VERSION "created by canmatrix"

NS_ :

BS_:

BU_: TCM iBooster HCU CIM SCM Right_Hand_Control Left_Hand_Control GPS VCM IC_2 XM GMRS Radio_CANtool Diagnostic_Tool_Digital_Wrench Information_System_Controller_1 STEERING_CONTROLLER VEHICLE_SECURITY RADIO_Hub ABS Battery_Management_Cntrl_2 Battery_Management_Cntrl_1 Auxiliary_Power_Unit_2 Auxiliary_Power_Unit_1 Electric_Propulsion_Cntrl_Unit_4 Electric_Propulsion_Cntrl_Unit_3 Electric_Propulsion_Cntrl_Unit_2 Electric_Propulsion_Cntrl_Unit_1 ECM IC

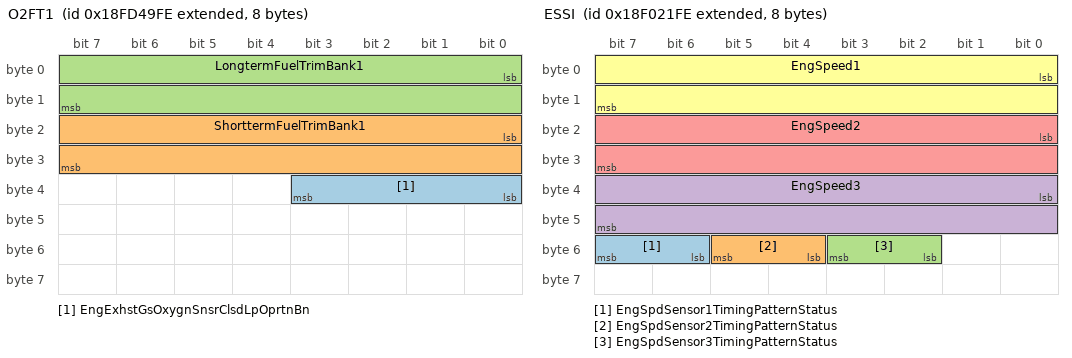
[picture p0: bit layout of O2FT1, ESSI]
BO_ 2566736382 O2FT1: 8 Vector__XXX
 SG_ EngExhstGsOxygnSnsrClsdLpOprtnBn : 32|4@1+ (1,0) [0.0|15.0] "" Vector__XXX
 SG_ ShorttermFuelTrimBank1 : 16|16@1+ (0.1,-100) [-100.0|100.0] "%" Vector__XXX
 SG_ LongtermFuelTrimBank1 : 0|16@1+ (0.1,-100) [-100.0|100.0] "%" Vector__XXX

BO_ 2565874174 ESSI: 8 Vector__XXX
 SG_ EngSpdSensor1TimingPatternStatus : 54|2@1+ (1,0) [0.0|3.0] "" Vector__XXX
 SG_ EngSpdSensor2TimingPatternStatus : 52|2@1+ (1,0) [0.0|3.0] "" Vector__XXX
 SG_ EngSpdSensor3TimingPatternStatus : 50|2@1+ (1,0) [0.0|3.0] "" Vector__XXX
 SG_ EngSpeed3 : 32|16@1+ (0.5,0) [0.0|32127.5] "rpm" Vector__XXX
 SG_ EngSpeed2 : 16|16@1+ (0.5,0) [0.0|32127.5] "rpm" Vector__XXX
 SG_ EngSpeed1 : 0|16@1+ (0.5,0) [0.0|32127.5] "rpm" Vector__XXX

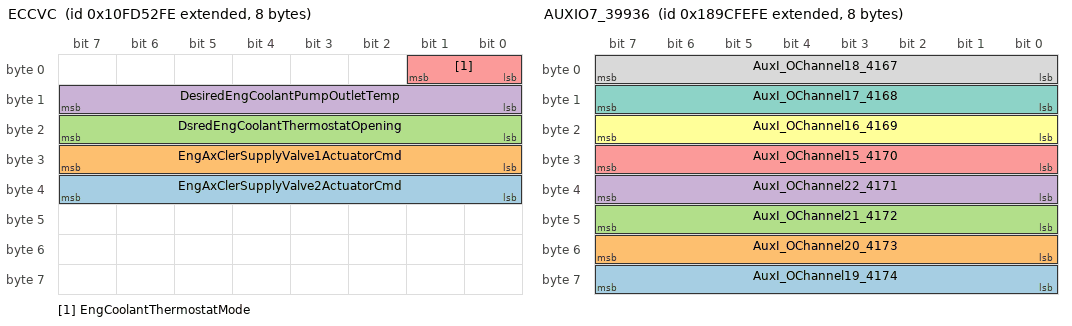
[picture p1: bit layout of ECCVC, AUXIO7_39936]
BO_ 2432520958 ECCVC: 8 Vector__XXX
 SG_ EngAxClerSupplyValve2ActuatorCmd : 32|8@1+ (0.4,0) [0.0|100.0] "%" Vector__XXX
 SG_ EngAxClerSupplyValve1ActuatorCmd : 24|8@1+ (0.4,0) [0.0|100.0] "%" Vector__XXX
 SG_ DsredEngCoolantThermostatOpening : 16|8@1+ (0.4,0) [0.0|100.0] "%" Vector__XXX
 SG_ DesiredEngCoolantPumpOutletTemp : 8|8@1+ (1,-40) [-40.0|210.0] "°C" Vector__XXX
 SG_ EngCoolantThermostatMode : 0|2@1+ (1,0) [0.0|3.0] "" Vector__XXX

BO_ 2560425726 AUXIO7_39936: 8 Vector__XXX
 SG_ AuxI_OChannel19_4174 : 56|8@1+ (1,0) [0.0|250.0] "" Vector__XXX
 SG_ AuxI_OChannel20_4173 : 48|8@1+ (1,0) [0.0|250.0] "" Vector__XXX
 SG_ AuxI_OChannel21_4172 : 40|8@1+ (1,0) [0.0|250.0] "" Vector__XXX
 SG_ AuxI_OChannel22_4171 : 32|8@1+ (1,0) [0.0|250.0] "" Vector__XXX
 SG_ AuxI_OChannel15_4170 : 24|8@1+ (1,0) [0.0|250.0] "" Vector__XXX
 SG_ AuxI_OChannel16_4169 : 16|8@1+ (1,0) [0.0|250.0] "" Vector__XXX
 SG_ AuxI_OChannel17_4168 : 8|8@1+ (1,0) [0.0|250.0] "" Vector__XXX
 SG_ AuxI_OChannel18_4167 : 0|8@1+ (1,0) [0.0|250.0] "" Vector__XXX

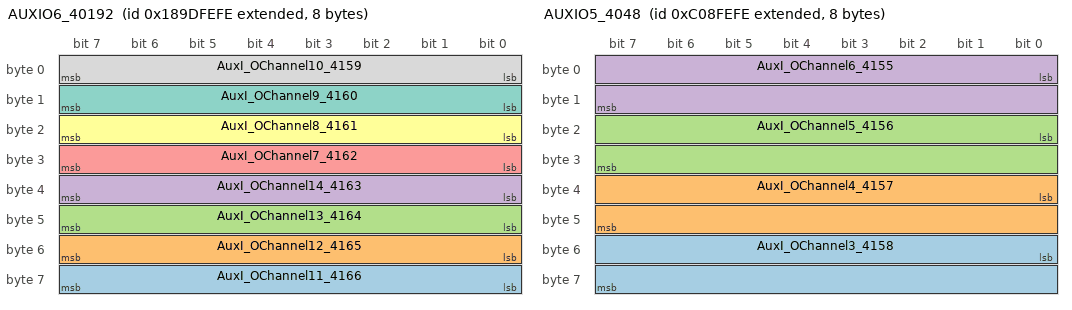
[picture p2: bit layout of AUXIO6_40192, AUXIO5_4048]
BO_ 2560491262 AUXIO6_40192: 8 Vector__XXX
 SG_ AuxI_OChannel11_4166 : 56|8@1+ (1,0) [0.0|250.0] "" Vector__XXX
 SG_ AuxI_OChannel12_4165 : 48|8@1+ (1,0) [0.0|250.0] "" Vector__XXX
 SG_ AuxI_OChannel13_4164 : 40|8@1+ (1,0) [0.0|250.0] "" Vector__XXX
 SG_ AuxI_OChannel14_4163 : 32|8@1+ (1,0) [0.0|250.0] "" Vector__XXX
 SG_ AuxI_OChannel7_4162 : 24|8@1+ (1,0) [0.0|250.0] "" Vector__XXX
 SG_ AuxI_OChannel8_4161 : 16|8@1+ (1,0) [0.0|250.0] "" Vector__XXX
 SG_ AuxI_OChannel9_4160 : 8|8@1+ (1,0) [0.0|250.0] "" Vector__XXX
 SG_ AuxI_OChannel10_4159 : 0|8@1+ (1,0) [0.0|250.0] "" Vector__XXX

BO_ 2349399806 AUXIO5_4048: 8 Vector__XXX
 SG_ AuxI_OChannel3_4158 : 48|16@1+ (1,0) [0.0|64255.0] "" Vector__XXX
 SG_ AuxI_OChannel4_4157 : 32|16@1+ (1,0) [0.0|64255.0] "" Vector__XXX
 SG_ AuxI_OChannel5_4156 : 16|16@1+ (1,0) [0.0|64255.0] "" Vector__XXX
 SG_ AuxI_OChannel6_4155 : 0|16@1+ (1,0) [0.0|64255.0] "" Vector__XXX

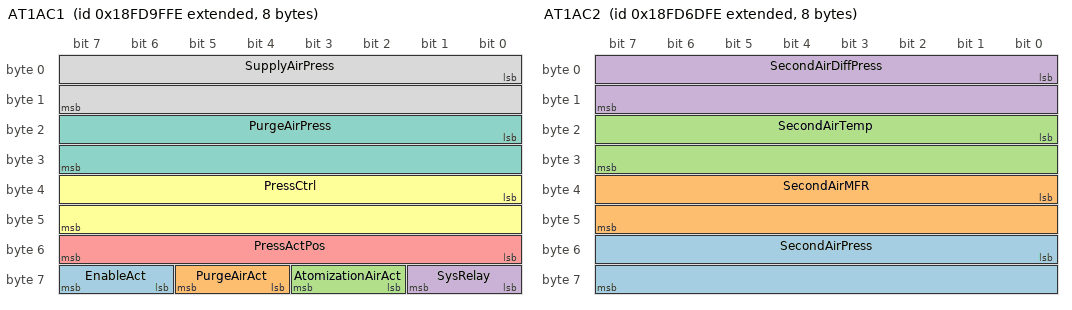
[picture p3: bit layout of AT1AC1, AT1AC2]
BO_ 2566758398 AT1AC1: 8 Vector__XXX
 SG_ EnableAct : 62|2@1+ (1,0) [0.0|3.0] "" Vector__XXX
 SG_ PurgeAirAct : 60|2@1+ (1,0) [0.0|3.0] "" Vector__XXX
 SG_ AtomizationAirAct : 58|2@1+ (1,0) [0.0|3.0] "" Vector__XXX
 SG_ SysRelay : 56|2@1+ (1,0) [0.0|3.0] "" Vector__XXX
 SG_ PressActPos : 48|8@1+ (0.4,0) [0.0|100.0] "%" Vector__XXX
 SG_ PressCtrl : 32|16@1+ (0.0025,0) [0.0|160.6375] "%" Vector__XXX
 SG_ PurgeAirPress : 16|16@1+ (0.1,0) [0.0|6425.5] "kPa" Vector__XXX
 SG_ SupplyAirPress : 0|16@1+ (0.1,0) [0.0|6425.5] "kPa" Vector__XXX

BO_ 2566745598 AT1AC2: 8 Vector__XXX
 SG_ SecondAirPress : 48|16@1+ (0.1,0) [0.0|6425.5] "kPa" Vector__XXX
 SG_ SecondAirMFR : 32|16@1+ (0.2,0) [0.0|12851.0] "kg/h" Vector__XXX
 SG_ SecondAirTemp : 16|16@1+ (0.03125,-273) [-273.0|1734.96875] "°C" Vector__XXX
 SG_ SecondAirDiffPress : 0|16@1+ (0.0078125,-250) [-250.0|251.99] "kPa" Vector__XXX

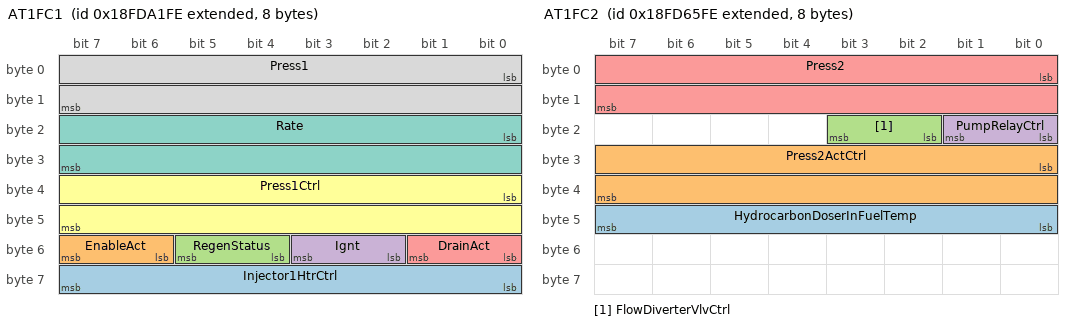
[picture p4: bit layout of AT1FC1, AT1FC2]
BO_ 2566758910 AT1FC1: 8 Vector__XXX
 SG_ Injector1HtrCtrl : 56|8@1+ (0.4,0) [0.0|100.0] "%" Vector__XXX
 SG_ EnableAct : 54|2@1+ (1,0) [0.0|3.0] "" Vector__XXX
 SG_ RegenStatus : 52|2@1+ (1,0) [0.0|3.0] "" Vector__XXX
 SG_ Ignt : 50|2@1+ (1,0) [0.0|3.0] "" Vector__XXX
 SG_ DrainAct : 48|2@1+ (1,0) [0.0|3.0] "" Vector__XXX
 SG_ Press1Ctrl : 32|16@1+ (0.0025,0) [0.0|160.6375] "%" Vector__XXX
 SG_ Rate : 16|16@1+ (0.05,0) [0.0|3212.75] "L/h" Vector__XXX
 SG_ Press1 : 0|16@1+ (0.1,0) [0.0|6425.5] "kPa" Vector__XXX

BO_ 2566743550 AT1FC2: 8 Vector__XXX
 SG_ HydrocarbonDoserInFuelTemp : 40|8@1+ (1,-40) [-40.0|210.0] "°C" Vector__XXX
 SG_ Press2ActCtrl : 24|16@1+ (0.0025,0) [0.0|160.6375] "%" Vector__XXX
 SG_ FlowDiverterVlvCtrl : 18|2@1+ (1,0) [0.0|3.0] "" Vector__XXX
 SG_ PumpRelayCtrl : 16|2@1+ (1,0) [0.0|3.0] "" Vector__XXX
 SG_ Press2 : 0|16@1+ (0.1,0) [0.0|6425.5] "kPa" Vector__XXX

BO_ 2566753534 AT1GP: 8 Vector__XXX
 SG_ DPFOutPress : 16|16@1+ (0.1,0) [0.0|6425.5] "kPa" Vector__XXX
 SG_ DPFInPress : 0|16@1+ (0.1,0) [0.0|6425.5] "kPa" Vector__XXX

BO_ 2566756606 AT1HI1: 8 Vector__XXX
 SG_ DPFAvgDistBetweenActiveRegens : 288|32@1+ (0.125,0) [0.0|526385151.875] "km" Vector__XXX
 SG_ DPFAvgTimeBetweenActiveRegens : 256|32@1+ (1,0) [0.0|4211081215.0] "s" Vector__XXX
 SG_ DPFTotalNumOfActiveRegenManReq : 224|32@1+ (1,0) [0.0|4211081215.0] "" Vector__XXX
 SG_ DPFTotalNumOfActiveRegenInhReq : 192|32@1+ (1,0) [0.0|4211081215.0] "" Vector__XXX
 SG_ DPFTotalNumOfPassiveRegens : 160|32@1+ (1,0) [0.0|4211081215.0] "" Vector__XXX
 SG_ DPFTotalPassiveRegenTime : 128|32@1+ (1,0) [0.0|4211081215.0] "s" Vector__XXX
 SG_ TotalNumOfActiveRegens : 96|32@1+ (1,0) [0.0|4211081215.0] "" Vector__XXX
 SG_ TotalDisdTime : 64|32@1+ (1,0) [0.0|4211081215.0] "s" Vector__XXX
 SG_ TotalRegenTime : 32|32@1+ (1,0) [0.0|4211081215.0] "s" Vector__XXX
 SG_ TotalFuelUsed : 0|32@1+ (0.5,0) [0.0|2105540607.5] "L" Vector__XXX

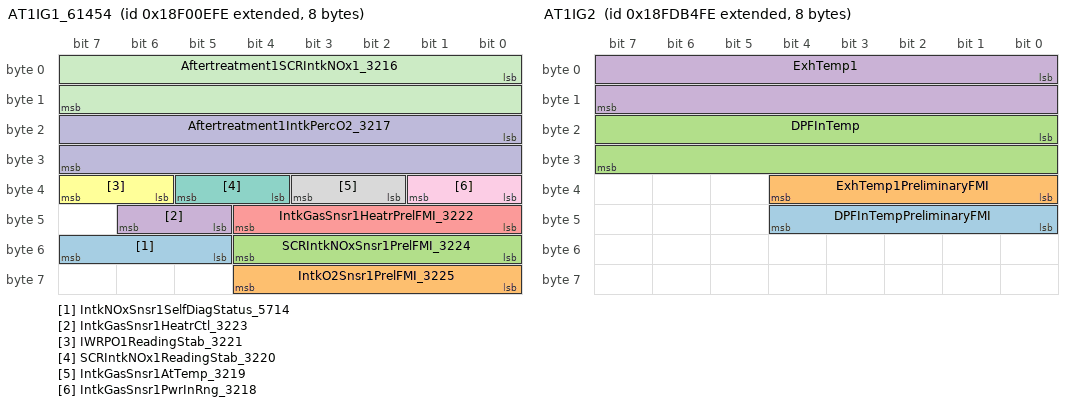
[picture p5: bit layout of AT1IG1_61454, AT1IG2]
BO_ 2565869310 AT1IG1_61454: 8 Vector__XXX
 SG_ IntkNOxSnsr1SelfDiagStatus_5714 : 53|3@1+ (1,0) [0.0|7.0] "" Vector__XXX
 SG_ IntkO2Snsr1PrelFMI_3225 : 56|5@1+ (1,0) [0.0|31.0] "" Vector__XXX
 SG_ SCRIntkNOxSnsr1PrelFMI_3224 : 48|5@1+ (1,0) [0.0|31.0] "" Vector__XXX
 SG_ IntkGasSnsr1HeatrCtl_3223 : 45|2@1+ (1,0) [0.0|3.0] "" Vector__XXX
 SG_ IntkGasSnsr1HeatrPrelFMI_3222 : 40|5@1+ (1,0) [0.0|31.0] "" Vector__XXX
 SG_ IWRPO1ReadingStab_3221 : 38|2@1+ (1,0) [0.0|3.0] "" Vector__XXX
 SG_ SCRIntkNOx1ReadingStab_3220 : 36|2@1+ (1,0) [0.0|3.0] "" Vector__XXX
 SG_ IntkGasSnsr1AtTemp_3219 : 34|2@1+ (1,0) [0.0|3.0] "" Vector__XXX
 SG_ IntkGasSnsr1PwrInRng_3218 : 32|2@1+ (1,0) [0.0|3.0] "" Vector__XXX
 SG_ Aftertreatment1IntkPercO2_3217 : 16|16@1+ (0.000514,-12) [-12.0|21.02707] "%" Vector__XXX
 SG_ Aftertreatment1SCRIntkNOx1_3216 : 0|16@1+ (0.05,-200) [-200.0|3012.75] "ppm" Vector__XXX

BO_ 2566763774 AT1IG2: 8 Vector__XXX
 SG_ DPFInTempPreliminaryFMI : 40|5@1+ (1,0) [0.0|31.0] "" Vector__XXX
 SG_ ExhTemp1PreliminaryFMI : 32|5@1+ (1,0) [0.0|31.0] "" Vector__XXX
 SG_ DPFInTemp : 16|16@1+ (0.03125,-273) [-273.0|1734.96875] "°C" Vector__XXX
 SG_ ExhTemp1 : 0|16@1+ (0.03125,-273) [-273.0|1734.96875] "°C" Vector__XXX

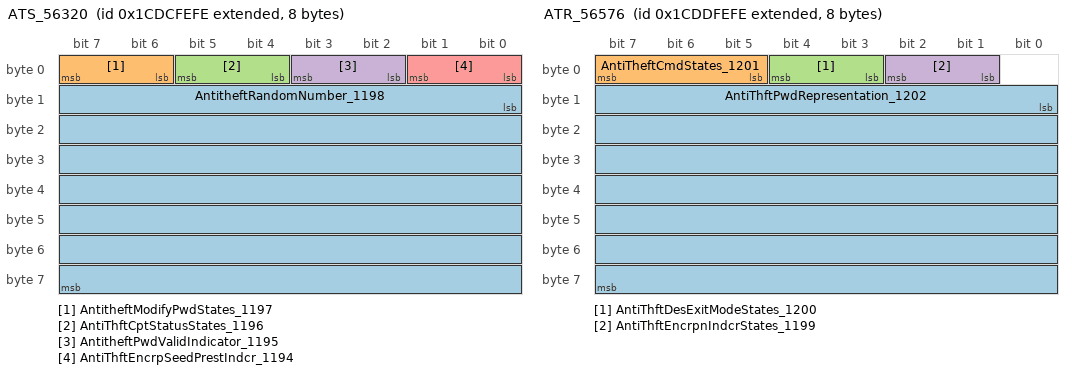
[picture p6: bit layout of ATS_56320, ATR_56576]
BO_ 2631728894 ATS_56320: 8 Vector__XXX
 SG_ AntitheftRandomNumber_1198 : 8|56@1+ (1,0) [0.0|255.0] "" Vector__XXX
 SG_ AntitheftModifyPwdStates_1197 : 6|2@1+ (1,0) [0.0|3.0] "" Vector__XXX
 SG_ AntiThftCptStatusStates_1196 : 4|2@1+ (1,0) [0.0|3.0] "" Vector__XXX
 SG_ AntitheftPwdValidIndicator_1195 : 2|2@1+ (1,0) [0.0|3.0] "" Vector__XXX
 SG_ AntiThftEncrpSeedPrestIndcr_1194 : 0|2@1+ (1,0) [0.0|3.0] "" Vector__XXX

BO_ 2631794430 ATR_56576: 8 Vector__XXX
 SG_ AntiThftPwdRepresentation_1202 : 8|56@1+ (1,0) [0.0|255.0] "" Vector__XXX
 SG_ AntiTheftCmdStates_1201 : 5|3@1+ (1,0) [0.0|7.0] "" Vector__XXX
 SG_ AntiThftDesExitModeStates_1200 : 3|2@1+ (1,0) [0.0|3.0] "" Vector__XXX
 SG_ AntiThftEncrpnIndcrStates_1199 : 1|2@1+ (1,0) [0.0|3.0] "" Vector__XXX

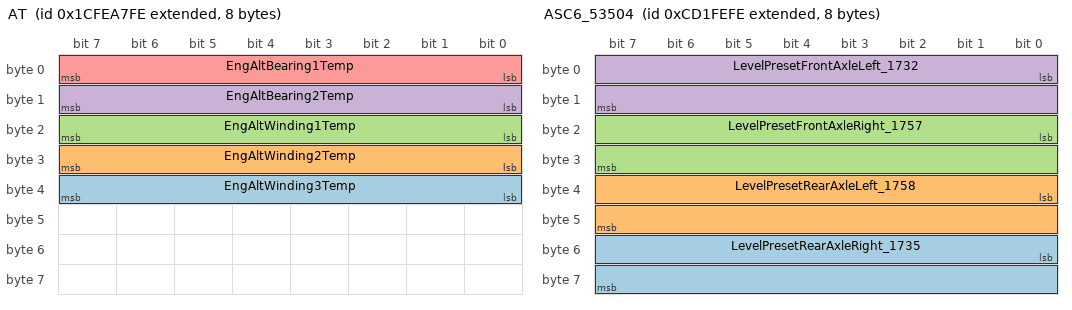
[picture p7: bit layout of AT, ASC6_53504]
BO_ 2633934846 AT: 8 Vector__XXX
 SG_ EngAltWinding3Temp : 32|8@1+ (1,-40) [-40.0|210.0] "°C" Vector__XXX
 SG_ EngAltWinding2Temp : 24|8@1+ (1,-40) [-40.0|210.0] "°C" Vector__XXX
 SG_ EngAltWinding1Temp : 16|8@1+ (1,-40) [-40.0|210.0] "°C" Vector__XXX
 SG_ EngAltBearing2Temp : 8|8@1+ (1,-40) [-40.0|210.0] "°C" Vector__XXX
 SG_ EngAltBearing1Temp : 0|8@1+ (1,-40) [-40.0|210.0] "°C" Vector__XXX

BO_ 2362572542 ASC6_53504: 8 Vector__XXX
 SG_ LevelPresetRearAxleRight_1735 : 48|16@1+ (0.1,-3200) [-3200.0|3225.5] "mm" Vector__XXX
 SG_ LevelPresetRearAxleLeft_1758 : 32|16@1+ (0.1,-3200) [-3200.0|3225.5] "mm" Vector__XXX
 SG_ LevelPresetFrontAxleRight_1757 : 16|16@1+ (0.1,-3200) [-3200.0|3225.5] "mm" Vector__XXX
 SG_ LevelPresetFrontAxleLeft_1732 : 0|16@1+ (0.1,-3200) [-3200.0|3225.5] "mm" Vector__XXX

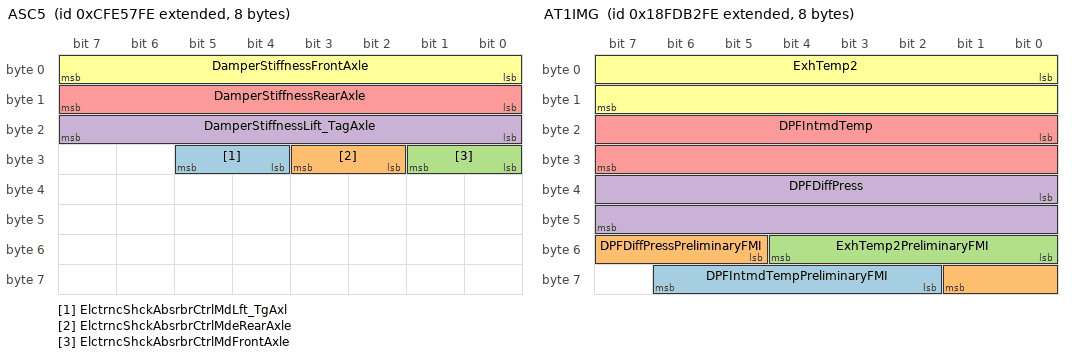
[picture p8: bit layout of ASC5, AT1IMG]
BO_ 2365478910 ASC5: 8 Vector__XXX
 SG_ ElctrncShckAbsrbrCtrlMdLft_TgAxl : 28|2@1+ (1,0) [0.0|3.0] "" Vector__XXX
 SG_ ElctrncShckAbsrbrCtrlMdeRearAxle : 26|2@1+ (1,0) [0.0|3.0] "" Vector__XXX
 SG_ ElctrncShckAbsrbrCtrlMdFrontAxle : 24|2@1+ (1,0) [0.0|3.0] "" Vector__XXX
 SG_ DamperStiffnessLift_TagAxle : 16|8@1+ (0.4,0) [0.0|100.0] "%" Vector__XXX
 SG_ DamperStiffnessRearAxle : 8|8@1+ (0.4,0) [0.0|100.0] "%" Vector__XXX
 SG_ DamperStiffnessFrontAxle : 0|8@1+ (0.4,0) [0.0|100.0] "%" Vector__XXX

BO_ 2560950014 DM30_41984: 12 Vector__XXX
 SG_ SPN1_1214 : 8|16@1+ (1,0) [0.0|65536.0] "" Vector__XXX
 SG_ TestLimitMinimum_4112 : 80|16@1+ (1,0) [0.0|64255.0] "" Vector__XXX
 SG_ FailureModeIdentifier1_1215 : 24|5@1+ (1,0) [0.0|0.0] "" Vector__XXX
 SG_ TestLimitMaximum_4111 : 64|16@1+ (1,0) [0.0|64255.0] "" Vector__XXX
 SG_ TestValue_4110 : 48|16@1+ (1,0) [0.0|64255.0] "" Vector__XXX
 SG_ SlotId_4109 : 32|16@1+ (1,0) [0.0|64255.0] "" Vector__XXX
 SG_ TestIdentifier : 0|8@1+ (1,0) [0.0|255.0] "" Vector__XXX
 SG_ SPN1High : 29|3@1+ (1,0) [0.0|7.0] "" Vector__XXX

BO_ 2566763262 AT1IMG: 8 Vector__XXX
 SG_ DPFIntmdTempPreliminaryFMI : 58|5@1+ (1,0) [0.0|31.0] "" Vector__XXX
 SG_ DPFDiffPressPreliminaryFMI : 53|5@1+ (1,0) [0.0|31.0] "" Vector__XXX
 SG_ ExhTemp2PreliminaryFMI : 48|5@1+ (1,0) [0.0|31.0] "" Vector__XXX
 SG_ DPFDiffPress : 32|16@1+ (0.1,0) [0.0|6425.5] "kPa" Vector__XXX
 SG_ DPFIntmdTemp : 16|16@1+ (0.03125,-273) [-273.0|1734.96875] "°C" Vector__XXX
 SG_ ExhTemp2 : 0|16@1+ (0.03125,-273) [-273.0|1734.96875] "°C" Vector__XXX

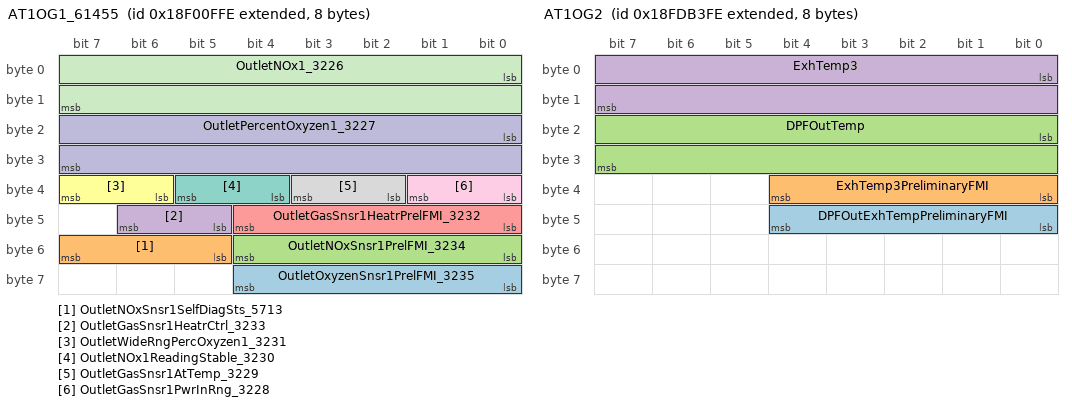
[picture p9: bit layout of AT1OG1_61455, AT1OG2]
BO_ 2565869566 AT1OG1_61455: 8 Vector__XXX
 SG_ OutletOxyzenSnsr1PrelFMI_3235 : 56|5@1+ (1,0) [0.0|31.0] "" Vector__XXX
 SG_ OutletNOxSnsr1SelfDiagSts_5713 : 53|3@1+ (1,0) [0.0|7.0] "" Vector__XXX
 SG_ OutletNOxSnsr1PrelFMI_3234 : 48|5@1+ (1,0) [0.0|31.0] "" Vector__XXX
 SG_ OutletGasSnsr1HeatrCtrl_3233 : 45|2@1+ (1,0) [0.0|3.0] "" Vector__XXX
 SG_ OutletGasSnsr1HeatrPrelFMI_3232 : 40|5@1+ (1,0) [0.0|31.0] "" Vector__XXX
 SG_ OutletWideRngPercOxyzen1_3231 : 38|2@1+ (1,0) [0.0|3.0] "" Vector__XXX
 SG_ OutletNOx1ReadingStable_3230 : 36|2@1+ (1,0) [0.0|3.0] "" Vector__XXX
 SG_ OutletGasSnsr1AtTemp_3229 : 34|2@1+ (1,0) [0.0|3.0] "" Vector__XXX
 SG_ OutletGasSnsr1PwrInRng_3228 : 32|2@1+ (1,0) [0.0|3.0] "" Vector__XXX
 SG_ OutletPercentOxyzen1_3227 : 16|16@1+ (0.000514,-12) [-12.0|21.02707] "%" Vector__XXX
 SG_ OutletNOx1_3226 : 0|16@1+ (0.05,-200) [-200.0|3012.75] "ppm" Vector__XXX

BO_ 2566763518 AT1OG2: 8 Vector__XXX
 SG_ DPFOutExhTempPreliminaryFMI : 40|5@1+ (1,0) [0.0|31.0] "" Vector__XXX
 SG_ ExhTemp3PreliminaryFMI : 32|5@1+ (1,0) [0.0|31.0] "" Vector__XXX
 SG_ DPFOutTemp : 16|16@1+ (0.03125,-273) [-273.0|1734.96875] "°C" Vector__XXX
 SG_ ExhTemp3 : 0|16@1+ (0.03125,-273) [-273.0|1734.96875] "°C" Vector__XXX

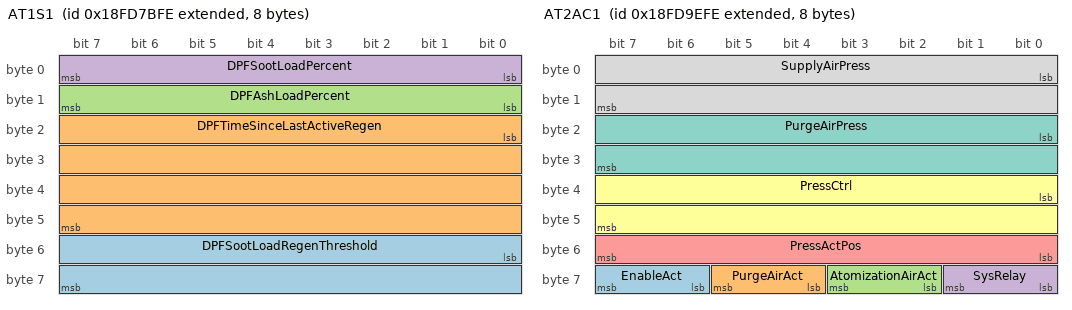
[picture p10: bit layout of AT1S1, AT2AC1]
BO_ 2566749182 AT1S1: 8 Vector__XXX
 SG_ DPFSootLoadRegenThreshold : 48|16@1+ (0.0025,0) [0.0|160.6375] "%" Vector__XXX
 SG_ DPFTimeSinceLastActiveRegen : 16|32@1+ (1,0) [0.0|4211081215.0] "s" Vector__XXX
 SG_ DPFAshLoadPercent : 8|8@1+ (1,0) [0.0|250.0] "%" Vector__XXX
 SG_ DPFSootLoadPercent : 0|8@1+ (1,0) [0.0|250.0] "%" Vector__XXX

BO_ 2566748670 AT1TI: 32 Vector__XXX
 SG_ DPFTripNumOfActiveRegenManReq : 224|32@1+ (1,0) [0.0|4211081215.0] "" Vector__XXX
 SG_ DPFTripNumOfActiveRegenInhReq : 192|32@1+ (1,0) [0.0|4211081215.0] "" Vector__XXX
 SG_ DPFTripNumOfPassiveRegens : 160|32@1+ (1,0) [0.0|4211081215.0] "" Vector__XXX
 SG_ DPFTripPassiveRegenTime : 128|32@1+ (1,0) [0.0|4211081215.0] "s" Vector__XXX
 SG_ DPFTripNumOfActiveRegens : 96|32@1+ (1,0) [0.0|4211081215.0] "" Vector__XXX
 SG_ DPFTripDisdTime : 64|32@1+ (1,0) [0.0|4211081215.0] "s" Vector__XXX
 SG_ DPFTripActiveRegenTime : 32|32@1+ (1,0) [0.0|4211081215.0] "s" Vector__XXX
 SG_ DPFTripFuelUsed : 0|32@1+ (0.5,0) [0.0|2105540607.5] "L" Vector__XXX

BO_ 2566758142 AT2AC1: 8 Vector__XXX
 SG_ EnableAct : 62|2@1+ (1,0) [0.0|3.0] "" Vector__XXX
 SG_ PurgeAirAct : 60|2@1+ (1,0) [0.0|3.0] "" Vector__XXX
 SG_ AtomizationAirAct : 58|2@1+ (1,0) [0.0|3.0] "" Vector__XXX
 SG_ SysRelay : 56|2@1+ (1,0) [0.0|3.0] "" Vector__XXX
 SG_ PressActPos : 48|8@1+ (0.4,0) [0.0|100.0] "%" Vector__XXX
 SG_ PressCtrl : 32|16@1+ (0.0025,0) [0.0|160.6375] "%" Vector__XXX
 SG_ PurgeAirPress : 16|16@1+ (0.1,0) [0.0|6425.5] "kPa" Vector__XXX
 SG_ SupplyAirPress : 0|16@1+ (0.1,0) [0.0|6425.5] "kPa" Vector__XXX

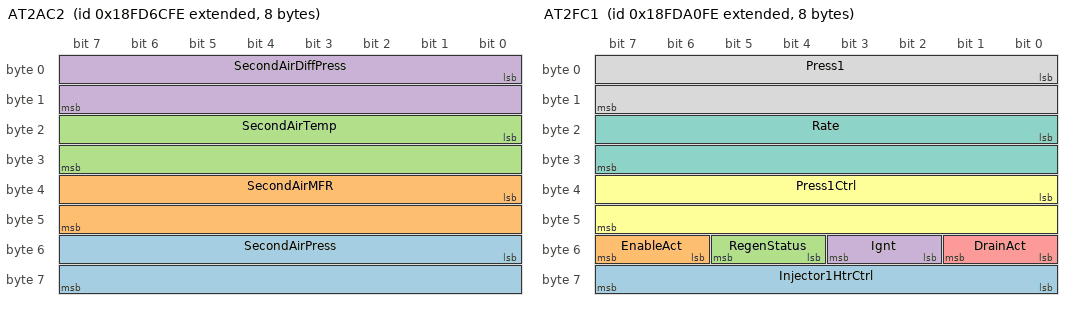
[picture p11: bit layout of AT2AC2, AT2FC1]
BO_ 2566745342 AT2AC2: 8 Vector__XXX
 SG_ SecondAirPress : 48|16@1+ (0.1,0) [0.0|6425.5] "kPa" Vector__XXX
 SG_ SecondAirMFR : 32|16@1+ (0.2,0) [0.0|12851.0] "kg/h" Vector__XXX
 SG_ SecondAirTemp : 16|16@1+ (0.03125,-273) [-273.0|1734.96875] "°C" Vector__XXX
 SG_ SecondAirDiffPress : 0|16@1+ (0.0078125,-250) [-250.0|251.99] "kPa" Vector__XXX

BO_ 2566758654 AT2FC1: 8 Vector__XXX
 SG_ Injector1HtrCtrl : 56|8@1+ (0.4,0) [0.0|100.0] "%" Vector__XXX
 SG_ EnableAct : 54|2@1+ (1,0) [0.0|3.0] "" Vector__XXX
 SG_ RegenStatus : 52|2@1+ (1,0) [0.0|3.0] "" Vector__XXX
 SG_ Ignt : 50|2@1+ (1,0) [0.0|3.0] "" Vector__XXX
 SG_ DrainAct : 48|2@1+ (1,0) [0.0|3.0] "" Vector__XXX
 SG_ Press1Ctrl : 32|16@1+ (0.0025,0) [0.0|160.6375] "%" Vector__XXX
 SG_ Rate : 16|16@1+ (0.05,0) [0.0|3212.75] "L/h" Vector__XXX
 SG_ Press1 : 0|16@1+ (0.1,0) [0.0|6425.5] "kPa" Vector__XXX

BO_ 2566753278 AT2GP: 8 Vector__XXX
 SG_ DPFOutPress : 16|16@1+ (0.1,0) [0.0|6425.5] "kPa" Vector__XXX
 SG_ DPFInPress : 0|16@1+ (0.1,0) [0.0|6425.5] "kPa" Vector__XXX

BO_ 2566756862 AT2HI1: 8 Vector__XXX
 SG_ DPFAvgDistBetweenActiveRegens : 288|32@1+ (0.125,0) [0.0|526385151.875] "km" Vector__XXX
 SG_ DPFAvgTimeBetweenActiveRegens : 256|32@1+ (1,0) [0.0|4211081215.0] "s" Vector__XXX
 SG_ DPFTotalNumOfActiveRegenManReq : 224|32@1+ (1,0) [0.0|4211081215.0] "" Vector__XXX
 SG_ DPFTotalNumOfActiveRegenInhReq : 192|32@1+ (1,0) [0.0|4211081215.0] "" Vector__XXX
 SG_ DPFTotalNumOfPassiveRegens : 160|32@1+ (1,0) [0.0|4211081215.0] "" Vector__XXX
 SG_ DPFTotalPassiveRegenTime : 128|32@1+ (1,0) [0.0|4211081215.0] "s" Vector__XXX
 SG_ TotalNumOfActiveRegens : 96|32@1+ (1,0) [0.0|4211081215.0] "" Vector__XXX
 SG_ TotalDisdTime : 64|32@1+ (1,0) [0.0|4211081215.0] "s" Vector__XXX
 SG_ TotalRegenTime : 32|32@1+ (1,0) [0.0|4211081215.0] "s" Vector__XXX
 SG_ TotalFuelUsed : 0|32@1+ (0.5,0) [0.0|2105540607.5] "L" Vector__XXX

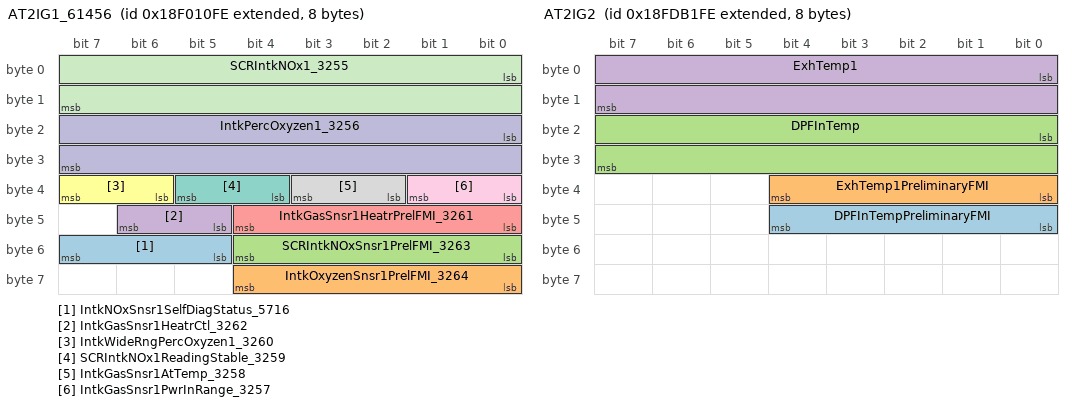
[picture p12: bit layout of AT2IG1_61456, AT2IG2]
BO_ 2565869822 AT2IG1_61456: 8 Vector__XXX
 SG_ IntkNOxSnsr1SelfDiagStatus_5716 : 53|3@1+ (1,0) [0.0|7.0] "" Vector__XXX
 SG_ IntkOxyzenSnsr1PrelFMI_3264 : 56|5@1+ (1,0) [0.0|31.0] "" Vector__XXX
 SG_ SCRIntkNOxSnsr1PrelFMI_3263 : 48|5@1+ (1,0) [0.0|31.0] "" Vector__XXX
 SG_ IntkGasSnsr1HeatrCtl_3262 : 45|2@1+ (1,0) [0.0|3.0] "" Vector__XXX
 SG_ IntkGasSnsr1HeatrPrelFMI_3261 : 40|5@1+ (1,0) [0.0|31.0] "" Vector__XXX
 SG_ IntkWideRngPercOxyzen1_3260 : 38|2@1+ (1,0) [0.0|3.0] "" Vector__XXX
 SG_ SCRIntkNOx1ReadingStable_3259 : 36|2@1+ (1,0) [0.0|3.0] "" Vector__XXX
 SG_ IntkGasSnsr1AtTemp_3258 : 34|2@1+ (1,0) [0.0|3.0] "" Vector__XXX
 SG_ IntkGasSnsr1PwrInRange_3257 : 32|2@1+ (1,0) [0.0|3.0] "" Vector__XXX
 SG_ IntkPercOxyzen1_3256 : 16|16@1+ (0.000514,-12) [-12.0|21.02707] "%" Vector__XXX
 SG_ SCRIntkNOx1_3255 : 0|16@1+ (0.05,-200) [-200.0|3012.75] "ppm" Vector__XXX

BO_ 2566763006 AT2IG2: 8 Vector__XXX
 SG_ DPFInTempPreliminaryFMI : 40|5@1+ (1,0) [0.0|31.0] "" Vector__XXX
 SG_ ExhTemp1PreliminaryFMI : 32|5@1+ (1,0) [0.0|31.0] "" Vector__XXX
 SG_ DPFInTemp : 16|16@1+ (0.03125,-273) [-273.0|1734.96875] "°C" Vector__XXX
 SG_ ExhTemp1 : 0|16@1+ (0.03125,-273) [-273.0|1734.96875] "°C" Vector__XXX

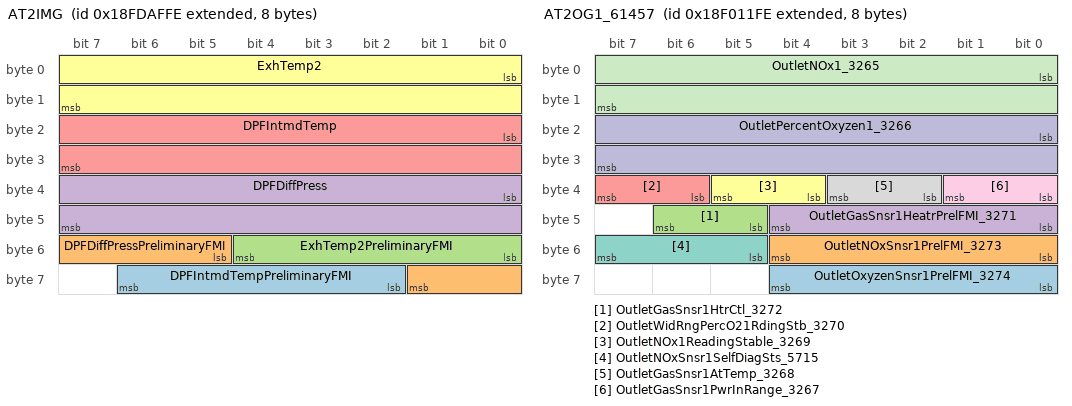
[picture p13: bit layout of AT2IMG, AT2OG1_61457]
BO_ 2566762494 AT2IMG: 8 Vector__XXX
 SG_ DPFIntmdTempPreliminaryFMI : 58|5@1+ (1,0) [0.0|31.0] "" Vector__XXX
 SG_ DPFDiffPressPreliminaryFMI : 53|5@1+ (1,0) [0.0|31.0] "" Vector__XXX
 SG_ ExhTemp2PreliminaryFMI : 48|5@1+ (1,0) [0.0|31.0] "" Vector__XXX
 SG_ DPFDiffPress : 32|16@1+ (0.1,0) [0.0|6425.5] "kPa" Vector__XXX
 SG_ DPFIntmdTemp : 16|16@1+ (0.03125,-273) [-273.0|1734.96875] "°C" Vector__XXX
 SG_ ExhTemp2 : 0|16@1+ (0.03125,-273) [-273.0|1734.96875] "°C" Vector__XXX

BO_ 2565870078 AT2OG1_61457: 8 Vector__XXX
 SG_ OutletOxyzenSnsr1PrelFMI_3274 : 56|5@1+ (1,0) [0.0|31.0] "" Vector__XXX
 SG_ OutletNOxSnsr1PrelFMI_3273 : 48|5@1+ (1,0) [0.0|31.0] "" Vector__XXX
 SG_ OutletGasSnsr1HtrCtl_3272 : 45|2@1+ (1,0) [0.0|3.0] "" Vector__XXX
 SG_ OutletGasSnsr1HeatrPrelFMI_3271 : 40|5@1+ (1,0) [0.0|31.0] "" Vector__XXX
 SG_ OutletWidRngPercO21RdingStb_3270 : 38|2@1+ (1,0) [0.0|3.0] "" Vector__XXX
 SG_ OutletNOx1ReadingStable_3269 : 36|2@1+ (1,0) [0.0|3.0] "" Vector__XXX
 SG_ OutletNOxSnsr1SelfDiagSts_5715 : 53|3@1+ (1,0) [0.0|7.0] "" Vector__XXX
 SG_ OutletGasSnsr1AtTemp_3268 : 34|2@1+ (1,0) [0.0|3.0] "" Vector__XXX
 SG_ OutletGasSnsr1PwrInRange_3267 : 32|2@1+ (1,0) [0.0|3.0] "" Vector__XXX
 SG_ OutletPercentOxyzen1_3266 : 16|16@1+ (0.000514,-12) [-12.0|21.02707] "%" Vector__XXX
 SG_ OutletNOx1_3265 : 0|16@1+ (0.05,-200) [-200.0|3012.75] "ppm" Vector__XXX

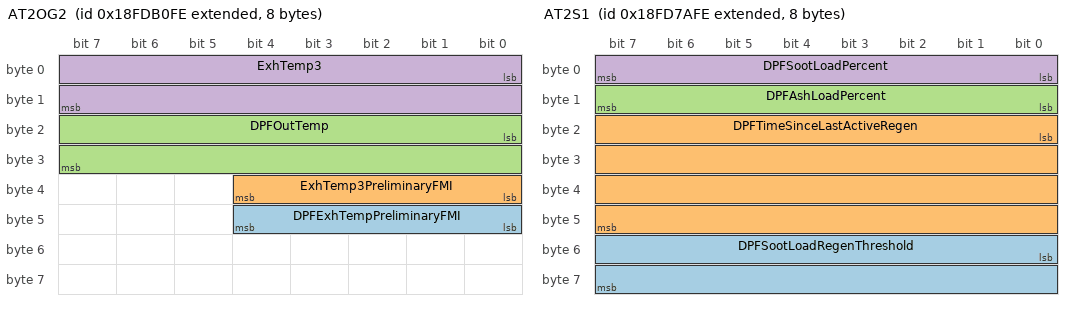
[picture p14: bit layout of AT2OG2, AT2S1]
BO_ 2566762750 AT2OG2: 8 Vector__XXX
 SG_ DPFExhTempPreliminaryFMI : 40|5@1+ (1,0) [0.0|31.0] "" Vector__XXX
 SG_ ExhTemp3PreliminaryFMI : 32|5@1+ (1,0) [0.0|31.0] "" Vector__XXX
 SG_ DPFOutTemp : 16|16@1+ (0.03125,-273) [-273.0|1734.96875] "°C" Vector__XXX
 SG_ ExhTemp3 : 0|16@1+ (0.03125,-273) [-273.0|1734.96875] "°C" Vector__XXX

BO_ 2566748926 AT2S1: 8 Vector__XXX
 SG_ DPFSootLoadRegenThreshold : 48|16@1+ (0.0025,0) [0.0|160.6375] "%" Vector__XXX
 SG_ DPFTimeSinceLastActiveRegen : 16|32@1+ (1,0) [0.0|4211081215.0] "s" Vector__XXX
 SG_ DPFAshLoadPercent : 8|8@1+ (1,0) [0.0|250.0] "%" Vector__XXX
 SG_ DPFSootLoadPercent : 0|8@1+ (1,0) [0.0|250.0] "%" Vector__XXX

BO_ 2566748414 AT2TI: 32 Vector__XXX
 SG_ DPFTripNumOfActiveRegenManReq : 224|32@1+ (1,0) [0.0|4211081215.0] "" Vector__XXX
 SG_ DPFTripNumOfActiveRegenInhReq : 192|32@1+ (1,0) [0.0|4211081215.0] "" Vector__XXX
 SG_ DPFTripNumOfPassiveRegens : 160|32@1+ (1,0) [0.0|4211081215.0] "" Vector__XXX
 SG_ DPFTripPassiveRegenTime : 128|32@1+ (1,0) [0.0|4211081215.0] "s" Vector__XXX
 SG_ DPFTripNumOfActiveRegens : 96|32@1+ (1,0) [0.0|4211081215.0] "" Vector__XXX
 SG_ DPFTripDisdTime : 64|32@1+ (1,0) [0.0|4211081215.0] "s" Vector__XXX
 SG_ DPFTripActiveRegenTime : 32|32@1+ (1,0) [0.0|4211081215.0] "s" Vector__XXX
 SG_ DPFTripFuelUsed : 0|32@1+ (0.5,0) [0.0|2105540607.5] "L" Vector__XXX

BO_ 2365428478 EOI: 8 Vector__XXX
 SG_ EngDesiredTorqueRq : 48|8@1+ (1,-125) [0.0|125.0] "%" Vector__XXX
 SG_ EngColdAmbientElevatedIdleStatus : 46|2@1+ (1,0) [0.0|3.0] "" Vector__XXX
 SG_ EngStarterMotorRelayCtrl : 6|2@1+ (1,0) [0.0|3.0] "" Vector__XXX
 SG_ EngDerateRq : 56|8@1+ (0.4,0) [0.0|100.0] "%" Vector__XXX
 SG_ EngEmergencyShutdownIndication : 44|2@1+ (1,0) [0.0|3.0] "" Vector__XXX
 SG_ EngControlledShutdownRq : 42|2@1+ (1,0) [0.0|3.0] "" Vector__XXX
 SG_ EngCoolantCirculatingPumpCtrl : 40|2@1+ (1,0) [0.0|3.0] "" Vector__XXX
 SG_ EngBlock_CoolantPreheaterCtrl : 38|2@1+ (1,0) [0.0|3.0] "" Vector__XXX
 SG_ EngElctrclSystmPwrCnsrvationCtrl : 36|2@1+ (1,0) [0.0|3.0] "" Vector__XXX
 SG_ EngOilPreheaterCtrl : 34|2@1+ (1,0) [0.0|3.0] "" Vector__XXX
 SG_ EngOilPrimingPumpCtrl : 32|2@1+ (1,0) [0.0|3.0] "" Vector__XXX
 SG_ EngFuelShutoffValveLeakTestCtrl : 30|2@1+ (1,0) [0.0|3.0] "" Vector__XXX
 SG_ EngFuelShutoff2Ctrl : 28|2@1+ (1,0) [0.0|3.0] "" Vector__XXX
 SG_ EngFuelShutoff1Ctrl : 26|2@1+ (1,0) [0.0|3.0] "" Vector__XXX
 SG_ EngFuelShutoffVentCtrl : 24|2@1+ (1,0) [0.0|3.0] "" Vector__XXX
 SG_ TimeRemainingInEngOperatingState : 8|16@1+ (1,0) [0.0|64255.0] "s" Vector__XXX
 SG_ FuelPumpPrimerCtrl : 4|2@1+ (1,0) [0.0|3.0] "" Vector__XXX
 SG_ EngOperatingState : 0|4@1+ (1,0) [0.0|15.0] "" Vector__XXX

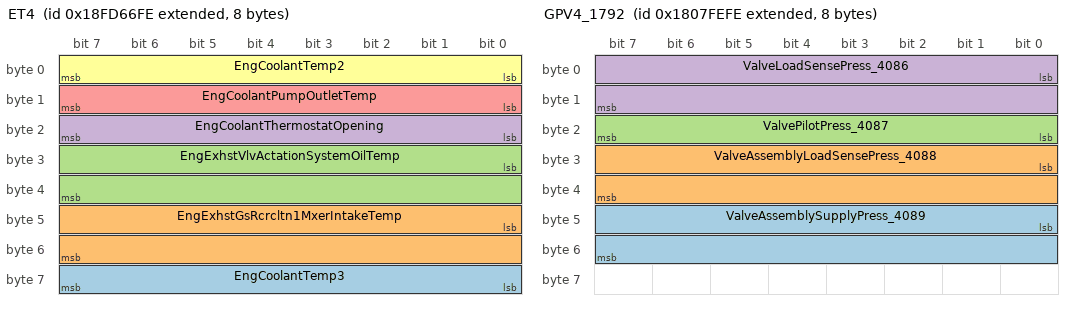
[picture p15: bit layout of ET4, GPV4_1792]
BO_ 2566743806 ET4: 8 Vector__XXX
 SG_ EngCoolantTemp3 : 56|8@1+ (1,-40) [-40.0|210.0] "°C" Vector__XXX
 SG_ EngExhstGsRcrcltn1MxerIntakeTemp : 40|16@1+ (0.03125,-273) [-273.0|1734.96875] "°C" Vector__XXX
 SG_ EngExhstVlvActationSystemOilTemp : 24|16@1+ (0.03125,-273) [-273.0|1734.96875] "°C" Vector__XXX
 SG_ EngCoolantThermostatOpening : 16|8@1+ (0.4,0) [0.0|100.0] "%" Vector__XXX
 SG_ EngCoolantPumpOutletTemp : 8|8@1+ (1,-40) [-40.0|210.0] "°C" Vector__XXX
 SG_ EngCoolantTemp2 : 0|8@1+ (1,-40) [-40.0|210.0] "°C" Vector__XXX

BO_ 2499635454 GCVW: 8 Vector__XXX
 SG_ NetVehicleWeightChange : 24|24@1+ (2,-1.64495e+07) [-16449535.0|16449535.0] "kg" Vector__XXX
 SG_ GrossCombinationWeight : 0|24@1+ (2,0) [0.0|32899070.0] "kg" Vector__XXX

BO_ 2550660862 GPV4_1792: 8 Vector__XXX
 SG_ ValveAssemblySupplyPress_4089 : 40|16@1+ (5,0) [0.0|321275.0] "kPa" Vector__XXX
 SG_ ValveAssemblyLoadSensePress_4088 : 24|16@1+ (5,0) [0.0|321275.0] "kPa" Vector__XXX
 SG_ ValvePilotPress_4087 : 16|8@1+ (16,0) [0.0|4000.0] "kPa" Vector__XXX
 SG_ ValveLoadSensePress_4086 : 0|16@1+ (5,0) [0.0|321275.0] "kPa" Vector__XXX

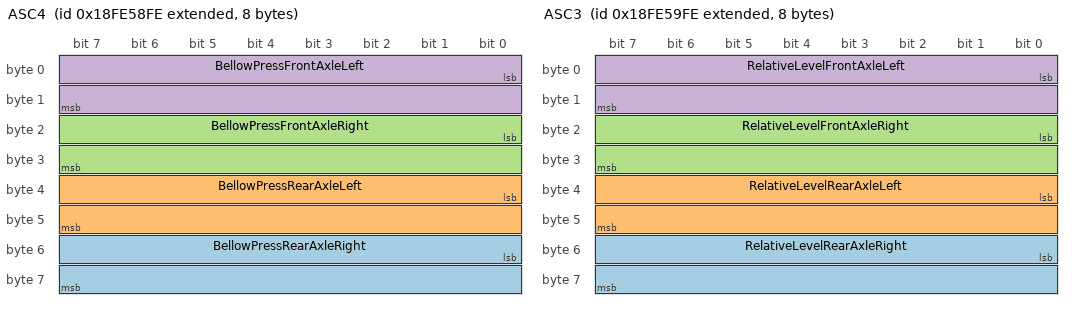
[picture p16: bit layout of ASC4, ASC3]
BO_ 2566805758 ASC4: 8 Vector__XXX
 SG_ BellowPressRearAxleRight : 48|16@1+ (0.1,0) [0.0|6425.5] "kPa" Vector__XXX
 SG_ BellowPressRearAxleLeft : 32|16@1+ (0.1,0) [0.0|6425.5] "kPa" Vector__XXX
 SG_ BellowPressFrontAxleRight : 16|16@1+ (0.1,0) [0.0|6425.5] "kPa" Vector__XXX
 SG_ BellowPressFrontAxleLeft : 0|16@1+ (0.1,0) [0.0|6425.5] "kPa" Vector__XXX

BO_ 2566806014 ASC3: 8 Vector__XXX
 SG_ RelativeLevelRearAxleRight : 48|16@1+ (0.1,-3200) [-3200.0|3225.5] "mm" Vector__XXX
 SG_ RelativeLevelRearAxleLeft : 32|16@1+ (0.1,-3200) [-3200.0|3225.5] "mm" Vector__XXX
 SG_ RelativeLevelFrontAxleRight : 16|16@1+ (0.1,-3200) [-3200.0|3225.5] "mm" Vector__XXX
 SG_ RelativeLevelFrontAxleLeft : 0|16@1+ (0.1,-3200) [-3200.0|3225.5] "mm" Vector__XXX

BO_ 2362638078 ASC2_53760: 8 Vector__XXX
 SG_ MemoryLevelReq_5433 : 60|4@1+ (1,0) [0.0|15.0] "" Vector__XXX
 SG_ ProhibitAASControl_5274 : 58|2@1+ (1,0) [0.0|3.0] "" Vector__XXX
 SG_ SpdDependentLevelCtrlRq_5295 : 56|2@1+ (1,0) [0.0|3.0] "" Vector__XXX
 SG_ AllwLvlCtrlDuringBrakingCmd_5293 : 54|2@1+ (1,0) [0.0|3.0] "" Vector__XXX
 SG_ ProhibitAirSuspensionCtrl_3215 : 52|2@1+ (1,0) [0.0|3.0] "" Vector__XXX
 SG_ KneelingCmdRearAxle_1829 : 50|2@1+ (1,0) [0.0|3.0] "" Vector__XXX
 SG_ KneelingCmdFrontAxle_1830 : 48|2@1+ (1,0) [0.0|3.0] "" Vector__XXX
 SG_ DamprStfnReqLiftOrTagAxle_1720 : 40|8@1+ (0.4,0) [0.0|100.0] "%" Vector__XXX
 SG_ DamperStiffnessRqRearAxle_1719 : 32|8@1+ (0.4,0) [0.0|100.0] "%" Vector__XXX
 SG_ DamperStiffnessRqFrontAxle_1718 : 24|8@1+ (0.4,0) [0.0|100.0] "%" Vector__XXX
 SG_ LiftAxle2PosCmd_1828 : 22|2@1+ (1,0) [0.0|3.0] "" Vector__XXX
 SG_ LiftAxle1PosCmd_1752 : 20|2@1+ (1,0) [0.0|3.0] "" Vector__XXX
 SG_ LevelCtrlModeRq_1753 : 16|4@1+ (1,0) [0.0|15.0] "" Vector__XXX
 SG_ NominalLevelRqRearAxle_1750 : 12|4@1+ (1,0) [0.0|15.0] "" Vector__XXX
 SG_ NominalLevelRqFrontAxle_1751 : 8|4@1+ (1,0) [0.0|15.0] "" Vector__XXX
 SG_ KneelingCtrlModeRq_1747 : 6|2@1+ (1,0) [0.0|3.0] "" Vector__XXX
 SG_ KneelingRqRightSide_1748 : 4|2@1+ (1,0) [0.0|3.0] "" Vector__XXX
 SG_ KneelingRqLeftSide_1749 : 2|2@1+ (1,0) [0.0|3.0] "" Vector__XXX
 SG_ AutomaticTractionHelp_2984 : 0|2@1+ (1,0) [0.0|3.0] "" Vector__XXX

BO_ 2365479678 ASC1: 8 Vector__XXX
 SG_ MemoryLevel : 60|4@1+ (1,0) [0.0|15.0] "" Vector__XXX
 SG_ SuspensionCtrlRefusalInformation : 56|4@1+ (1,0) [0.0|15.0] "" Vector__XXX
 SG_ SpeedDependantLevelCtrlStatus : 54|2@1+ (1,0) [0.0|3.0] "" Vector__XXX
 SG_ AllwLevelCtrlDuringBrakingStatus : 52|2@1+ (1,0) [0.0|3.0] "" Vector__XXX
 SG_ SuspensionRemoteCtrl2 : 50|2@1+ (1,0) [0.0|3.0] "" Vector__XXX
 SG_ SuspensionRemoteCtrl1 : 48|2@1+ (1,0) [0.0|3.0] "" Vector__XXX
 SG_ LiftAxle2Pos : 46|2@1+ (1,0) [0.0|3.0] "" Vector__XXX
 SG_ RearAxleInBumperRange : 42|2@1+ (1,0) [0.0|3.0] "" Vector__XXX
 SG_ FrontAxleInBumperRange : 40|2@1+ (1,0) [0.0|3.0] "" Vector__XXX
 SG_ LiftAxle1Pos : 38|2@1+ (1,0) [0.0|3.0] "" Vector__XXX
 SG_ DoorRelease : 36|2@1+ (1,0) [0.0|3.0] "" Vector__XXX
 SG_ VehicleMotionInhibit : 34|2@1+ (1,0) [0.0|3.0] "" Vector__XXX
 SG_ SecurityDevice : 32|2@1+ (1,0) [0.0|3.0] "" Vector__XXX
 SG_ LevelCtrlMode : 28|4@1+ (1,0) [0.0|15.0] "" Vector__XXX
 SG_ KneelingInformation : 24|4@1+ (1,0) [0.0|15.0] "" Vector__XXX
 SG_ LiftingCtrlModeRearAxle : 22|2@1+ (1,0) [0.0|3.0] "" Vector__XXX
 SG_ LiftingCtrlModeFrontAxle : 20|2@1+ (1,0) [0.0|3.0] "" Vector__XXX
 SG_ LoweringCtrlModeRearAxle : 18|2@1+ (1,0) [0.0|3.0] "" Vector__XXX
 SG_ LoweringCtrlModeFrontAxle : 16|2@1+ (1,0) [0.0|3.0] "" Vector__XXX
 SG_ AboveNominalLevelRearAxle : 14|2@1+ (1,0) [0.0|3.0] "" Vector__XXX
 SG_ AboveNominalLevelFrontAxle : 12|2@1+ (1,0) [0.0|3.0] "" Vector__XXX
 SG_ BelowNominalLevelRearAxle : 10|2@1+ (1,0) [0.0|3.0] "" Vector__XXX
 SG_ BelowNominalLevelFrontAxle : 8|2@1+ (1,0) [0.0|3.0] "" Vector__XXX
 SG_ NominalLevelRearAxle : 4|4@1+ (1,0) [0.0|15.0] "" Vector__XXX
 SG_ NominalLevelFrontAxle : 0|4@1+ (1,0) [0.0|15.0] "" Vector__XXX

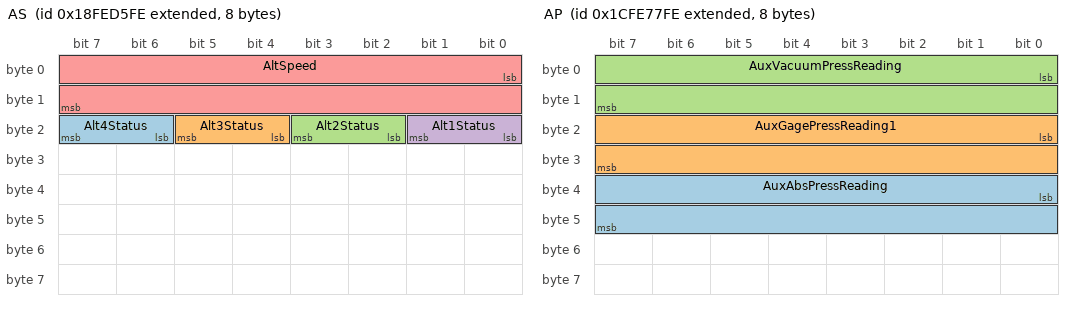
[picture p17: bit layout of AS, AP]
BO_ 2566837758 AS: 8 Vector__XXX
 SG_ Alt4Status : 22|2@1+ (1,0) [0.0|3.0] "" Vector__XXX
 SG_ Alt3Status : 20|2@1+ (1,0) [0.0|3.0] "" Vector__XXX
 SG_ Alt2Status : 18|2@1+ (1,0) [0.0|3.0] "" Vector__XXX
 SG_ Alt1Status : 16|2@1+ (1,0) [0.0|3.0] "" Vector__XXX
 SG_ AltSpeed : 0|16@1+ (0.5,0) [0.0|32127.5] "rpm" Vector__XXX

BO_ 2633922558 AP: 8 Vector__XXX
 SG_ AuxAbsPressReading : 32|16@1+ (0.5,0) [0.0|32127.5] "kPa" Vector__XXX
 SG_ AuxGagePressReading1 : 16|16@1+ (0.5,0) [0.0|32127.5] "kPa" Vector__XXX
 SG_ AuxVacuumPressReading : 0|16@1+ (0.5,0) [0.0|32127.5] "kPa" Vector__XXX

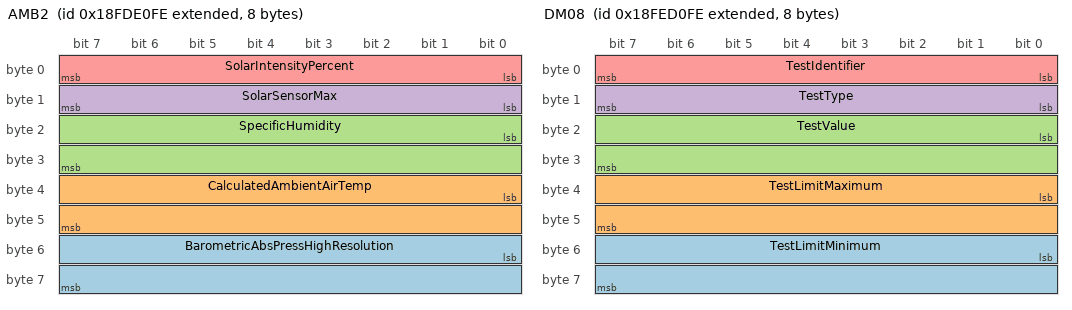
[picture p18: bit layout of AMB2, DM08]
BO_ 2566775038 AMB2: 8 Vector__XXX
 SG_ BarometricAbsPressHighResolution : 48|16@1+ (0.1,0) [0.0|6425.5] "kPa" Vector__XXX
 SG_ CalculatedAmbientAirTemp : 32|16@1+ (0.03125,-273) [-273.0|1734.96875] "°C" Vector__XXX
 SG_ SpecificHumidity : 16|16@1+ (0.01,0) [0.0|642.55] "g/kg" Vector__XXX
 SG_ SolarSensorMax : 8|8@1+ (0.4,0) [0.0|100.0] "mW/cm²" Vector__XXX
 SG_ SolarIntensityPercent : 0|8@1+ (0.4,0) [0.0|100.0] "%" Vector__XXX

BO_ 2566836478 DM08: 8 Vector__XXX
 SG_ TestLimitMinimum : 48|16@1+ (1,0) [0.0|0.0] "" Vector__XXX
 SG_ TestLimitMaximum : 32|16@1+ (1,0) [0.0|0.0] "" Vector__XXX
 SG_ TestValue : 16|16@1+ (1,0) [0.0|0.0] "" Vector__XXX
 SG_ TestType : 8|8@1+ (1,0) [0.0|250.0] "" Vector__XXX
 SG_ TestIdentifier : 0|8@1+ (1,0) [0.0|255.0] "" Vector__XXX

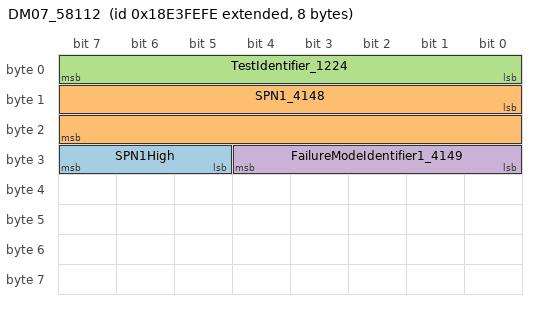
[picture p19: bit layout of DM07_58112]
BO_ 2565078782 DM07_58112: 8 Vector__XXX
 SG_ SPN1High : 29|3@1+ (1,0) [0.0|7.0] "" Vector__XXX
 SG_ SPN1_4148 : 8|16@1+ (1,0) [0.0|524287.0] "" Vector__XXX
 SG_ TestIdentifier_1224 : 0|8@1+ (1,0) [0.0|255.0] "" Vector__XXX
 SG_ FailureModeIdentifier1_4149 : 24|5@1+ (1,0) [0.0|31.0] "" Vector__XXX

BO_ 2566836222 DM06: 22 Vector__XXX
 SG_ FlashRedStopLamp : 12|2@1+ (1,0) [0.0|3.0] "" Vector__XXX
 SG_ FlashProtectLamp : 8|2@1+ (1,0) [0.0|3.0] "" Vector__XXX
 SG_ FlashMalfuncIndicatorLamp : 14|2@1+ (1,0) [0.0|3.0] "" Vector__XXX
 SG_ FlashAmberWarningLamp : 10|2@1+ (1,0) [0.0|3.0] "" Vector__XXX
 SG_ MalfunctionIndicatorLampStatus : 6|2@1+ (1,0) [0.0|3.0] "" Vector__XXX
 SG_ RedStopLampState : 4|2@1+ (1,0) [0.0|3.0] "" Vector__XXX
 SG_ AmberWarningLampStatus : 2|2@1+ (1,0) [0.0|3.0] "" Vector__XXX
 SG_ ProtectLampStatus : 0|2@1+ (1,0) [0.0|3.0] "" Vector__XXX
 SG_ DTC5 : 144|32@1+ (1,0) [0.0|4294967295.0] "" Vector__XXX
 SG_ DTC4 : 112|32@1+ (1,0) [0.0|4294967295.0] "" Vector__XXX
 SG_ DTC3 : 80|32@1+ (1,0) [0.0|4294967295.0] "" Vector__XXX
 SG_ DTC2 : 48|32@1+ (1,0) [0.0|4294967295.0] "" Vector__XXX
 SG_ DTC1 : 16|32@1+ (1,0) [0.0|4294967295.0] "" Vector__XXX

BO_ 2566835966 DM05: 8 Vector__XXX
 SG_ BoostPressureControlSystemStatus : 57|1@1- (1,0) [0.0|0.0] "" Vector__XXX
 SG_ DieselParticulateFilterStatus : 58|1@1- (1,0) [0.0|0.0] "" Vector__XXX
 SG_ NOxConvertingCatalystAdsorberSta : 59|1@1- (1,0) [0.0|0.0] "" Vector__XXX
 SG_ NMHCConvertingCatalystStatus : 60|1@1- (1,0) [0.0|0.0] "" Vector__XXX
 SG_ BoostPressureControlSystemSuppor : 41|1@1- (1,0) [0.0|0.0] "" Vector__XXX
 SG_ DieselParticulateFilterSupport : 42|1@1- (1,0) [0.0|0.0] "" Vector__XXX
 SG_ NOxConvertingCatalystAdsorberSup : 43|1@1- (1,0) [0.0|0.0] "" Vector__XXX
 SG_ NMHCConvertingCatalystSupport : 44|1@1- (1,0) [0.0|0.0] "" Vector__XXX
 SG_ MisfireMonitoringSupport : 24|1@1+ (1,0) [0.0|0.0] "" Vector__XXX
 SG_ OBDCompliance : 16|8@1+ (1,0) [0.0|250.0] "" Vector__XXX
 SG_ PreviouslyActiveTroubleCodes : 8|8@1+ (1,0) [0.0|250.0] "" Vector__XXX
 SG_ ActiveTroubleCodes : 0|8@1+ (1,0) [0.0|250.0] "" Vector__XXX
 SG_ SecondAirSystemMonStatus : 51|1@1+ (1,0) [0.0|1.0] "" Vector__XXX
 SG_ EvaporativeSystemMonStatus : 50|1@1+ (1,0) [0.0|1.0] "" Vector__XXX
 SG_ ACSystemRefrigerantMonStatus : 52|1@1+ (1,0) [0.0|1.0] "" Vector__XXX
 SG_ OxygenSensorHeaterMonStatus : 54|1@1+ (1,0) [0.0|1.0] "" Vector__XXX
 SG_ OxygenSensorMonStatus : 53|1@1+ (1,0) [0.0|1.0] "" Vector__XXX
 SG_ EGRSystemMonitoringStatus : 55|1@1+ (1,0) [0.0|1.0] "" Vector__XXX
 SG_ CatalystMonStatus : 48|1@1+ (1,0) [0.0|1.0] "" Vector__XXX
 SG_ ColdStartAidSystemMonStatus : 56|1@1+ (1,0) [0.0|1.0] "" Vector__XXX
 SG_ HeatedCatalystMonStatus : 49|1@1+ (1,0) [0.0|0.0] "" Vector__XXX
 SG_ CatalystMonSupp : 32|1@1+ (1,0) [0.0|1.0] "" Vector__XXX
 SG_ ColdStartAidSystemMonSupp : 40|1@1+ (1,0) [0.0|1.0] "" Vector__XXX
 SG_ HeatedCatalystMonSupp : 33|1@1+ (1,0) [0.0|0.0] "" Vector__XXX
 SG_ EvaporativeSystemMonSupp : 34|1@1+ (1,0) [0.0|1.0] "" Vector__XXX
 SG_ SecondAirSystemMonSupp : 35|1@1+ (1,0) [0.0|1.0] "" Vector__XXX
 SG_ ACSystemRefrigerantMonSupp : 36|1@1+ (1,0) [0.0|1.0] "" Vector__XXX
 SG_ OxygenSensorMonSupp : 37|1@1+ (1,0) [0.0|1.0] "" Vector__XXX
 SG_ OxygenSensorHeaterMonSupp : 38|1@1+ (1,0) [0.0|1.0] "" Vector__XXX
 SG_ EGRSystemMonitoringSupp : 39|1@1+ (1,0) [0.0|1.0] "" Vector__XXX
 SG_ MisfireMonitoringStatus : 28|1@1+ (1,0) [0.0|0.0] "" Vector__XXX
 SG_ ComprehensiveCompMonStatus : 30|1@1+ (1,0) [0.0|1.0] "" Vector__XXX
 SG_ FuelSystemMonitoringStatus : 29|1@1+ (1,0) [0.0|1.0] "" Vector__XXX
 SG_ ComprehensiveComponentMonSupp : 26|1@1+ (1,0) [0.0|0.0] "" Vector__XXX
 SG_ FuelSystemMonitoringSupport : 25|1@1+ (1,0) [0.0|1.0] "" Vector__XXX

BO_ 2566835710 DM04: 13 Vector__XXX
 SG_ EngIntakeManifold1Press : 48|8@1+ (2,0) [0.0|500.0] "kPa" Vector__XXX
 SG_ FreezeFrameLength : 0|8@1+ (1,0) [0.0|255.0] "" Vector__XXX
 SG_ EngSpeed : 56|16@1+ (0.125,0) [0.0|8031.875] "rpm" Vector__XXX
 SG_ EngTorqueMode : 40|4@1+ (1,0) [0.0|15.0] "" Vector__XXX
 SG_ WheelBasedVehicleSpeed : 88|16@1+ (0.00390625,0) [0.0|250.996] "km/h" Vector__XXX
 SG_ EngPercentLoadAtCurrentSpeed : 72|8@1+ (1,0) [0.0|125.0] "%" Vector__XXX
 SG_ EngCoolantTemp : 80|8@1+ (1,-40) [-40.0|210.0] "°C" Vector__XXX
 SG_ DTC1 : 8|32@1+ (1,0) [0.0|4294967295.0] "" Vector__XXX

BO_ 2566835454 DM03: 0 Vector__XXX

BO_ 2566764542 DM25: 13 Vector__XXX
 SG_ ExpandedFreezeFrameLength : 0|8@1+ (1,0) [0.0|250.0] "bytes" Vector__XXX
 SG_ DTC1 : 8|32@1+ (1,0) [0.0|4294967295.0] "" Vector__XXX

BO_ 2566764286 DM24: 12 Vector__XXX
 SG_ SPNSupported1High : 21|3@1+ (1,0) [0.0|7.0] "" Vector__XXX
 SG_ SPNSupportTypeSTR3 : 82|1@1+ (1,0) [0.0|1.0] "" Vector__XXX
 SG_ SPNSupportTypeSTR2 : 50|1@1+ (1,0) [0.0|1.0] "" Vector__XXX
 SG_ SPNSupportTypeEFF3 : 80|1@1+ (1,0) [0.0|1.0] "" Vector__XXX
 SG_ SPNSupportTypeEFF2 : 48|1@1+ (1,0) [0.0|1.0] "" Vector__XXX
 SG_ SPNSupportTypeDS3 : 81|1@1+ (1,0) [0.0|1.0] "" Vector__XXX
 SG_ SPNSupportTypeDS2 : 49|1@1+ (1,0) [0.0|1.0] "" Vector__XXX
 SG_ SPNSupported3High : 85|3@1+ (1,0) [0.0|7.0] "" Vector__XXX
 SG_ SPNSupported2High : 53|3@1+ (1,0) [0.0|7.0] "" Vector__XXX
 SG_ SPNSupported3 : 64|16@1+ (1,0) [0.0|65535.0] "" Vector__XXX
 SG_ SPNSupported2 : 32|16@1+ (1,0) [0.0|65535.0] "" Vector__XXX
 SG_ SPNDataLength3 : 88|8@1+ (1,0) [0.0|240.0] "" Vector__XXX
 SG_ SPNSupportTypeSTR1 : 18|1@1+ (1,0) [0.0|1.0] "" Vector__XXX
 SG_ SPNSupportTypeDS1 : 17|1@1+ (1,0) [0.0|1.0] "" Vector__XXX
 SG_ SPNSupportTypeEFF1 : 16|1@1+ (1,0) [0.0|1.0] "" Vector__XXX
 SG_ SPNDataLength2 : 56|8@1+ (1,0) [0.0|240.0] "" Vector__XXX
 SG_ SPNDataLength1 : 24|8@1+ (1,0) [0.0|250.0] "" Vector__XXX
 SG_ SPNSupported1 : 0|16@1+ (1,0) [0.0|524287.0] "" Vector__XXX

BO_ 2566764030 DM23: 22 Vector__XXX
 SG_ FlashRedStopLamp : 12|2@1+ (1,0) [0.0|3.0] "" Vector__XXX
 SG_ FlashProtectLamp : 8|2@1+ (1,0) [0.0|3.0] "" Vector__XXX
 SG_ FlashMalfuncIndicatorLamp : 14|2@1+ (1,0) [0.0|3.0] "" Vector__XXX
 SG_ FlashAmberWarningLamp : 10|2@1+ (1,0) [0.0|3.0] "" Vector__XXX
 SG_ MalfunctionIndicatorLampStatus : 6|2@1+ (1,0) [0.0|3.0] "" Vector__XXX
 SG_ RedStopLampState : 4|2@1+ (1,0) [0.0|3.0] "" Vector__XXX
 SG_ AmberWarningLampStatus : 2|2@1+ (1,0) [0.0|3.0] "" Vector__XXX
 SG_ ProtectLampStatus : 0|2@1+ (1,0) [0.0|3.0] "" Vector__XXX
 SG_ DTC5 : 144|32@1+ (1,0) [0.0|4294967295.0] "" Vector__XXX
 SG_ DTC4 : 112|32@1+ (1,0) [0.0|4294967295.0] "" Vector__XXX
 SG_ DTC3 : 80|32@1+ (1,0) [0.0|4294967295.0] "" Vector__XXX
 SG_ DTC2 : 48|32@1+ (1,0) [0.0|4294967295.0] "" Vector__XXX
 SG_ DTC1 : 16|32@1+ (1,0) [0.0|4294967295.0] "" Vector__XXX

CM_ BO_ 2566736382  "Engine Exhaust Bank 1 O2 Fuel Trim
Provides bank 1 short-term and long-term fuel trim values";
CM_ BO_ 2565874174  "Engine Speed Sensor Information
This PGN contains the speed information and status signal of each engine speed sensor. This message is used for service to troubleshoot no-start or hard start problems.  This message is not needed except for ...";
CM_ BO_ 2432520958  "Engine Coolant Control Valve Command
Transmit status information from the Master ECU to an electronic thermostat";
CM_ BO_ 2560425726  "Auxiliary Input/Output Status 7 - Notes:
Implementers are encouraged to use specific functional SPNs whenever possible.
AUXIO PGNs are intended for two categories of use in which fixed mapping to functions is not possible:
1)  Generic I/O devices
...";
CM_ BO_ 2560491262  "Auxiliary Input/Output Status 6 - Notes:
Implementers are encouraged to use specific functional SPNs whenever possible.
AUXIO PGNs are intended for two categories of use in which fixed mapping to functions is not possible:
1)  Generic I/O devices
...";
CM_ BO_ 2349399806  "Auxiliary Input/Output Status 5 - Notes:
Implementers are encouraged to use specific functional SPNs whenever possible.
AUXIO PGNs are intended for two categories of use in which fixed mapping to functions is not possible:
1)  Generic I/O devices
...";
CM_ BO_ 2566758398  "Aftertreatment 1 Air Control 1
Contains information about the aftertreatment 1 air system";
CM_ BO_ 2566745598  "Aftertreatment 1 Air Control 2
This PGN contains information about the Aftertreatment 1 Air Control.
NOTE: This message will be transmitted by the engine or aftertreatment controller.  Other aftertreatment air control information could be added in ...";
CM_ BO_ 2566758910  "Aftertreatment 1 Fuel Control 1
Contains information about the aftertreatment 1 fuel system";
CM_ BO_ 2566743550  "Aftertreatment 1 Fuel Control 2
Contains information about the aftertreatment 1 fuel system.  See also PGN 64929.";
CM_ BO_ 2566753534  "Aftertreatment 1 Gas Parameters
Diesel particulate filter gas parameters for system or bank 1";
CM_ BO_ 2566756606  "Aftertreatment 1 Historical Information 1
Contains information about the history of the aftertreatment 1 system";
CM_ BO_ 2565869310  "Aftertreatment 1 Intake Gas 1 - The purpose of this PGN is to group the aftertreatment intake sensor data for bank 1.  These values include the NOx, %O2 , Status's of the sensors with respect to the power being supplied and the heating element, ...";
CM_ BO_ 2566763774  "Aftertreatment 1 Intake Gas 2
The purpose of this PGN is to group the aftertreatment intake gas temperature messages for bank 1.";
CM_ BO_ 2631728894  "Anti-theft Status
NOTE–See Figures PGN56320_A to PGN56320_F for examples of Anti-theft message transfers.  Bit 1 is the right most bit in each byte.";
CM_ BO_ 2631794430  "Anti-theft Request
NOTE–See Figures PGN56320_A thru PGN56320_F for examples of Anti-theft message transfers.  Bit 1 is the right most bit in each byte.";
CM_ BO_ 2633934846  "Alternator Temperature";
CM_ BO_ 2362572542  "Air Suspension Control 6 - Used for suspension control";
CM_ BO_ 2365478910  "Air Suspension Control 5
Used for damper stiffness information";
CM_ BO_ 2560950014  "Scaled Test Results
This message conveys the scaled test results for the applicable test requested in DM7. The SPN and FMI convey the specific DTC for which the results are being reported.";
CM_ BO_ 2566763262  "Aftertreatment 1 Intermediate Gas
The purpose of this PGN is to group the aftertreatment intermediate gas temperature and pressure messages.
Note: The 5 bits of SPN 3253 are positioned into the data field in the following manner.  The 2 most ...";
CM_ BO_ 2565869566  "Aftertreatment 1 Outlet Gas 1 - The purpose of this PGN is to group the aftertreatment outlet sensor data for bank 1.  These values include the NOx, %O2 , Status's of the sensors with respect to the power being supplied and the heating element, ...";
CM_ BO_ 2566763518  "Aftertreatment 1 Outlet Gas 2
The purpose of this PGN is to group the aftertreatment outlet gas temperature messages.";
CM_ BO_ 2566749182  "Aftertreatment 1 Service 1
This PGN contains information about the aftertreatment 1 (diesel particulate filter 1 soot and ash load).";
CM_ BO_ 2566748670  "Aftertreatment 1 Trip Information
This PGN contains trip total information about the aftertreatment 1.
NOTE: The SPNs in this PGN need to be reset by the reset PGN 56832.";
CM_ BO_ 2566758142  "Aftertreatment 2 Air Control 1
Contains information about the aftertreatment 2 air system";
CM_ BO_ 2566745342  "Aftertreatment 2 Air Control 2
This PGN contains information about the Aftertreatment 2 Air Control.
NOTE: This message will be transmitted by the engine or aftertreatment controller.  Other aftertreatment air control information could be added in ...";
CM_ BO_ 2566758654  "Aftertreatment 2 Fuel Control 1
Contains information about the aftertreatment 2 fuel system";
CM_ BO_ 2566753278  "Aftertreatment 2 Gas Parameters
Diesel particulate filter gas parameters for system or bank 2";
CM_ BO_ 2566756862  "Aftertreatment 2 Historical information 1
Contains information about the history of the aftertreatment 2 system";
CM_ BO_ 2565869822  "Aftertreatment 2 Intake Gas 1 - The purpose of this PGN is to group the aftertreatment intake sensor data for bank 2.  These values include the NOx, %O2, status of the sensors with respect to the power being supplied and the heating element, errors ...";
CM_ BO_ 2566763006  "Aftertreatment 2 Intake Gas 2
The purpose of this PGN is to group the aftertreatment intake gas temperature messages for bank 2.";
CM_ BO_ 2566762494  "Aftertreatment 2 Intermediate Gas
The purpose of this PGN is to group the aftertreatment intermediate gas temperature and pressure messages for bank 2.";
CM_ BO_ 2565870078  "Aftertreatment 2 Outlet Gas 1 - The purpose of this PGN is to group the aftertreatment outlet sensor data for bank 2.  These values include the NOx, %O2, status of the sensors with respect to the power being supplied and the heating element, errors ...";
CM_ BO_ 2566762750  "Aftertreatment 2 Outlet Gas 2
The purpose of this PGN is to group the aftertreatment outlet gas temperature messages for bank 2.";
CM_ BO_ 2566748926  "Aftertreatment 2 Service 1
This PGN contains information about the aftertreatment 2 (diesel particulate filter 2 soot and ash load).";
CM_ BO_ 2566748414  "Aftertreatment 2 Trip Information
This PGN contains trip total information about the aftertreatment 2.
NOTE: The SPNs in this PGN need to be reset by the reset PGN 56832.";
CM_ BO_ 2365428478  "Engine Operating Information
Contains engine parameters related to operation.";
CM_ BO_ 2566743806  "Engine Temperature 4
Engine temperatures";
CM_ BO_ 2499635454  "Gross Combination Vehicle Weight
Gross Combination Vehicle Weight";
CM_ BO_ 2550660862  "General Purpose Valve Pressure - The measured load sense pressure and pilot pressure of a valve.  May also include the load sense and supply pressure for a valve assembly, when available.";
CM_ BO_ 2566805758  "Air Suspension Control 4
Used for bellow pressure information";
CM_ BO_ 2566806014  "Air Suspension Control 3
Used for height information";
CM_ BO_ 2362638078  "Air Suspension Control 2 - Used for suspension control";
CM_ BO_ 2365479678  "Air Suspension Control 1
Used for suspension control  information";
CM_ BO_ 2566837758  "Alternator Information";
CM_ BO_ 2633922558  "Auxiliary Pressures";
CM_ BO_ 2566775038  "Ambient Conditions 2
This message contains measurement and configuration information about the vehicle ambient conditions.";
CM_ BO_ 2566836478  "Test Results for Non-continuously Monitored Systems
The purpose of this response PG is to report the test results for one of the non-continuously monitored tests invoked using DM7";
CM_ BO_ 2565078782  "Command Non-continuously Monitored Test - The purpose of this command in the diagnostic process is to provide the ability to command On-Board Diagnostic monitoring tests of specific components/ systems that are not continuously monitored";
CM_ BO_ 2566836222  "Pending DTCs
The purpose of this DM is to enable the external test equipment to obtain “pending” diagnostic trouble codes detected during current or last completed driving cycle for emission-related components/systems.";
CM_ BO_ 2566835966  "Diagnostic Readiness 1
Reports the diagnostics information that relates to diagnostic readiness.";
CM_ BO_ 2566835710  "Freeze Frame Parameters
A freeze frame is defined as the list of recorded parameters at the time a diagnostic trouble code was captured";
CM_ BO_ 2566835454  "Diagnostics Data Clear/Reset for Previously Active DTCs";
CM_ BO_ 2566764542  "Expanded Freeze Frame
This message defines the expanded freeze frame length";
CM_ BO_ 2566764286  "SPN Support
This message is used to identify those SPNs supported by the product for freeze frames and data stream messages.";
CM_ BO_ 2566764030  "Previously Active Emission Related Faults
This message contains DTCs that are confirmed but for which the MIL is off.";
CM_ SG_ 2566736382 EngExhstGsOxygnSnsrClsdLpOprtnBn "This parameter indicates the status of the bank 1 O2 sensor feedback closed loop operation
0000 = Open loop - has not yet satisfied conditions to go closed loop
0001 = Closed loop - using oxygen sensor(s) as feedback for fuel control
0010 = Open ...";
CM_ SG_ 2566736382 ShorttermFuelTrimBank1 "This parameter is the short-term percent change in fueling based on the O2 sensor feedback for cylinder bank 1, based on the operating point in the nominal fuel map.
Note:  This is similar to SPN 1695, but with higher resolution.";
CM_ SG_ 2566736382 LongtermFuelTrimBank1 "This parameter is the long-term percent change in fueling based on the O2 sensor feedback for cylinder bank 1, based on the operating point in the nominal fuel map.";
CM_ SG_ 2565874174 EngSpdSensor1TimingPatternStatus "This is the timing pattern status of the engine speed sensor signal for sensor 1.   The sensor may be sending a speed signal but the pattern may not be valid.  Since the speed is considered valid, the error indicator will not be used in the engine ...";
CM_ SG_ 2565874174 EngSpdSensor2TimingPatternStatus "This is the timing pattern status of the engine speed sensor signal for sensor 2.  The sensor may be sending a speed signal but the pattern may not be valid.  Since the speed is considered valid, the error indicator will not be used in the engine ...";
CM_ SG_ 2565874174 EngSpdSensor3TimingPatternStatus "This is the timing pattern status of the engine speed sensor signal for sensor 3.  The sensor may be sending a speed signal but the pattern may not be valid.  Since the speed is considered valid, the error indicator will not be used in the engine ...";
CM_ SG_ 2565874174 EngSpeed3 "The engine speed as measured by speed sensor 3.
Note:  This is for the engine speed from the 3rd engine speed sensor.  This may be different than SPN 190 when used in multiple engine speed sensor configurations.   In an application with multiple ...";
CM_ SG_ 2565874174 EngSpeed2 "The engine speed as measured by speed sensor 2
Note:  This is for the engine speed from the 2nd engine speed sensor.  This may be different than SPN 190 when used in multiple engine speed sensor configurations.   In an application with multiple ...";
CM_ SG_ 2565874174 EngSpeed1 "The engine speed as measured by speed sensor 1.
Note:  This is for the engine speed from the 1st engine speed sensor.  This may be different than SPN 190 when used in multiple engine speed sensor configurations.   In an application with only one ...";
CM_ SG_ 2432520958 EngAxClerSupplyValve2ActuatorCmd "The control command applied to the engine auxiliary cooler supply valve 2 actuator, where 0% represents closed and 100% represents open.";
CM_ SG_ 2432520958 EngAxClerSupplyValve1ActuatorCmd "The control command applied to the engine auxiliary cooler supply valve 1 actuator, where 0% represents closed and 100% represents open.
See SPN 4197 for primary engine thermostat valve.";
CM_ SG_ 2432520958 DsredEngCoolantThermostatOpening "Indicates the desired position of the engine coolant control valve.   0% represents the thermostat allows flow to completely bypass the radiator and 100% represents the flow is fully through the radiator.  If the electronic thermostat is operating ...";
CM_ SG_ 2432520958 DesiredEngCoolantPumpOutletTemp "Desired engine coolant temperature of the engine to an electronic thermostat.  If the electronic thermostat valve is operating in position control mode (see SPN 4195)  then transmit 0xFF.";
CM_ SG_ 2432520958 EngCoolantThermostatMode "Specifies if the engine coolant thermostat valve will operate in temperature control mode or position control mode.
00 = temperature control mode
01 = position control mode (used for service only)
10 = reserved
11 = don't care/reserved";
CM_ SG_ 2560425726 AuxI_OChannel19_4174 "Identifies the current value of auxiliary input/output channels that are configured uniquely per application.";
CM_ SG_ 2560425726 AuxI_OChannel20_4173 "Identifies the current value of auxiliary input/output channels that are configured uniquely per application.";
CM_ SG_ 2560425726 AuxI_OChannel21_4172 "Identifies the current value of auxiliary input/output channels that are configured uniquely per application.";
CM_ SG_ 2560425726 AuxI_OChannel22_4171 "Identifies the current value of auxiliary input/output channels that are configured uniquely per application.";
CM_ SG_ 2560425726 AuxI_OChannel15_4170 "Identifies the current value of auxiliary input/output channels that are configured uniquely per application.";
CM_ SG_ 2560425726 AuxI_OChannel16_4169 "Identifies the current value of auxiliary input/output channels that are configured uniquely per application.";
CM_ SG_ 2560425726 AuxI_OChannel17_4168 "Identifies the current value of auxiliary input/output channels that are configured uniquely per application.";
CM_ SG_ 2560425726 AuxI_OChannel18_4167 "Identifies the current value of auxiliary input/output channels that are configured uniquely per application.";
CM_ SG_ 2560491262 AuxI_OChannel11_4166 "Identifies the current value of auxiliary input/output channels that are configured uniquely per application.";
CM_ SG_ 2560491262 AuxI_OChannel12_4165 "Identifies the current value of auxiliary input/output channels that are configured uniquely per application.";
CM_ SG_ 2560491262 AuxI_OChannel13_4164 "Identifies the current value of auxiliary input/output channels that are configured uniquely per application.";
CM_ SG_ 2560491262 AuxI_OChannel14_4163 "Identifies the current value of auxiliary input/output channels that are configured uniquely per application.";
CM_ SG_ 2560491262 AuxI_OChannel7_4162 "Identifies the current value of auxiliary input/output channels that are configured uniquely per application.";
CM_ SG_ 2560491262 AuxI_OChannel8_4161 "Identifies the current value of auxiliary input/output channels that are configured uniquely per application.";
CM_ SG_ 2560491262 AuxI_OChannel9_4160 "Identifies the current value of auxiliary input/output channels that are configured uniquely per application.";
CM_ SG_ 2560491262 AuxI_OChannel10_4159 "Identifies the current value of auxiliary input/output channels that are configured uniquely per application.";
CM_ SG_ 2349399806 AuxI_OChannel3_4158 "Identifies the current value of auxiliary input/output channels that are configured uniquely per application.";
CM_ SG_ 2349399806 AuxI_OChannel4_4157 "Identifies the current value of auxiliary input/output channels that are configured uniquely per application.";
CM_ SG_ 2349399806 AuxI_OChannel5_4156 "Identifies the current value of auxiliary input/output channels that are configured uniquely per application.";
CM_ SG_ 2349399806 AuxI_OChannel6_4155 "Identifies the current value of auxiliary input/output channels that are configured uniquely per application.";
CM_ SG_ 2566758398 EnableAct "Indicates whether aftertreatment 1 air enable actuator is on or off
00   not active
01   active
10   reserved for SAE assignment
11   not available";
CM_ SG_ 2566758398 PurgeAirAct "Indicates whether aftertreatment 1 purge air actuator is on or off
00   not active
01   active
10   reserved for SAE assignment
11   not available";
CM_ SG_ 2566758398 AtomizationAirAct "Indicates whether aftertreatment 1 atomization air actuator is on or off
00   not active
01   active
10   reserved for SAE assignment
11   not available";
CM_ SG_ 2566758398 SysRelay "Indicates whether aftertreatment 1 air system relay is on or off
00   not active
01   active
10   reserved for SAE assignment
11   not available";
CM_ SG_ 2566758398 PressActPos "Position of the aftertreatment 1 air pressure actuator as measured by a position feedback sensor.";
CM_ SG_ 2566758398 PressCtrl "Position that the controller is commanding the aftertreatment 1 air pressure control to maintain.  0% = fully closed, 100% = fully open";
CM_ SG_ 2566758398 PurgeAirPress "Pressure of the purge air supply for aftertreatment 1";
CM_ SG_ 2566758398 SupplyAirPress "Pressure of the supply air for aftertreatment 1.  Supply air is the air supplied from a pneumatic line for an air-assisted or pneumatic actuator.  One example is an air assisted fuel injector (the supply air assists in the atomization of fuel).";
CM_ SG_ 2566745598 SecondAirPress "Pressure of the secondary air for aftertreatment 1.  Secondary air is air provided to the exhaust system (per SAE J2403).
For absolute pressure, see SPN 5589.";
CM_ SG_ 2566745598 SecondAirMFR "Indicates the secondary air mass flow for aftertreatment 1.  Secondary air is the air provided to the exhaust system (per SAE J2403).";
CM_ SG_ 2566745598 SecondAirTemp "Indicates the secondary air temperature for aftertreatment 1.  Secondary air is air provided to the exhaust system (per SAE J2403).";
CM_ SG_ 2566745598 SecondAirDiffPress "Indicates the secondary air differential pressure for aftertreatment 1.  Secondary air is air provided to the exhaust system (per SAE J2403).";
CM_ SG_ 2566758910 Injector1HtrCtrl "Heating level that the controller is commanding the aftertreatment 1 fuel injector 1 heater control to maintain. 0% = off, 100% = maximum.";
CM_ SG_ 2566758910 EnableAct "Indicates whether aftertreatment 1 fuel enable actuator is on or off
00   not active
01   active
10   reserved for SAE assignment
11   not available";
CM_ SG_ 2566758910 RegenStatus "Indicates whether regeneration is active or inactive in aftertreatment 1.
00   not active
01   active
10   reserved for SAE assignment
11   not available";
CM_ SG_ 2566758910 Ignt "Indicates whether aftertreatment 1 ignition circuit is energized by the ECU.
00   not active
01   active
10   reserved for SAE assignment
11   not available";
CM_ SG_ 2566758910 DrainAct "Indicates whether aftertreatment 1 fuel drain actuator is on or off
00   not active
01   active
10   reserved for SAE assignment
11   not available";
CM_ SG_ 2566758910 Press1Ctrl "Position that the controller is commanding the aftertreatment 1 fuel pressure control to maintain.  0% = fully closed, 100% = fully open.";
CM_ SG_ 2566758910 Rate "Rate of fuel being delivered to aftertreatment 1 for regeneration";
CM_ SG_ 2566758910 Press1 "First fuel pressure measurement for the aftertreatment 1 system";
CM_ SG_ 2566743550 HydrocarbonDoserInFuelTemp "Measured temperature of the intake fuel to the hydrocarbon dosing device.";
CM_ SG_ 2566743550 Press2ActCtrl "Indicates how the device is controlling the aftertreatment 1 fuel pressure 2 regulating control valve.   0% = fully closed, 100%=fully open.";
CM_ SG_ 2566743550 FlowDiverterVlvCtrl "Indicates how the device is controlling the aftertreatment 1 fuel flow diverter valve. When this valve is on it diverts fuel flow from the Aftertreatment 1 Regeneration Device.
00 off
01 on
10 reserved for SAE assignment
11 not available";
CM_ SG_ 2566743550 PumpRelayCtrl "Indicates how the device is controlling the aftertreatment 1 fuel pump relay.
00 off
01 on
10 reserved for SAE assignment
11 not available";
CM_ SG_ 2566743550 Press2 "Second fuel pressure measurement for the aftertreatment 1 system";
CM_ SG_ 2566753534 DPFOutPress "This parameter indicates the diesel particulate filter outlet gage pressure 1 (bank 1).";
CM_ SG_ 2566753534 DPFInPress "This parameter indicates the diesel particulate filter intake gage pressure 1 (bank 1).";
CM_ SG_ 2566756606 DPFAvgDistBetweenActiveRegens "Indicates the average distance since last reset between active regenerations, that have not been forced to occur by manual request, for aftertreatment device 1.
If the manufacturer allows this parameter to be reset, this distance is the average ...";
CM_ SG_ 2566756606 DPFAvgTimeBetweenActiveRegens "Indicates the average time since last reset between active regenerations, that have not been forced to occur by manual request, for Aftertreatment device 1.
If the manufacturer allows this parameter to be reset, this time is the average since last ...";
CM_ SG_ 2566756606 DPFTotalNumOfActiveRegenManReq "Total number of aftertreatment device 1 active regeneration manual requests by the operator over the lifetime of the device.";
CM_ SG_ 2566756606 DPFTotalNumOfActiveRegenInhReq "Total number of aftertreatment device 1 active regeneration inhibit requests by the operator over the lifetime of the device.";
CM_ SG_ 2566756606 DPFTotalNumOfPassiveRegens "Total number of passive regenerations by aftertreatment device 1 over the lifetime of the device.";
CM_ SG_ 2566756606 DPFTotalPassiveRegenTime "Total amount of time that aftertreatment 1 diesel particulate filter has been in passive regeneration over the lifetime of the device.";
CM_ SG_ 2566756606 TotalNumOfActiveRegens "Total number of active regenerations by aftertreatment device 1 over the lifetime of the device.";
CM_ SG_ 2566756606 TotalDisdTime "Total amount of time that aftertreatment 1 regeneration has been manually disabled.";
CM_ SG_ 2566756606 TotalRegenTime "Total amount of time that aftertreatment device 1 has been regenerating over the lifetime of the device.";
CM_ SG_ 2566756606 TotalFuelUsed "Total amount of fuel used by aftertreatment device 1 over the lifetime of the device.";
CM_ SG_ 2565869310 IntkNOxSnsr1SelfDiagStatus_5714 "Self-diagnosis result status for the NOx sensor ATI1 (Aftertreatment Intake Bank 1)
000 Diagnosis not active
001 NOx Sensor ATI1 Self Diagnosis active flag
010 NOx Sensor ATI1 Self Diagnosis Result Complete
011 NOx Sensor ATI1 Self Diagnosis ...";
CM_ SG_ 2565869310 IntkO2Snsr1PrelFMI_3225 "Used to identify the applicable J1939-73 FMI detected in the aftertreatment intake oxygen sensor by the manufacturer’s sensor control software in exhaust bank 1.  When there is no failure FMI 31 is sent.  In the case of multiple failures the most ...";
CM_ SG_ 2565869310 SCRIntkNOxSnsr1PrelFMI_3224 "Used to identify the applicable J1939-73 FMI detected in the aftertreatment intake NOx sensor by the manufacturer’s sensor control software in exhaust bank 1.  When there is no failure FMI 31 is sent.  In the case of multiple failures the most ...";
CM_ SG_ 2565869310 IntkGasSnsr1HeatrCtl_3223 "Indicates the heater status in the warm-up process.  Upon receiving a power-up command, the gas sensor ramps up according to a manufacturer defined profile.  The Preheat 1, Preheat 2, and Automatic messages are regions within this profile in exhaust ...";
CM_ SG_ 2565869310 IntkGasSnsr1HeatrPrelFMI_3222 "Used to identify the applicable J1939-73 FMI detected in the heater of the intake exhaust gas sensor, either NOx or O2, by the manufacturer’s sensor control software in exhaust bank 1.  When there is no failure FMI 31 is sent.  In the case of ...";
CM_ SG_ 2565869310 IWRPO1ReadingStab_3221 "Indicates that the percent oxygen reading of the aftertreatment intake gas sensor, either NOx or O2, is stable as determined by the manufacturer's control software in exhaust bank 1.
00 - Not stable
01 - Stable
10 - Error
11 - Not available";
CM_ SG_ 2565869310 SCRIntkNOx1ReadingStab_3220 "Indicates that the NOx reading of the aftertreatment intake NOx sensor is stable as determined by the manufacturer’s control software in exhaust bank 1.
00 - Not stable
01 - Stable
10 - Error
11 - Not available";
CM_ SG_ 2565869310 IntkGasSnsr1AtTemp_3219 "Indicates that the heater element of the aftertreatment intake gas sensor, either NOx or O2, is within the manufacturer’s specified range for accurate measurements in exhaust bank 1.
00 - Not in range
01 - In range
10 - Error
11 - Not available
...";
CM_ SG_ 2565869310 IntkGasSnsr1PwrInRng_3218 "Indicates that the power supplied to the aftertreatment intake gas sensor, either NOx or O2, is within the manufacturer’s specification in exhaust bank 1.  This parameter reports the status as reported by the sensor.
00 - Not in range
01 - In ...";
CM_ SG_ 2565869310 Aftertreatment1IntkPercO2_3217 "The actual oxidation factor (Percent Oxygen) of the gas within the exhaust stream. For positive values, the parameter represents the percent oxygen in excess of the amount required for stoichiometric combustion. For negative values, the parameter is ...";
CM_ SG_ 2565869310 Aftertreatment1SCRIntkNOx1_3216 "The amount of combined NO and NO2 in the exhaust entering the aftertreatment system measured by a NOx sensor at the aftertreatment intake, represented in NOx molecule parts per million non-NOx molecules in exhaust bank 1 Dosing Unit 1.
SPN 3216 ...";
CM_ SG_ 2566763774 DPFInTempPreliminaryFMI "Used to identify the applicable J1939-73 FMI detected in the diesel particulate filter intake temperature sensor by the manufacturer’s sensor control software in exhaust bank 1.  When there is no failure FMI 31 is sent.  In the case of multiple ...";
CM_ SG_ 2566763774 ExhTemp1PreliminaryFMI "Used to identify the applicable J1939-73 FMI detected in the exhaust temperature 1 sensor by the manufacturer’s sensor control software in exhaust bank 1.  When there is no failure FMI 31 is sent.  In the case of multiple failures the most severe is ...";
CM_ SG_ 2566763774 DPFInTemp "Temperature of engine combustion byproducts entering the diesel particulate filter in exhaust bank 1.";
CM_ SG_ 2566763774 ExhTemp1 "The reading from the exhaust temperature sensor located farthest upstream in the aftertreatment system in exhaust bank 1.";
CM_ SG_ 2631728894 AntitheftRandomNumber_1198 "A seven byte random numeric code provided by the component in response to an anti-theft request.  This parameter is sent as a numeric value utilizing the full range of 0 to 0xFFFFFFFFFFFFFF.  The most significant byte is sent first, not following ...";
CM_ SG_ 2631728894 AntitheftModifyPwdStates_1197 "This parameter is used to indicate whether a password request was successfully performed, or if the request could not be perform due to system constraints or if the request was not a valid request.
00 Ok
01 Full_of_Passwords
10 Empty_of_Passwords
...";
CM_ SG_ 2631728894 AntiThftCptStatusStates_1196 "Indicates whether or not the component can be started.
00 Unlocked
01 Locked
10 Blocked
11 Not defined
00b -  Unlocked = This state indicates that the component can be started without the end user being required to enter a password.
01b - ...";
CM_ SG_ 2631728894 AntitheftPwdValidIndicator_1195 "Indicates the presence of a validated password.
00 - Password is not a validated password
01 - Password is a validated password
10 - Error
11 - Not available";
CM_ SG_ 2631728894 AntiThftEncrpSeedPrestIndcr_1194 "Indicates the presence of the encryption seed random number.
00 - Random number is not present
01 - Random number is present
10 - Error
11 - Not available";
CM_ SG_ 2631794430 AntiThftPwdRepresentation_1202 "This parameter is the seven byte numeric code (i.e., ‘encrypted password’ or ‘key’) that is generated based on the encryption algorithm, the password supplied by the end user, and the random number seed given by the component.  This parameter is ...";
CM_ SG_ 2631794430 AntiTheftCmdStates_1201 "This parameter is used to identify the specific requests being sent to the component.
000 Add_Password
001 Delete_Password
010 Change_Password
011 Lock_or_Unlock
100 Check_Status
101 Login
110-111 Not defined
000b - Add_Password—This state ...";
CM_ SG_ 2631794430 AntiThftDesExitModeStates_1200 "This parameter is used to specify the desired triggers that are to be used by the component in deciding when to transition to the Locked state.
00 Lock_Upon_Operator_Request
01 Lock_When_Key_Off
10 Not defined
11 Not_Available
00b - ...";
CM_ SG_ 2631794430 AntiThftEncrpnIndcrStates_1199 "This parameter is used to indicate if a random number seed is being requested, or if an encrypted password is being provided to the component.
00 Encryption_Seed_Request
01 Encrypted_Code_Present
10 Not defined
11 Not_Available
00b - ...";
CM_ SG_ 2633934846 EngAltWinding3Temp "Temperature of the windings inside the alternator.";
CM_ SG_ 2633934846 EngAltWinding2Temp "Temperature of the windings inside the alternator.";
CM_ SG_ 2633934846 EngAltWinding1Temp "Temperature of the windings inside the alternator.";
CM_ SG_ 2633934846 EngAltBearing2Temp "Temperature of the bearing inside the alternator.  Bearing 2 is the right or front bearing.";
CM_ SG_ 2633934846 EngAltBearing1Temp "Temperature of the bearing inside the alternator.  Bearing 1 is the left or rear bearing.";
CM_ SG_ 2362572542 LevelPresetRearAxleRight_1735 "Set value for nominal level 'preset level' at the right side of the rear axle. This value is referred to 'Normal level 1'.  For explanations of normal level 1 see SPN 1734 - Nominal Level Front Axle.";
CM_ SG_ 2362572542 LevelPresetRearAxleLeft_1758 "Set value for nominal level 'preset level' at the left side of the rear axle. This value is referred to 'Normal level 1'.  For explanations of normal level 1 see SPN 1734 - Nominal Level Front Axle.";
CM_ SG_ 2362572542 LevelPresetFrontAxleRight_1757 "Set value for nominal level 'preset level' at the right side of the front axle. This value is referred to 'Normal level 1'.  For explanations of normal level 1 see SPN 1734 - Nominal Level Front Axle.";
CM_ SG_ 2362572542 LevelPresetFrontAxleLeft_1732 "Set value for nominal level 'preset level' at the left side of the front axle. This value is referred to 'Normal level 1'.  For explanations of normal level 1 see parameter SPN 1734 - Nominal Level Front Axle.";
CM_ SG_ 2365478910 ElctrncShckAbsrbrCtrlMdLft_TgAxl "Signal which indicates the current mode of operation of the electronic shock absorber control at the lift/tag axle.
00 Normal operation dampers passive
01 Normal operation dampers active
10 Error
11 Not available";
CM_ SG_ 2365478910 ElctrncShckAbsrbrCtrlMdeRearAxle "Signal which indicates the current mode of operation of the electronic shock absorber control at the rear axle.
00 Normal operation dampers passive
01 Normal operation dampers active
10 Error
11 Not available";
CM_ SG_ 2365478910 ElctrncShckAbsrbrCtrlMdFrontAxle "Signal which indicates the current mode of operation of the electronic shock absorber control at the front axle.
00 Normal operation dampers passive
01 Normal operation dampers active
10 Error
11 Not available";
CM_ SG_ 2365478910 DamperStiffnessLift_TagAxle "Damper stiffness information of the shock absorber control at the lift of tag axle";
CM_ SG_ 2365478910 DamperStiffnessRearAxle "Damper stiffness information of the shock absorber control at the rear axle";
CM_ SG_ 2365478910 DamperStiffnessFrontAxle "Damper stiffness information of the shock absorber control at the front axle";
CM_ SG_ 2560950014 SPN1_1214 "This 19-bit number is used to identify the item for which diagnostics are being reported.";
CM_ SG_ 2560950014 TestLimitMinimum_4112 "The test value must be greater than or equal to Test Limit Minimum in order for the test to pass";
CM_ SG_ 2560950014 FailureModeIdentifier1_1215 "The FMI defines the type of failure detected in the subsystem identified by an SPN.";
CM_ SG_ 2560950014 TestLimitMaximum_4111 "The test value must be less than or equal to Test Limit Maximum in order for the test to pass.";
CM_ SG_ 2560950014 TestValue_4110 "The test value collected during the test.";
CM_ SG_ 2560950014 SlotId_4109 "The SLOT Identifer is used to determine the multiplier and offset to be used to scale the test value.";
CM_ SG_ 2560950014 TestIdentifier "Test Identifier";
CM_ SG_ 2560950014 SPN1High "SPN #1 (Conversion Version 4)";
CM_ SG_ 2566763262 DPFIntmdTempPreliminaryFMI "Used to identify the applicable J1939-73 FMI detected in the diesel particulate filter intermediate temperature sensor by the manufacturer’s sensor control software in exhaust bank 1.  When there is no failure FMI 31 is sent.  In the case of ...";
CM_ SG_ 2566763262 DPFDiffPressPreliminaryFMI "Used to identify the applicable J1939-73 FMI detected in the diesel particulate filter differential pressure sensor by the manufacturer’s sensor control software in exhaust bank 1.  When there is no failure FMI 31 is sent.  In the case of multiple ...";
CM_ SG_ 2566763262 ExhTemp2PreliminaryFMI "Used to identify the applicable J1939-73 FMI detected in the exhaust temperature 2 sensor by the manufacturer’s sensor control software in exhaust bank 1.  When there is no failure FMI 31 is sent.  In the case of multiple failures the most severe is ...";
CM_ SG_ 2566763262 DPFDiffPress "Exhaust differential pressure measured between the intake and exhaust of a diesel particulate filter in exhaust bank 1.";
CM_ SG_ 2566763262 DPFIntmdTemp "Temperature of engine combustion byproducts at a mid-point in the diesel particulate filter in exhaust bank 1.";
CM_ SG_ 2566763262 ExhTemp2 "The reading from the exhaust temperature sensor located midstream of the other two temperature sensors in the aftertreatment system in exhaust bank 1.";
CM_ SG_ 2565869566 OutletOxyzenSnsr1PrelFMI_3235 "Used to identify the applicable J1939-73 FMI detected in the aftertreatment outlet oxygen sensor by the manufacturer’s sensor control software in exhaust bank 1.  When there is no failure FMI 31 is sent.  In the case of multiple failures the most ...";
CM_ SG_ 2565869566 OutletNOxSnsr1SelfDiagSts_5713 "Self-diagnosis result status for NOx sensor ATO1 (Aftertreatment Outlet Bank 1)
000 Diagnosis not active
001 NOx Sensor ATO1 Self Diagnosis active flag
010 NOx Sensor ATO1 Self Diagnosis Result Complete
011 NOx Sensor ATO1 Self Diagnosis aborted
...";
CM_ SG_ 2565869566 OutletNOxSnsr1PrelFMI_3234 "Used to identify the applicable J1939-73 FMI detected in the aftertreatment outlet NOx sensor by the manufacturer’s sensor control software in exhaust bank 1.  When there is no failure FMI 31 is sent.  In the case of multiple failures the most ...";
CM_ SG_ 2565869566 OutletGasSnsr1HeatrCtrl_3233 "Indicates the heater status in the warm-up process.  Upon receiving a power-up command, the gas sensor ramps up according to a manufacturer defined profile.  The Preheat 1, Preheat 2, and Automatic messages are regions within this profile in exhaust ...";
CM_ SG_ 2565869566 OutletGasSnsr1HeatrPrelFMI_3232 "Used to identify the applicable J1939-73 FMI detected in the heater of the outlet exhaust gas sensor, either NOx or O2, by the manufacturer’s sensor control software in exhaust bank 1.  When there is no failure FMI 31 is sent.  In the case of ...";
CM_ SG_ 2565869566 OutletWideRngPercOxyzen1_3231 "Indicates that the percent oxygen reading of the aftertreatment outlet gas sensor, either NOx or O2, is stable as determined by the manufacturer's control software in exhaust bank 1.
00 - Not stable
01 - Stable
10 - Error
11 - Not available";
CM_ SG_ 2565869566 OutletNOx1ReadingStable_3230 "Indicates that the NOx reading of the aftertreatment outlet NOx sensor is stable as determined by the manufacturer’s control software in exhaust bank 1.
00 - Not stable
01 - Stable
10 - Error
11 - Not available";
CM_ SG_ 2565869566 OutletGasSnsr1AtTemp_3229 "Indicates that the heater element of the aftertreatment outlet gas sensor, either NOx or O2, is within the manufacturer’s specified range for accurate measurements in exhaust bank 1.
00 - Not in range
01 - In range
10 - Error
11 - Not available
...";
CM_ SG_ 2565869566 OutletGasSnsr1PwrInRng_3228 "Indicates that the power supplied to the aftertreatment outlet gas sensor, either NOx or O2, is within the manufacturer’s specification in exhaust bank 1. This parameter reports the status as reported by the sensor.
00 - Not in range
01 - In range
...";
CM_ SG_ 2565869566 OutletPercentOxyzen1_3227 "The actual oxidation factor (percent oxygen) of the gas within the exhaust stream.  For positive values, the parameter represents the percent oxygen in excess of the amount required for stoichiometric combustion.  For negative values, the parameter ...";
CM_ SG_ 2565869566 OutletNOx1_3226 "The amount of combined NO and NO2 in the exhaust exiting the aftertreatment system measured by a NOx sensor at the aftertreatment outlet, represented in NOx molecule parts per million non-NOx molecules in exhaust bank 1.
SPN 3226 shall display the ...";
CM_ SG_ 2566763518 DPFOutExhTempPreliminaryFMI "Used to identify the applicable J1939-73 FMI detected in the diesel particulate filter outlet temperature sensor by the manufacturer’s sensor control software in exhaust bank 1.  When there is no failure FMI 31 is sent.  In the case of multiple ...";
CM_ SG_ 2566763518 ExhTemp3PreliminaryFMI "Used to identify the applicable J1939-73 FMI detected in the exhaust temperature 3 sensor by the manufacturer’s sensor control software in exhaust bank 1.  When there is no failure FMI 31 is sent.  In the case of multiple failures the most severe is ...";
CM_ SG_ 2566763518 DPFOutTemp "Temperature of engine combustion byproducts leaving the diesel particulate filter exhaust in exhaust bank 1.";
CM_ SG_ 2566763518 ExhTemp3 "The reading from the exhaust temperature sensor located farthest downstream in the aftertreatment system in exhaust bank 1.";
CM_ SG_ 2566749182 DPFSootLoadRegenThreshold "This parameter indicates the value that will first cause DPF regeneration in aftertreatment 1. There may be multiple parameters that cause DPF regeneration (e.g. Percent Soot Load, DPF delta pressure converted to normalized percentage, etc.).  If ...";
CM_ SG_ 2566749182 DPFTimeSinceLastActiveRegen "Indicates the time since the last active regeneration event of diesel particulate filter 1.";
CM_ SG_ 2566749182 DPFAshLoadPercent "Indicates the ash load percent of diesel particulate filter 1.  100% is the level at which diesel particulate filter ash service should be performed.
100% level is the target ash service interval (and if ash service is not immediately performed, ...";
CM_ SG_ 2566749182 DPFSootLoadPercent "Indicates the soot load percent of diesel particulate filter 1.  100% is the level at which active diesel particulate filter regeneration should be triggered.
100% level is the active regeneration trigger level (and if conditions are not favorable ...";
CM_ SG_ 2566748670 DPFTripNumOfActiveRegenManReq "Total number of aftertreatment 1 diesel particulate filter active regeneration manual requests by the operator during the current trip period.
NOTE: This SPN needs to be reset by the reset PGN 56832.";
CM_ SG_ 2566748670 DPFTripNumOfActiveRegenInhReq "Total number of aftertreatment 1 diesel particulate filter active regeneration inhibit requests by the operator during the current trip period.
NOTE: This SPN needs to be reset by the reset PGN 56832.";
CM_ SG_ 2566748670 DPFTripNumOfPassiveRegens "Total number of passive regenerations of the aftertreatment 1 diesel particulate filter during the current trip period.
NOTE: This SPN needs to be reset by the reset PGN 56832.";
CM_ SG_ 2566748670 DPFTripPassiveRegenTime "Total amount of time that the aftertreatment 1 diesel particulate filter has been in passive regeneration during the current trip period.
NOTE: This SPN needs to be reset by the reset PGN 56832.";
CM_ SG_ 2566748670 DPFTripNumOfActiveRegens "Total number of active regenerations of the aftertreatment 1 diesel particulate filter during the current trip period.
NOTE: This SPN needs to be reset by the reset PGN 56832.";
CM_ SG_ 2566748670 DPFTripDisdTime "Total amount of time that aftertreatment 1 diesel particulate filter regeneration has been manually disabled during the current trip period.
NOTE: This SPN needs to be reset by the reset PGN 56832.";
CM_ SG_ 2566748670 DPFTripActiveRegenTime "Total amount of time that the aftertreatment 1 diesel particulate filter has been in active regeneration during the current trip period.
NOTE: This SPN needs to be reset by the reset PGN 56832.";
CM_ SG_ 2566748670 DPFTripFuelUsed "Total amount of fuel used by the aftertreatment 1 diesel particulate filter during the current trip period.
NOTE: This SPN needs to be reset by the reset PGN 56832.";
CM_ SG_ 2566758142 EnableAct "Indicates whether aftertreatment 2 air enable actuator is on or off
00   not active
01   active
10   reserved for SAE assignment
11   not available";
CM_ SG_ 2566758142 PurgeAirAct "Indicates whether aftertreatment 2 purge air actuator is on or off
00   not active
01   active
10   reserved for SAE assignment
11   not available";
CM_ SG_ 2566758142 AtomizationAirAct "Indicates whether aftertreatment 2 atomization air actuator is on or off
00   not active
01   active
10   reserved for SAE assignment
11   not available";
CM_ SG_ 2566758142 SysRelay "Indicates whether aftertreatment 2 air system relay is on or off
00   not active
01   active
10   reserved for SAE assignment
11   not available";
CM_ SG_ 2566758142 PressActPos "Position of the aftertreatment 2 air pressure actuator as measured by a position feedback sensor.";
CM_ SG_ 2566758142 PressCtrl "Position that the controller is commanding the aftertreatment 2 air pressure control to maintain.  0% = fully closed, 100% = fully open";
CM_ SG_ 2566758142 PurgeAirPress "Pressure of the purge air supply for aftertreatment 2";
CM_ SG_ 2566758142 SupplyAirPress "Pressure of the supply air for aftertreatment 2.  Supply air is the air supplied from a pneumatic line for an air-assisted or pneumatic actuator.  One example is an air assisted fuel injector (the supply air assists in the atomization of fuel).";
CM_ SG_ 2566745342 SecondAirPress "Pressure of the secondary air for aftertreatment 2.  Secondary air is air provided to the exhaust system (per SAE J2403).
For absolute pressure, see SPN 5590.";
CM_ SG_ 2566745342 SecondAirMFR "Indicates the secondary air mass flow for aftertreatment 2.  Secondary air is the air provided to the exhaust system (per SAE J2403).";
CM_ SG_ 2566745342 SecondAirTemp "Indicates the secondary air temperature for aftertreatment 2.  Secondary air is air provided to the exhaust system (per SAE J2403).";
CM_ SG_ 2566745342 SecondAirDiffPress "Indicates the secondary air differential pressure for aftertreatment 2.  Secondary air is air provided to the exhaust system (per SAE J2403).";
CM_ SG_ 2566758654 Injector1HtrCtrl "Heating level that the controller is commanding the aftertreatment 2 fuel injector 1 heater control to maintain. 0% = off, 100% = maximum.";
CM_ SG_ 2566758654 EnableAct "Indicates whether aftertreatment 2 fuel enable actuator is on or off
00   not active
01   active
10   reserved for SAE assignment
11   not available";
CM_ SG_ 2566758654 RegenStatus "Indicates whether regeneration is active or inactive in aftertreatment 2.
00   not active
01   active
10   reserved for SAE assignment
11   not available";
CM_ SG_ 2566758654 Ignt "Indicates whether aftertreatment 2 ignition circuit is energized by the ECU.
00   not active
01   active
10   reserved for SAE assignment
11   not available";
CM_ SG_ 2566758654 DrainAct "Indicates whether aftertreatment 2 fuel drain actuator is on or off
00   not active
01   active
10   reserved for SAE assignment
11   not available";
CM_ SG_ 2566758654 Press1Ctrl "Position that the controller is commanding the aftertreatment 2 fuel pressure control to maintain.  0% = fully closed, 100% = fully open.";
CM_ SG_ 2566758654 Rate "Rate of fuel being delivered to aftertreatment 2 for regeneration";
CM_ SG_ 2566758654 Press1 "Pressure of the fuel for Aftertreatment 2.";
CM_ SG_ 2566753278 DPFOutPress "This parameter indicates the diesel particulate filter outlet gage pressure 2 (bank 2).";
CM_ SG_ 2566753278 DPFInPress "This parameter indicates the diesel particulate filter intake gage pressure 2 (bank 2).";
CM_ SG_ 2566756862 DPFAvgDistBetweenActiveRegens "Indicates the average distance since last reset between active regenerations, that have not been forced to occur by manual request, for aftertreatment device 2.
If the manufacturer allows this parameter to be reset, this distance is the average ...";
CM_ SG_ 2566756862 DPFAvgTimeBetweenActiveRegens "Indicates the average time since last reset between active regenerations, that have not been forced to occur by manual request, for Aftertreatment device 2.";
CM_ SG_ 2566756862 DPFTotalNumOfActiveRegenManReq "Total number of Aftertreatment device 2 active regeneration manual requests by the operator over the lifetime of the device.";
CM_ SG_ 2566756862 DPFTotalNumOfActiveRegenInhReq "Total number of Aftertreatment device 2 active regeneration inhibit requests by the operator over the lifetime of the device.";
CM_ SG_ 2566756862 DPFTotalNumOfPassiveRegens "Total number of passive regenerations by Aftertreatment device 2 over the lifetime of the device.";
CM_ SG_ 2566756862 DPFTotalPassiveRegenTime "Total amount of time that Aftertreatment device 2 has been in passive regeneration over the lifetime of the device.";
CM_ SG_ 2566756862 TotalNumOfActiveRegens "Total number of active regenerations by aftertreatment device 2 over the lifetime of the device.";
CM_ SG_ 2566756862 TotalDisdTime "Total amount of time that aftertreatment 2 regeneration has been manually disabled.";
CM_ SG_ 2566756862 TotalRegenTime "Total amount of time that aftertreatment device 2 has been regenerating over the lifetime of the device.";
CM_ SG_ 2566756862 TotalFuelUsed "Total amount of fuel used by aftertreatment device 2 over the lifetime of the device.";
CM_ SG_ 2565869822 IntkNOxSnsr1SelfDiagStatus_5716 "Self-diagnosis result status for NOx sensor ATI2 (Aftertreatment Intake Bank 2)
000 Diagnosis not active
001 NOx Sensor ATI2 Self Diagnosis active flag
010 NOx Sensor ATI2 Self Diagnosis Result Complete
011 NOx Sensor ATI2 Self Diagnosis aborted
...";
CM_ SG_ 2565869822 IntkOxyzenSnsr1PrelFMI_3264 "Used to identify the applicable J1939-73 FMI detected in the aftertreatment intake oxygen sensor by the manufacturer’s sensor control software in exhaust bank 2.  When there is no failure FMI 31 is sent.  In the case of multiple failures the most ...";
CM_ SG_ 2565869822 SCRIntkNOxSnsr1PrelFMI_3263 "Used to identify the applicable J1939-73 FMI detected in the aftertreatment intake NOx sensor by the manufacturer’s sensor control software in exhaust bank 2.  When there is no failure FMI 31 is sent.  In the case of multiple failures the most ...";
CM_ SG_ 2565869822 IntkGasSnsr1HeatrCtl_3262 "Indicates the heater status in the warm-up process.  Upon receiving a power-up command, the gas sensor ramps up according to a manufacturer defined profile.  The Preheat 1, Preheat 2, and Automatic messages are regions within this profile in exhaust ...";
CM_ SG_ 2565869822 IntkGasSnsr1HeatrPrelFMI_3261 "Used to identify the applicable J1939-73 FMI detected in the heater of the intake exhaust gas sensor, either NOx or O2, by the manufacturer’s sensor control software in exhaust bank 2.  When there is no failure FMI 31 is sent.  In the case of ...";
CM_ SG_ 2565869822 IntkWideRngPercOxyzen1_3260 "Indicates that the percent oxygen reading of the aftertreatment intake gas sensor, either NOx or O2, is stable as determined by the manufacturer's control software in exhaust bank 2.
For a single exhaust bank system, refer to parameters in PGNs ...";
CM_ SG_ 2565869822 SCRIntkNOx1ReadingStable_3259 "Indicates that the NOx reading of the aftertreatment intake NOx sensor is stable as determined by the manufacturer’s control software in exhaust bank 2.
For a single exhaust bank system, refer to parameters in PGNs 61454, 61455,  64946, 64947, ...";
CM_ SG_ 2565869822 IntkGasSnsr1AtTemp_3258 "Indicates that the heater element of the aftertreatment intake gas sensor, either NOx or O2, is within the manufacturer’s specified range for accurate measurements in exhaust bank 2.
For a single exhaust bank system, refer to parameters in PGNs ...";
CM_ SG_ 2565869822 IntkGasSnsr1PwrInRange_3257 "Indicates that the power supplied to the aftertreatment intake gas sensor, either NOx or O2, is within the manufacturer’s specification in exhaust bank 2.
For a single exhaust bank system, refer to parameters in PGNs 61454, 61455,  64946, 64947, ...";
CM_ SG_ 2565869822 IntkPercOxyzen1_3256 "The actual oxidation factor (percent oxygen) of the gas within the exhaust stream.  For positive values, the parameter represents the percent oxygen in excess of the amount required for stoichiometric combustion.  For negative values, the parameter ...";
CM_ SG_ 2565869822 SCRIntkNOx1_3255 "The amount of combined NO and NO2 in the exhaust entering the aftertreatment system measured by a NOx sensor at the aftertreatment intake, represented in NOx molecule parts per million non-NOx molecules in exhaust bank 2.
For a single exhaust bank ...";
CM_ SG_ 2566763006 DPFInTempPreliminaryFMI "Used to identify the applicable J1939-73 FMI detected in the diesel particulate filter intake temperature sensor by the manufacturer’s sensor control software in exhaust bank 2.  When there is no failure FMI 31 is sent.  In the case of multiple ...";
CM_ SG_ 2566763006 ExhTemp1PreliminaryFMI "Used to identify the applicable J1939-73 FMI detected in the exhaust temperature 1 sensor by the manufacturer’s sensor control software in exhaust bank 2.  When there is no failure FMI 31 is sent.  In the case of multiple failures the most severe is ...";
CM_ SG_ 2566763006 DPFInTemp "Temperature of engine combustion byproducts entering the diesel particulate filter in exhaust bank 2.  (For a single exhaust bank system, refer to parameters in PGNs 61454, 61455,  64946, 64947, 64948, and 65247)";
CM_ SG_ 2566763006 ExhTemp1 "The reading from the exhaust temperature sensor located farthest upstream in the aftertreatment system in exhaust bank 2.  (For a single exhaust bank system, refer to parameters in PGNs 61454, 61455,  64946, 64947, 64948, and 65247)";
CM_ SG_ 2566762494 DPFIntmdTempPreliminaryFMI "Used to identify the applicable J1939-73 FMI detected in the diesel particulate filter intermediate temperature sensor by the manufacturer’s sensor control software in exhaust bank 2.  When there is no failure FMI 31 is sent.  In the case of ...";
CM_ SG_ 2566762494 DPFDiffPressPreliminaryFMI "Used to identify the applicable J1939-73 FMI detected in the diesel particulate filter differential pressure sensor by the manufacturer’s sensor control software in exhaust bank 2.  When there is no failure FMI 31 is sent.  In the case of multiple ...";
CM_ SG_ 2566762494 ExhTemp2PreliminaryFMI "Used to identify the applicable J1939-73 FMI detected in the exhaust temperature 2 sensor by the manufacturer’s sensor control software in exhaust bank 2.  When there is no failure FMI 31 is sent.  In the case of multiple failures the most severe is ...";
CM_ SG_ 2566762494 DPFDiffPress "Exhaust differential pressure measured between the intake and exhaust of a diesel particulate filter in exhaust bank 2.  (For a single exhaust bank system, refer to parameters in PGNs 61454, 61455,  64946, 64947, 64948, and 65247)";
CM_ SG_ 2566762494 DPFIntmdTemp "Temperature of engine combustion byproducts at a mid-point in the diesel particulate filter in exhaust bank 2.  (For a single exhaust bank system, refer to parameters in PGNs 61454, 61455,  64946, 64947, 64948, and 65247)";
CM_ SG_ 2566762494 ExhTemp2 "The reading from the exhaust temperature sensor located midstream of the other two temperature sensors in the aftertreatment system in exhaust bank 2.  (For a single exhaust bank system, refer to parameters in PGNs 61454, 61455,  64946, 64947, ...";
CM_ SG_ 2565870078 OutletOxyzenSnsr1PrelFMI_3274 "Used to identify the applicable J1939-73 FMI detected in the aftertreatment outlet oxygen sensor by the manufacturer’s sensor control software in exhaust bank 2.  When there is no failure FMI 31 is sent.  In the case of multiple failures the most ...";
CM_ SG_ 2565870078 OutletNOxSnsr1PrelFMI_3273 "Used to identify the applicable J1939-73 FMI detected in the aftertreatment outlet NOx sensor by the manufacturer’s sensor control software in exhaust bank 2.  When there is no failure FMI 31 is sent.  In the case of multiple failures the most ...";
CM_ SG_ 2565870078 OutletGasSnsr1HtrCtl_3272 "Indicates the heater status in the warm-up process.  Upon receiving a power-up command, the gas sensor ramps up according to a manufacturer defined profile.  The Preheat 1, Preheat 2, and Automatic messages are regions within this profile in exhaust ...";
CM_ SG_ 2565870078 OutletGasSnsr1HeatrPrelFMI_3271 "Used to identify the applicable J1939-73 FMI detected in the heater of the outlet exhaust gas sensor, either NOx or O2, by the manufacturer’s sensor control software in exhaust bank 2.  When there is no failure FMI 31 is sent.  In the case of ...";
CM_ SG_ 2565870078 OutletWidRngPercO21RdingStb_3270 "Indicates that the percent oxygen reading of the aftertreatment outlet gas sensor, either NOx or O2, is stable as determined by the manufacturer's control software in exhaust bank 2.
For a single exhaust bank system, refer to parameters in PGNs ...";
CM_ SG_ 2565870078 OutletNOx1ReadingStable_3269 "Indicates that the NOx reading of the aftertreatment outlet NOx sensor is stable as determined by the manufacturer’s control software in exhaust bank 2.
For a single exhaust bank system, refer to parameters in PGNs 61454, 61455,  64946, 64947, ...";
CM_ SG_ 2565870078 OutletNOxSnsr1SelfDiagSts_5715 "Self-diagnosis result status for NOx sensor ATO2 (Aftertreatment Outlet Bank 2)
000 Diagnosis not active
001 NOx Sensor ATO2 Self Diagnosis active flag
010 NOx Sensor ATO2 Self Diagnosis Result Complete
011 NOx Sensor ATO2 Self Diagnosis aborted
...";
CM_ SG_ 2565870078 OutletGasSnsr1AtTemp_3268 "Indicates that the heater element of the aftertreatment outlet gas sensor, either NOx or O2, is within the manufacturer’s specified range for accurate measurements in exhaust bank 2.
For a single exhaust bank system, refer to parameters in PGNs ...";
CM_ SG_ 2565870078 OutletGasSnsr1PwrInRange_3267 "Indicates that the power supplied to the aftertreatment outlet gas sensor, either NOx or O2, is within the manufacturer’s specification in exhaust bank 2.
For a single exhaust bank system, refer to parameters in PGNs 61454, 61455,  64946, 64947, ...";
CM_ SG_ 2565870078 OutletPercentOxyzen1_3266 "The actual oxidation factor (percent oxygen) of the gas within the exhaust stream.  For positive values, the parameter represents the percent oxygen in excess of the amount required for stoichiometric combustion.  For negative values, the parameter ...";
CM_ SG_ 2565870078 OutletNOx1_3265 "The amount of combined NO and NO2 in the exhaust entering the aftertreatment system measured by a NOx sensor at the aftertreatment outlet, represented in NOx molecule parts per million non-NOx molecules in exhaust bank 2.
For a single exhaust bank ...";
CM_ SG_ 2566762750 DPFExhTempPreliminaryFMI "Used to identify the applicable J1939-73 FMI detected in the diesel particulate filter outlet temperature sensor by the manufacturer’s sensor control software in exhaust bank 2.  When there is no failure FMI 31 is sent.  In the case of multiple ...";
CM_ SG_ 2566762750 ExhTemp3PreliminaryFMI "Used to identify the applicable J1939-73 FMI detected in the exhaust temperature 3 sensor by the manufacturer’s sensor control software in exhaust bank 2.  When there is no failure FMI 31 is sent.  In the case of multiple failures the most severe is ...";
CM_ SG_ 2566762750 DPFOutTemp "Temperature of engine combustion byproducts leaving the diesel particulate filter exhaust in exhaust bank 2.  (For a single exhaust bank system, refer to parameters in PGNs 61454, 61455,  64946, 64947, 64948, and 65247)";
CM_ SG_ 2566762750 ExhTemp3 "The reading from the exhaust temperature sensor located farthest downstream in the aftertreatment system in exhaust bank 2.  (For a single exhaust bank system, refer to parameters in PGNs 61454, 61455,  64946, 64947, 64948, and 65247)";
CM_ SG_ 2566748926 DPFSootLoadRegenThreshold "This parameter indicates the value that will first cause DPF regeneration in aftertreatment 2. There may be multiple parameters that cause DPF regeneration (e.g. Percent Soot Load, DPF delta pressure converted to normalized percentage, etc.).  If ...";
CM_ SG_ 2566748926 DPFTimeSinceLastActiveRegen "Indicates the time since the last active regeneration event of diesel particulate filter 2.";
CM_ SG_ 2566748926 DPFAshLoadPercent "Indicates the ash load percent of diesel particulate filter 2.  100% is the level at which diesel particulate filter ash service should be performed.
100% level is the target ash service interval (and if ash service is not immediately performed, ...";
CM_ SG_ 2566748926 DPFSootLoadPercent "Indicates the soot load percent of diesel particulate filter 2.  100% is the level at which active diesel particulate filter regeneration should be triggered.
100% level is the active regeneration trigger level (and if conditions are not favorable ...";
CM_ SG_ 2566748414 DPFTripNumOfActiveRegenManReq "Total number of aftertreatment 2 diesel particulate filter active regeneration manual requests by the operator during the current trip period.
NOTE: This SPN needs to be reset by the reset PGN 56832.";
CM_ SG_ 2566748414 DPFTripNumOfActiveRegenInhReq "Total number of aftertreatment 2 diesel particulate filter active regeneration inhibit requests by the operator during the current trip period.
NOTE: This SPN needs to be reset by the reset PGN 56832.";
CM_ SG_ 2566748414 DPFTripNumOfPassiveRegens "Total number of passive regenerations of the aftertreatment 2 diesel particulate filter during the current trip period.
NOTE: This SPN needs to be reset by the reset PGN 56832.";
CM_ SG_ 2566748414 DPFTripPassiveRegenTime "Total amount of time that the aftertreatment 2 diesel particulate filter has been in passive regeneration during the current trip period.
NOTE: This SPN needs to be reset by the reset PGN 56832.";
CM_ SG_ 2566748414 DPFTripNumOfActiveRegens "Total number of active regenerations of the aftertreatment 2 diesel particulate filter during the current trip period.
NOTE: This SPN needs to be reset by the reset PGN 56832.";
CM_ SG_ 2566748414 DPFTripDisdTime "Total amount of time that aftertreatment 2 diesel particulate filter regeneration has been manually disabled during the current trip period.
NOTE: This SPN needs to be reset by the reset PGN 56832.";
CM_ SG_ 2566748414 DPFTripActiveRegenTime "Total amount of time that the aftertreatment 2 diesel particulate filter has been in active regeneration during the current trip period.
NOTE: This SPN needs to be reset by the reset PGN 56832.";
CM_ SG_ 2566748414 DPFTripFuelUsed "Total amount of fuel used by the aftertreatment 2 diesel particulate filter during the current trip period.
NOTE: This SPN needs to be reset by the reset PGN 56832.";
CM_ SG_ 2365428478 EngDesiredTorqueRq "This is the torque that the ECM desires to provide. It is a request made from the ECM to an external system. A valid value within the operating range indicates the engine is requesting an external controller to change the operation of the system so ...";
CM_ SG_ 2365428478 EngColdAmbientElevatedIdleStatus "Indicates that the engine is elevating the idle speed due to cold strategies.
00 No Idle Elevation Active - standard idle speed
01 Idle Elevation Active
10 Reserved for SAE assignment
11 Unavailable";
CM_ SG_ 2365428478 EngStarterMotorRelayCtrl "Command signal used to energize or de-energize the engine starter motor relay.
00 Off
01 On
10 Reserved for SAE assignment
11 Don't care/take no action";
CM_ SG_ 2365428478 EngDerateRq "This parameter is a derate request made from the engine control system to an external system, where the engine is requesting an external device to reduce the load being applied.  A zero value indicates that there is no derate being requested and ...";
CM_ SG_ 2365428478 EngEmergencyShutdownIndication "A signal issued by the engine control system to a user or external system indicating that it is immediately shutting the engine down.  This indication is made when engine protection diagnostics determine a condition necessitates an immediate ...";
CM_ SG_ 2365428478 EngControlledShutdownRq "A signal issued by the engine control system to a user or external system requesting for a controlled shutdown.  This request is made when engine protection diagnostics determine a condition warrants a shutdown soon, but it is not severe enough to ...";
CM_ SG_ 2365428478 EngCoolantCirculatingPumpCtrl "Control setting for an electrically actuated engine coolant circulating pump.
00 = Off
01 = On
10 = Reserved
11 = Don't care / take no action
.";
CM_ SG_ 2365428478 EngBlock_CoolantPreheaterCtrl "Control setting for an electrically actuated engine block or coolant pre-heating device.
00 - Off
01 - On
10 - Reserved
11 - Unavailable";
CM_ SG_ 2365428478 EngElctrclSystmPwrCnsrvationCtrl "Control setting for cutting power to various devices when the engine is not in use.  Useful if it is desired to keep the engine in standby, with main control ECU still powered on and communictaing with outside world, but actuators and certain other ...";
CM_ SG_ 2365428478 EngOilPreheaterCtrl "Control setting for an electrically actuated oil pre-heating device.
00 = Off
01 = On
10 = Reserved
11 = Don't care / take no action
In addition to communicating desired action of the electrically actuated oil pre-heater and its driver status, ...";
CM_ SG_ 2365428478 EngOilPrimingPumpCtrl "This control is used to activate a pump that lubricates the engine, particularly prior to initial engine startup.
00 = Off
01 = On
10 = Reserved
11 = unavailable";
CM_ SG_ 2365428478 EngFuelShutoffValveLeakTestCtrl "Control setting for fuel shutoff valve proving system test.  Typically, this type of system can only be used with a dual fuel shutoff system.  The test consists of a small pump to pressurize the chamber between the dual fuel shutoffs when they are ...";
CM_ SG_ 2365428478 EngFuelShutoff2Ctrl "Control setting for fuel shutoff 2.  First instance is SPN 632.  For a dual fuel shutoff system, this SPN is representative of the downstream fuel shutoff commanded position.  When fuel (gas) is desired at the engine, the fuel shutoff is opened ...";
CM_ SG_ 2365428478 EngFuelShutoff1Ctrl "Control setting for fuel shutoff 1.  The second instance is SPN 2807.  For a single fuel shutoff system, this represents its commanded position.  For a dual fuel shutoff system, this SPN is representative of the upstream fuel shutoff commanded ...";
CM_ SG_ 2365428478 EngFuelShutoffVentCtrl "Control setting for a fuel shutoff vent.  Typically, for a dual fuel shutoff system, the vent line is located between them and is plumbed to vent outside to atmosphere.  The vent control typically always actuates opposite to that of the fuel ...";
CM_ SG_ 2365428478 TimeRemainingInEngOperatingState "This parameter is used to indicate the time remaining in the current engine operating state, based on the state defined in the SPN \"Engine Operating State\" (SPN 3543). For the states in which time remaining is not applicable, use 65535 ($FFFF).";
CM_ SG_ 2365428478 FuelPumpPrimerCtrl "Parameter used to activate or deactivate a priming system on the fuel transfer system. The fuel priming system is a system that purges air in the fuel lines and may assist fuel delivery to a second pump at lower speeds.
00 = Deactivate
01 = ...";
CM_ SG_ 2365428478 EngOperatingState "This parameter is used to indicate the current state, or mode, of operation by the engine.  This is a status parameter.
Bit state 0000 = Engine Stopped
Bit state 0001 = Pre-Start
Bit state 0010 = Starting
Bit state 0011 = Warm-Up
Bit state 0100 ...";
CM_ SG_ 2566743806 EngCoolantTemp3 "Third temperature of liquid found in the engine cooling system. See also SPNs 110, 4076 and 4193.";
CM_ SG_ 2566743806 EngExhstGsRcrcltn1MxerIntakeTemp "The temperature of the EGR gas entering the intake mixer, measured after the intake throttle when provided.";
CM_ SG_ 2566743806 EngExhstVlvActationSystemOilTemp "The temperature of the oil in the hydraulic system that powers the engine exhaust valve actuation system";
CM_ SG_ 2566743806 EngCoolantThermostatOpening "The current position of the Thermostat used to regulate the temperature of the engine coolant.  0% represents the thermostat allows flow to completely bypass the radiator and 100% represents the flow is fully through the radiator.";
CM_ SG_ 2566743806 EngCoolantPumpOutletTemp "The actual value of engine coolant temperature at the coolant pump outlet.  See also SPNs 110, 4076 and 6209 for additional coolant temperature parameters.";
CM_ SG_ 2566743806 EngCoolantTemp2 "Second temperature of liquid found in the engine cooling system.   See also SPNs 110, 4193 and 6209.";
CM_ SG_ 2499635454 NetVehicleWeightChange "Identifies the net vehicle weight change from the time of last vehicle net weight zeroing.";
CM_ SG_ 2499635454 GrossCombinationWeight "Total weight of the truck and all the trailers with on-board scales.";
CM_ SG_ 2550660862 ValveAssemblySupplyPress_4089 "Pressure of the hydraulic supply port to a valve assembly.";
CM_ SG_ 2550660862 ValveAssemblyLoadSensePress_4088 "The maximum pressure of a valve assembly's current collective load sense pressures where a valve assembly can consist of two or more valves.";
CM_ SG_ 2550660862 ValvePilotPress_4087 "Pressure of a valve's pilot supply port.";
CM_ SG_ 2550660862 ValveLoadSensePress_4086 "The maximum of the currently measured pressures of a valve's work port A and work port B.";
CM_ SG_ 2566805758 BellowPressRearAxleRight "Information of the pressure of the air suspension bellow at the right side of the rear axle";
CM_ SG_ 2566805758 BellowPressRearAxleLeft "Information of the pressure of the air suspension bellow at the left side of the rear axle";
CM_ SG_ 2566805758 BellowPressFrontAxleRight "Information of the pressure of the air suspension bellow at the right side of the front axle";
CM_ SG_ 2566805758 BellowPressFrontAxleLeft "Information of the pressure of the air suspension bellow at the left side of the front axle";
CM_ SG_ 2566806014 RelativeLevelRearAxleRight "Information of the height at the left side of the rear axle referred to normal level 1.  For explanations of normal level 1 see parameter SPN 1734 - Nominal Level Front Axle.";
CM_ SG_ 2566806014 RelativeLevelRearAxleLeft "Information of the height at the left side of the rear axle referred to normal level 1.  For explanations of normal level 1 see parameter SPN 1734 - Nominal Level Front Axle.";
CM_ SG_ 2566806014 RelativeLevelFrontAxleRight "Information of the height at the right side of the front axle referred to normal level 1.  For explanations of normal level 1 see SPN 1734 - Nominal Level Front Axle.";
CM_ SG_ 2566806014 RelativeLevelFrontAxleLeft "Information of the height at the left side of the front axle referred to normal level 1.  For explanations of normal level 1 see SPN 1734 - Nominal Level Front Axle.";
CM_ SG_ 2362638078 MemoryLevelReq_5433 "Signal which indicates that the air suspension control requests a memory level or a memory level shall be stored.
The storage of  the current memory level is requested by  \"Store memory level x\". The acknowledge is set in \"memory level x stored\" ...";
CM_ SG_ 2362638078 ProhibitAASControl_5274 "This parameter is an internal request to the air suspension control system to prohibit automatic air suspension control.  If the request is accepted,  response intended to be sent in  ASC1 (additional status requested in ASC1), there will be no ...";
CM_ SG_ 2362638078 SpdDependentLevelCtrlRq_5295 "This parameter activates speed dependent level control in suspension system.
00 = Deactivate
01 = Activate
10 = Reserved
11 = Don’t care/take no action";
CM_ SG_ 2362638078 AllwLvlCtrlDuringBrakingCmd_5293 "This parameter overides the inhibit of level control during braking.
00 = Disallow level control during braking (normal operation)
01 = Allow level control during braking
10 = Reserved
11 = Don’t' care/take no action";
CM_ SG_ 2362638078 ProhibitAirSuspensionCtrl_3215 "This parameter is an external request to the air suspension control system to prohibit all air suspension control.  If the request is accepted,  response intended to be sent in  ASC1 (additional status requested in ASC1), there will be no control ...";
CM_ SG_ 2362638078 KneelingCmdRearAxle_1829 "Command signal to activate the kneeling functionality at the rear axle of the vehicle.
00 Deactivate kneeling
01 Activate kneeling
10 Reserved
11 Don't care/take no action";
CM_ SG_ 2362638078 KneelingCmdFrontAxle_1830 "Command signal to activate the kneeling functionality at the front axle of the vehicle
00 Deactivate kneeling
01 Activate kneeling
10 Reserved
11 Don't care/take no action";
CM_ SG_ 2362638078 DamprStfnReqLiftOrTagAxle_1720 "Demand value for the shock absorber control at the lift or tag axle";
CM_ SG_ 2362638078 DamperStiffnessRqRearAxle_1719 "Demand value for the shock absorber control at the rear  axle.";
CM_ SG_ 2362638078 DamperStiffnessRqFrontAxle_1718 "Demand value for the shock absorber control at the front axle.";
CM_ SG_ 2362638078 LiftAxle2PosCmd_1828 "Signal to command the position / load condition of lift / tag axle #2.  Numbering of lift/tag axles starts at front axle.
00 Lift axle position down / tag axle laden
01 Lift axle position up / tag axle unladen
10 Reserved
11 Don't care/take no ...";
CM_ SG_ 2362638078 LiftAxle1PosCmd_1752 "Signal to command the position/load condition of lift/tag axle #1.  Numbering of lift/tag axles starts at front axle.
00 Lift axle position down / tag axle laden
01 Lift axle position up / tag axle unladen
10 Reserved
11 Don't care/take no ...";
CM_ SG_ 2362638078 LevelCtrlModeRq_1753 "Command signal to activate a level control mode
0000    Normal operation; i.e. the system performs a \"pure\" control of the vehicle height
0001    Traction help (load transfer); i.e. the driven axle is loaded to a maximum value given by legislation ...";
CM_ SG_ 2362638078 NominalLevelRqRearAxle_1750 "Command signal to activate a level of the rear axle programmed and/or memorized in the ECU.  For explanations of nominal level see SPN 1734 - Nominal Level Front Axle.
0000 No level request
0001 Normal Level 1,(i.e. the level prescribed for normal ...";
CM_ SG_ 2362638078 NominalLevelRqFrontAxle_1751 "Command signal to activate a level of the front axle programmed and/or memorized in the ECU   For explanations of nominal level see SPN 1734 - Nominal Level Front Axle.
0000 No level request
0001 Normal Level 1,(i.e. the level prescribed for ...";
CM_ SG_ 2362638078 KneelingCtrlModeRq_1747 "Command signal to select the kneeling functionality
00 Automatically actuated
01 Manually actuated
10 Reserved
11 Don't care/take no action";
CM_ SG_ 2362638078 KneelingRqRightSide_1748 "Command signal to activate the kneeling functionality on the right side of the vehicle
00 No kneeling request
01 Kneeling request
10 Reserved
11 Don't care/take no action";
CM_ SG_ 2362638078 KneelingRqLeftSide_1749 "Command signal to activate the kneeling functionality on the left side of the vehicle
00 No kneeling request
01 Kneeling request
10 Reserved
11 Don't care/take no action";
CM_ SG_ 2362638078 AutomaticTractionHelp_2984 "This signal enables the traction help (load transfer) in case of an active ASR function
00   Disable automatic traction help
01   Enable automatic traction help
10   Reserved
11   Don't care";
CM_ SG_ 2365479678 MemoryLevel "Signal which indicates that the air suspension control has memory levels selected or stored.
Response to memory level request in ASC2 (byte 8.5). If the request was executed the respective status will be set. If the request was not executed ...";
CM_ SG_ 2365479678 SuspensionCtrlRefusalInformation "Signal which indicates that the air suspension control cannot perform a request due to the operating conditions. It also provides a reason for the refusal.
0000 Actual request not refused
0001 Axle load limit reached  (load transfer)
0010 Would ...";
CM_ SG_ 2365479678 SpeedDependantLevelCtrlStatus "This parameter indicates if the function Speed Dependant Level Control is active. The function is activated by SPN 5295.
00 = Inactive
01 = Active
10 = Reserved
11 = Don’t' care/take no action";
CM_ SG_ 2365479678 AllwLevelCtrlDuringBrakingStatus "This parameter indicates if the function Allow Level Control During Braking is active. Functions is activated by SPN 5293.
00 = Deactivated
01 = Activated
10 = Reserved
11 = Don’t care/take no action";
CM_ SG_ 2365479678 SuspensionRemoteCtrl2 "Signal which indicates that the suspension system is controlled by remote control #2. Remote control is an external unit to operate the suspension system.
00 Not active
01 Active
10 Error
11 Not available";
CM_ SG_ 2365479678 SuspensionRemoteCtrl1 "Signal which indicates that the suspension system is controlled by remote control #1. Remote control is an external unit to operate the suspension system.
00 Not active
01 Active
10 Error
11 Not available";
CM_ SG_ 2365479678 LiftAxle2Pos "Signal which indicates the position / load condition of lift axle / tag axle #2.   Numbering of lift/tag axles starts at front axle.  See SPN 6844 for more detail.
00 Lift axle position down / tag axle laden
01 Lift axle position up / tag axle ...";
CM_ SG_ 2365479678 RearAxleInBumperRange "Signal which indicates that the vehicle height at the rear axle (SPNs 1723 and 1724) is within the bumper range.
00 Actual level out of bumper range
01 Actual level within bumper range
10 Error
11 Not available";
CM_ SG_ 2365479678 FrontAxleInBumperRange "Signal which indicates that the vehicle height at the front axle (SPNs 1721 and 1722) is within the bumper range.
00 Actual level out of bumper range
01 Actual level within bumper range
10 Error
11 Not available";
CM_ SG_ 2365479678 LiftAxle1Pos "Signal which indicates the position / load condition of lift axle / tag axle 1.   Numbering of lift/tag axles starts at front axle.  See SPN 6843 for more detail.
00 Lift axle position down / tag axle laden
01 Lift axle position up / tag axle ...";
CM_ SG_ 2365479678 DoorRelease "Signal which indicates that the doors may be opened. [Please note: doors instead of door!]
In case a kneeling request is active the ASC indicates during lowering the vehicle \"doors shall not be opened\" as a security information until the kneeling ...";
CM_ SG_ 2365479678 VehicleMotionInhibit "Signal which indicates whether vehicle motion is inhibited.
00 Vehicle may be moved
01 Vehicle motion is inhibited
10 Error
11 Not available";
CM_ SG_ 2365479678 SecurityDevice "The signal which indicates the status of the security device.  An example of a security device is a curbstone feeler installed beneath the doors of a bus. If the security device becomes active during kneeling the kneeling process (lowering) is ...";
CM_ SG_ 2365479678 LevelCtrlMode "Signal which indicates the actual control mode of the air suspension system
0000    Normal operation; i.e. the system performs a \"pure\" control of the vehicle height
0001    Traction help (load transfer); i.e. the driven axle is loaded to a ...";
CM_ SG_ 2365479678 KneelingInformation "Signal which indicates the actual level change in case of kneeling function
0000 Not active,(i.e. the kneeling function is not active\")
0001 Lowering active,(i.e. the vehicle is lowered due to a kneeling request)
0010 Kneeling level reached,(i.e ...";
CM_ SG_ 2365479678 LiftingCtrlModeRearAxle "Signal which indicates the actual lifting level change at the rear axle
00 Lifting not active
01 Lifting active
10 Error
11 Not available";
CM_ SG_ 2365479678 LiftingCtrlModeFrontAxle "Signal which indicates the actual lifting level change at the front axle
00 Lifting not active
01 Lifting active
10 Error
11 Not available";
CM_ SG_ 2365479678 LoweringCtrlModeRearAxle "Signal which indicates the actual lowering level change at the rear axle
00 Lowering not active
01 Lowering active
10 Error
11 Not available";
CM_ SG_ 2365479678 LoweringCtrlModeFrontAxle "Signal which indicates the actual lowering level change at the front axle
00 Lowering not active
01 Lowering active
10 Error
11 Not available";
CM_ SG_ 2365479678 AboveNominalLevelRearAxle "Signal which indicates whether the actual height of the rear axle is above the nominal (desired) level of the rear axle. For explanations of nominal level see parameter SPN 1734 - Nominal Level Front Axle.
00 Not above
01 Above
10 Error
11 Not ...";
CM_ SG_ 2365479678 AboveNominalLevelFrontAxle "Signal which indicates whether the actual height of the front axle is above the nominal (desired) level of the front axle. For explanations of nominal level see SPN 1734 - Nominal Level Front Axle.
00 Not above
01 Above
10 Error
11 Not available
...";
CM_ SG_ 2365479678 BelowNominalLevelRearAxle "Signal which indicates whether the actual height of the rear axle is below the nominal (desired) level for the rear axle. For explanations of nominal level see SPN 1734 - Nominal Level Front Axle.
00 Not below
01 Below
10 Error
11 Not available
...";
CM_ SG_ 2365479678 BelowNominalLevelFrontAxle "Signal which indicates whether the actual height of the front axle is below the nominal (desired) level for the front axle. For explanations of nominal level see parameter SPN 1734 - Nominal Level Front Axle.
00 Not below
01 Below
10 Error
11 ...";
CM_ SG_ 2365479678 NominalLevelRearAxle "Signal which indicates the nominal (desired) height of the rear axle to be controlled by the suspension system.
For further explanations see SPN 1734 - Nominal Level Front Axle.
0000 Level not specified,(i.e. the nominal level is none of the ...";
CM_ SG_ 2365479678 NominalLevelFrontAxle "Signal which indicates the nominal (desired) height of the front axle to be controlled by the suspension system.
These heights are discrete levels.  They are the upper level, lower level, normal level 1, normal level 2, normal level 3, customer ...";
CM_ SG_ 2566837758 Alt4Status "Alternator 4 operating status.
00 Alternator 4 not charging
01 Alternator 4 charging
10 error
11 not available";
CM_ SG_ 2566837758 Alt3Status "Alternator 3 operating status.
00 Alternator 3 not charging
01 Alternator 3 charging
10 error
11 not available";
CM_ SG_ 2566837758 Alt2Status "Alternator 2 operating status.
00 Alternator 2 not charging
01 Alternator 2 charging
10 error
11 not available";
CM_ SG_ 2566837758 Alt1Status "Alternator 1 operating status.
00 Alternator 1 not charging
01 Alternator 1 charging
10 error
11 not available";
CM_ SG_ 2566837758 AltSpeed "Actual rotation speed of the alternator.";
CM_ SG_ 2633922558 AuxAbsPressReading "Identifies the current absolute pressure (relative to 0 pressure) that is configured uniquely per application.  Not to be used in place of defined parameters.";
CM_ SG_ 2633922558 AuxGagePressReading1 "Identifies the current gage pressure (relative to atmosphere) that is configured uniquely per application.  Not to be used in place of defined parameters.";
CM_ SG_ 2633922558 AuxVacuumPressReading "Identifies the current vacuum pressure (relative to atmosphere) that is configured uniquely per application.  Not to be used in place of defined parameters.";
CM_ SG_ 2566775038 BarometricAbsPressHighResolution "Barometric Absolute Pressure (High Resolution).  See SPN 108 if high resolution is not needed.";
CM_ SG_ 2566775038 CalculatedAmbientAirTemp "Calculated temperature of air surrounding vehicle.  Use SPN 171 for actual measured ambient air temperature.";
CM_ SG_ 2566775038 SpecificHumidity "Specific humidity of the ambient intake air.";
CM_ SG_ 2566775038 SolarSensorMax "This is the maximum value which can be reported by the sensor for the solar intensity. (This is a configuration parameter)";
CM_ SG_ 2566775038 SolarIntensityPercent "This is the solar radiation (power density) falling on the vehicle in percent of the maximum sensor value (SPN 2611).  Currently this is in the infra-red spectrum.";
CM_ SG_ 2566836478 TestLimitMinimum "The test value must be greater than or equal to Test Limit Minimum in order for the test to pass.";
CM_ SG_ 2566836478 TestLimitMaximum "The test value must be less than or equal to Test Limit Maximum in order for the test to pass.";
CM_ SG_ 2566836478 TestValue "The test value collected during the test. If the test performed does not have both a test limit minimum and maximum, then the appropriate limit value (Maximum or Minimum) should be set to all ones. SAE J1939-71 defines this to mean not available.";
CM_ SG_ 2566836478 TestType "This parameter identifies the non-continuously monitored component identifier that was tested. These component identifiers are defined by the manufacturer. They are necessary when multiple components or systems are present on the vehicle and have ...";
CM_ SG_ 2566836478 TestIdentifier "The TID has 2 methods to designate the test to be run. The first method uses the TID alone and these test identifiers are manufacturer-defined test identifiers. For this first use there are 64 valid test identifiers, 1 to 64. The second method uses ...";
CM_ SG_ 2565078782 SPN1High "SPN #1 (Conversion Version 4)";
CM_ SG_ 2565078782 SPN1_4148 "This parameter identifies the component / system that will be tested.";
CM_ SG_ 2565078782 TestIdentifier_1224 "The TID has 2 methods to designate the test to be run. The first method uses the TID alone and these test identifiers are manufacturer-defined test identifiers. For this first use there are 64 valid test identifiers, 1 to 64. The second method uses ...";
CM_ SG_ 2565078782 FailureModeIdentifier1_4149 "This parameter identifies the failure mode identifier which represents the test(s) that shall be run on the component / system that will be tested.";
CM_ SG_ 2566836222 FlashRedStopLamp "This parameter provides the capability to flash the RSL
00 - Slow Flash (1 Hz, 50 % duty cycle)
01 - Fast Flash (2 Hz or faster, 50% duty cycle)
10 - Reserved
11 - Unavailable / Do Not Flash";
CM_ SG_ 2566836222 FlashProtectLamp "This parameter provides the capability to flash the engine protect lamp
00 - Slow Flash (1 Hz, 50 % duty cycle)
01 - Fast Flash (2 Hz or faster, 50% duty cycle)
10 - Reserved
11 - Unavailable / Do Not Flash";
CM_ SG_ 2566836222 FlashMalfuncIndicatorLamp "This parameter provides the capability to flash the MIL
00 - Slow Flash (1 Hz, 50 % duty cycle)
01 - Fast Flash (2 Hz or faster, 50% duty cycle)
10 - Class C DTC
11 - Unavailable / Do Not Flash
Note:  State 10 is for WWH OBD discriminatory ...";
CM_ SG_ 2566836222 FlashAmberWarningLamp "This parameter provides the capability to flash the AWL
00 - Slow Flash (1 Hz, 50 % duty cycle)
01 - Fast Flash (2 Hz or faster, 50% duty cycle)
10 - Reserved
11 - Unavailable / Do Not Flash";
CM_ SG_ 2566836222 MalfunctionIndicatorLampStatus "A lamp used to relay only emissions-related trouble code information. This lamp is only illuminated when there is an emission-related trouble code active.
00     Lamp Off
01     Lamp On
10     Short MIL for WWH OBD
11     Not available
Note ...";
CM_ SG_ 2566836222 RedStopLampState "This lamp is used to relay trouble code information that is of a severe enough condition that it warrants stopping the vehicle.
00     Lamp Off
01     Lamp On
10     Reserved
11     Not available";
CM_ SG_ 2566836222 AmberWarningLampStatus "This lamp is used to relay trouble code information that is reporting a problem with the vehicle system but the vehicle need not be immediately stopped.
00     Lamp Off
01     Lamp On
10     Reserved
11     Not available";
CM_ SG_ 2566836222 ProtectLampStatus "This lamp is used to relay trouble code information that is reporting a problem with a vehicle system that is most probably not electronic subsystem related. For instance, engine coolant temperature is exceeding its prescribed temperature range.
00 ...";
CM_ SG_ 2566836222 DTC5 "Diagnostic Trouble Code";
CM_ SG_ 2566836222 DTC4 "Diagnostic Trouble Code";
CM_ SG_ 2566836222 DTC3 "Diagnostic Trouble Code";
CM_ SG_ 2566836222 DTC2 "Diagnostic Trouble Code";
CM_ SG_ 2566836222 DTC1 "Diagnostic Trouble Code";
CM_ SG_ 2566835966 OBDCompliance "Identifies the OBD compliance capability of the responding controller. Identifies the requirements level to which the controller was built.";
CM_ SG_ 2566835966 PreviouslyActiveTroubleCodes "Identifies the number of previously active trouble codes that are present in a specific controller. If no DTCs have been previously active, this field should be set to zero.";
CM_ SG_ 2566835966 ActiveTroubleCodes "Identifies the number of active trouble codes that are present in a specific controller. If no DTCs are active, this field should be set to zero.";
CM_ SG_ 2566835710 EngIntakeManifold1Press "The gage pressure measurement of the air intake manifold. If there are multiple air pressure sensors in the intake stream, this is the last one in flow direction before entering the combustion chamber.  This should be the pressure used to drive ...";
CM_ SG_ 2566835710 FreezeFrameLength "The Freeze Frame Length shall be equal to the number of bytes in the required parameters plus the number of bytes in the manufacturer specific parameters.";
CM_ SG_ 2566835710 EngSpeed "Actual engine speed which is calculated over a minimum crankshaft angle of 720 degrees divided by the number of cylinders.";
CM_ SG_ 2566835710 EngTorqueMode "State signal which indicates which engine torque mode is currently generating, limiting, or controlling the torque.  Note that the modes are not in prioritized order. Not all modes may be relevant for a given device.  Some devices may not implement ...";
CM_ SG_ 2566835710 WheelBasedVehicleSpeed "Speed of the vehicle as calculated from wheel or tailshaft speed.";
CM_ SG_ 2566835710 EngPercentLoadAtCurrentSpeed "The ratio of actual engine percent torque (indicated) to maximum indicated torque available at the current engine speed, clipped to zero torque during engine braking.";
CM_ SG_ 2566835710 EngCoolantTemp "Temperature of liquid found in engine cooling system.";
CM_ SG_ 2566835710 DTC1 "Diagnostic Trouble Code";
CM_ SG_ 2566764542 ExpandedFreezeFrameLength "The Freeze Frame Length is the length plus the number of bytes to convey the data of all parameters (SPNs) in Freeze Frame.";
CM_ SG_ 2566764542 DTC1 "Diagnostic Trouble Code";
CM_ SG_ 2566764286 SPNSupported1High "This parameter defines the SPN(s) that is/are supported for the freeze frame and/or data stream information.";
CM_ SG_ 2566764286 SPNSupportTypeSTR3 "This parameter defines whether the applicable parameter (that is the SPN) is supported in the freeze frame, the data stream or both the freeze frame and data stream.";
CM_ SG_ 2566764286 SPNSupportTypeSTR2 "This parameter defines whether the applicable parameter (that is the SPN) is supported in the freeze frame, the data stream or both the freeze frame and data stream.";
CM_ SG_ 2566764286 SPNSupportTypeEFF3 "This parameter defines whether the applicable parameter (that is the SPN) is supported in the freeze frame, the data stream or both the freeze frame and data stream.";
CM_ SG_ 2566764286 SPNSupportTypeEFF2 "This parameter defines whether the applicable parameter (that is the SPN) is supported in the freeze frame, the data stream or both the freeze frame and data stream.";
CM_ SG_ 2566764286 SPNSupportTypeDS3 "This parameter defines whether the applicable parameter (that is the SPN) is supported in the freeze frame, the data stream or both the freeze frame and data stream.";
CM_ SG_ 2566764286 SPNSupportTypeDS2 "This parameter defines whether the applicable parameter (that is the SPN) is supported in the freeze frame, the data stream or both the freeze frame and data stream.";
CM_ SG_ 2566764286 SPNSupported3High "This parameter defines the SPN(s) that is/are supported for the freeze frame and/or data stream information.";
CM_ SG_ 2566764286 SPNSupported2High "This parameter defines the SPN(s) that is/are supported for the freeze frame and/or data stream information.";
CM_ SG_ 2566764286 SPNSupported3 "This parameter defines the SPN(s) that is/are supported for the freeze frame and/or data stream information.";
CM_ SG_ 2566764286 SPNSupported2 "This parameter defines the SPN(s) that is/are supported for the freeze frame and/or data stream information.";
CM_ SG_ 2566764286 SPNDataLength3 "The number of data bytes associated with the SPN in the Freeze Frame.";
CM_ SG_ 2566764286 SPNSupportTypeSTR1 "This parameter defines whether the applicable parameter (that is the SPN) is supported in the Scaled Test Results message, DM30.";
CM_ SG_ 2566764286 SPNSupportTypeDS1 "This parameter defines whether the applicable parameter (that is the SPN) is supported in the Data Stream messages.";
CM_ SG_ 2566764286 SPNSupportTypeEFF1 "This parameter defines whether the applicable parameter (that is the SPN) is supported in the expanded freeze frame message, DM25.";
CM_ SG_ 2566764286 SPNDataLength2 "The number of data bytes associated with the SPN in the Freeze Frame.";
CM_ SG_ 2566764286 SPNDataLength1 "The number of data bytes associated with the SPN in the Freeze Frame.
The SPN data length is required to ensure old and new OBD tool compatibility with vehicle OBD Systems.  For instance, if the vehicle supports a new SPN then the tool will know ...";
CM_ SG_ 2566764286 SPNSupported1 "This parameter defines the SPN(s) that is/are supported for the freeze frame and/or data stream information.";
CM_ SG_ 2566764030 FlashRedStopLamp "This parameter provides the capability to flash the RSL
00 - Slow Flash (1 Hz, 50 % duty cycle)
01 - Fast Flash (2 Hz or faster, 50% duty cycle)
10 - Reserved
11 - Unavailable / Do Not Flash";
CM_ SG_ 2566764030 FlashProtectLamp "This parameter provides the capability to flash the engine protect lamp
00 - Slow Flash (1 Hz, 50 % duty cycle)
01 - Fast Flash (2 Hz or faster, 50% duty cycle)
10 - Reserved
11 - Unavailable / Do Not Flash";
CM_ SG_ 2566764030 FlashMalfuncIndicatorLamp "This parameter provides the capability to flash the MIL
00 - Slow Flash (1 Hz, 50 % duty cycle)
01 - Fast Flash (2 Hz or faster, 50% duty cycle)
10 - Class C DTC
11 - Unavailable / Do Not Flash
Note:  State 10 is for WWH OBD discriminatory ...";
CM_ SG_ 2566764030 FlashAmberWarningLamp "This parameter provides the capability to flash the AWL
00 - Slow Flash (1 Hz, 50 % duty cycle)
01 - Fast Flash (2 Hz or faster, 50% duty cycle)
10 - Reserved
11 - Unavailable / Do Not Flash";
CM_ SG_ 2566764030 MalfunctionIndicatorLampStatus "A lamp used to relay only emissions-related trouble code information. This lamp is only illuminated when there is an emission-related trouble code active.
00     Lamp Off
01     Lamp On
10     Short MIL for WWH OBD
11     Not available
Note ...";
CM_ SG_ 2566764030 RedStopLampState "This lamp is used to relay trouble code information that is of a severe enough condition that it warrants stopping the vehicle.
00     Lamp Off
01     Lamp On
10     Reserved
11     Not available";
CM_ SG_ 2566764030 AmberWarningLampStatus "This lamp is used to relay trouble code information that is reporting a problem with the vehicle system but the vehicle need not be immediately stopped.
00     Lamp Off
01     Lamp On
10     Reserved
11     Not available";
CM_ SG_ 2566764030 ProtectLampStatus "This lamp is used to relay trouble code information that is reporting a problem with a vehicle system that is most probably not electronic subsystem related. For instance, engine coolant temperature is exceeding its prescribed temperature range.
00 ...";
CM_ SG_ 2566764030 DTC5 "Diagnostic Trouble Code";
CM_ SG_ 2566764030 DTC4 "Diagnostic Trouble Code";
CM_ SG_ 2566764030 DTC3 "Diagnostic Trouble Code";
CM_ SG_ 2566764030 DTC2 "Diagnostic Trouble Code";
CM_ SG_ 2566764030 DTC1 "Diagnostic Trouble Code";

BA_DEF_ BO_ "GenMsgCycleTime" INT 0 3600000;
BA_DEF_ BO_ "GenMsgCycleTimeFast" INT 0 3600000;
BA_DEF_ BO_ "GenMsgDelayTime" INT 0 1000;
BA_DEF_ BO_ "GenMsgILSupport" ENUM  "No","Yes";
BA_DEF_ BO_ "GenMsgRequestable" INT 0 1;
BA_DEF_ BO_ "GenMsgSendType" ENUM  "cyclic","spontaneous","cyclicIfActive","spontaneousWithDelay","cyclicAndSpontaneous","cyclicAndSpontaneousWithDelay","spontaneousWithRepetition","cyclicIfActiveAndSpontaneousWD";
BA_DEF_ BO_ "GenMsgStartDelayTime" INT 0 100000;
BA_DEF_ BO_ "J1939PGNameSecSrc0Dest3" STRING;
BA_DEF_ BO_ "J1939PGPrio" INT 0 7;
BA_DEF_ BO_ "J1939PGPrioSrc0Dest3" INT 0 7;
BA_DEF_ BO_ "J1939PGRelationDest3Src0" INT 0 254;
BA_DEF_ BO_ "J1939PGRelationSrc0Dest3" INT 0 254;
BA_DEF_ BO_ "J1939PGRepCycleSrc0Dest3" INT -1 65535;
BA_DEF_ BO_ "J1939PGRepTypeSrc0Dest3" INT 0 4;
BA_DEF_ BO_ "J1939PGRepetitionCycle" INT 0 65535;
BA_DEF_ BO_ "J1939PGRepetitionType" ENUM  "always","when active","on request";
BA_DEF_ BO_ "J1939PGtoECUSrc0Dest3" INT 0 254;
BA_DEF_ BO_ "J1939PGtoWSMSrc0Dest3" INT 0 254;
BA_DEF_ BO_ "TpJ1939VarDlc" ENUM  "No","Yes";
BA_DEF_ BO_ "VFrameFormat" ENUM  "StandardCAN","ExtendedCAN","reserved","J1939PG";
BA_DEF_ SG_ "GenSigEVName" STRING;
BA_DEF_ SG_ "GenSigILSupport" ENUM  "No","Yes";
BA_DEF_ SG_ "GenSigSendType" ENUM  "Cyclic","OnWrite","OnWriteWithRepetition","OnChange","OnChangeWithRepetition","IfActive","IfActiveWithRepetition","NoSigSendType";
BA_DEF_ SG_ "GenSigStartValue" INT 0 10000;
BA_DEF_ SG_ "SPN" INT 0 524287;
BA_DEF_ SG_ "SigType" ENUM  "Default","Range","RangeSigned","ASCII","Discrete","Control","ReferencePGN","DTC","StringDelimiter","StringLength","StringLengthControl","MessageCounter","MessageChecksum";
BA_DEF_ SG_ "SystemSignalLongSymbol" STRING;
BA_DEF_DEF_ "GenMsgCycleTime" 0;
BA_DEF_DEF_ "GenMsgCycleTimeFast" 0;
BA_DEF_DEF_ "GenMsgDelayTime" 0;
BA_DEF_DEF_ "GenMsgILSupport" "Yes";
BA_DEF_DEF_ "GenMsgRequestable" 1;
BA_DEF_DEF_ "GenMsgSendType" "noMsgSendType";
BA_DEF_DEF_ "GenMsgStartDelayTime" 0;
BA_DEF_DEF_ "GenSigEVName" "Env@Nodename_@Signame";
BA_DEF_DEF_ "GenSigILSupport" "Yes";
BA_DEF_DEF_ "GenSigSendType" "NoSigSendType";
BA_DEF_DEF_ "GenSigStartValue" 0;
BA_DEF_DEF_ "J1939PGNameSecSrc0Dest3" "(null)";
BA_DEF_DEF_ "J1939PGPrio" 6;
BA_DEF_DEF_ "J1939PGPrioSrc0Dest3" 6;
BA_DEF_DEF_ "J1939PGRelationDest3Src0" 254;
BA_DEF_DEF_ "J1939PGRelationSrc0Dest3" 254;
BA_DEF_DEF_ "J1939PGRepCycleSrc0Dest3" -1;
BA_DEF_DEF_ "J1939PGRepTypeSrc0Dest3" 3;
BA_DEF_DEF_ "J1939PGRepetitionCycle" 100;
BA_DEF_DEF_ "J1939PGRepetitionType" "always";
BA_DEF_DEF_ "J1939PGtoECUSrc0Dest3" -1;
BA_DEF_DEF_ "J1939PGtoWSMSrc0Dest3" -1;
BA_DEF_DEF_ "SPN" 0;
BA_DEF_DEF_ "SigType" "Default";
BA_DEF_DEF_ "SystemSignalLongSymbol" "";
BA_DEF_DEF_ "TpJ1939VarDlc" "No";
BA_DEF_DEF_ "VFrameFormat" "J1939PG";
BA_ "GenMsgCycleTime" BO_ 2432520958 1000;
BA_ "GenMsgSendType" BO_ 2432520958 0;
BA_ "GenMsgDelayTime" BO_ 2560425726 100;
BA_ "GenMsgDelayTime" BO_ 2560491262 100;
BA_ "GenMsgDelayTime" BO_ 2349399806 20;
BA_ "GenMsgCycleTime" BO_ 2566758398 500;
BA_ "GenMsgSendType" BO_ 2566758398 0;
BA_ "GenMsgCycleTime" BO_ 2566745598 500;
BA_ "GenMsgSendType" BO_ 2566745598 0;
BA_ "GenMsgCycleTime" BO_ 2566758910 500;
BA_ "GenMsgSendType" BO_ 2566758910 0;
BA_ "GenMsgCycleTime" BO_ 2566743550 500;
BA_ "GenMsgSendType" BO_ 2566743550 0;
BA_ "GenMsgCycleTime" BO_ 2566753534 500;
BA_ "GenMsgSendType" BO_ 2566753534 0;
BA_ "GenMsgCycleTime" BO_ 2565869310 50;
BA_ "GenMsgSendType" BO_ 2565869310 0;
BA_ "GenMsgCycleTime" BO_ 2566763774 500;
BA_ "GenMsgSendType" BO_ 2566763774 0;
BA_ "GenMsgCycleTime" BO_ 2633934846 1000;
BA_ "GenMsgSendType" BO_ 2633934846 0;
BA_ "GenMsgCycleTime" BO_ 2362572542 100;
BA_ "GenMsgSendType" BO_ 2362572542 7;
BA_ "GenMsgCycleTime" BO_ 2365478910 100;
BA_ "GenMsgSendType" BO_ 2365478910 0;
BA_ "TpJ1939VarDlc" BO_ 2560950014 1;
BA_ "GenMsgCycleTime" BO_ 2566763262 500;
BA_ "GenMsgSendType" BO_ 2566763262 0;
BA_ "GenMsgCycleTime" BO_ 2565869566 50;
BA_ "GenMsgSendType" BO_ 2565869566 0;
BA_ "GenMsgCycleTime" BO_ 2566763518 500;
BA_ "GenMsgSendType" BO_ 2566763518 0;
BA_ "GenMsgCycleTime" BO_ 2566758142 500;
BA_ "GenMsgSendType" BO_ 2566758142 0;
BA_ "GenMsgCycleTime" BO_ 2566745342 500;
BA_ "GenMsgSendType" BO_ 2566745342 0;
BA_ "GenMsgCycleTime" BO_ 2566758654 500;
BA_ "GenMsgSendType" BO_ 2566758654 0;
BA_ "GenMsgCycleTime" BO_ 2566753278 500;
BA_ "GenMsgSendType" BO_ 2566753278 0;
BA_ "GenMsgCycleTime" BO_ 2565869822 50;
BA_ "GenMsgSendType" BO_ 2565869822 0;
BA_ "GenMsgCycleTime" BO_ 2566763006 500;
BA_ "GenMsgSendType" BO_ 2566763006 0;
BA_ "GenMsgCycleTime" BO_ 2566762494 500;
BA_ "GenMsgSendType" BO_ 2566762494 0;
BA_ "GenMsgCycleTime" BO_ 2565870078 50;
BA_ "GenMsgSendType" BO_ 2565870078 0;
BA_ "GenMsgCycleTime" BO_ 2566762750 500;
BA_ "GenMsgSendType" BO_ 2566762750 0;
BA_ "GenMsgCycleTime" BO_ 2365428478 250;
BA_ "GenMsgSendType" BO_ 2365428478 0;
BA_ "GenMsgCycleTime" BO_ 2566743806 1000;
BA_ "GenMsgSendType" BO_ 2566743806 0;
BA_ "GenMsgCycleTime" BO_ 2550660862 100;
BA_ "GenMsgSendType" BO_ 2550660862 0;
BA_ "GenMsgCycleTime" BO_ 2566805758 100;
BA_ "GenMsgSendType" BO_ 2566805758 0;
BA_ "GenMsgCycleTime" BO_ 2566806014 100;
BA_ "GenMsgSendType" BO_ 2566806014 0;
BA_ "GenMsgCycleTime" BO_ 2362638078 100;
BA_ "GenMsgSendType" BO_ 2362638078 0;
BA_ "GenMsgCycleTime" BO_ 2365479678 100;
BA_ "GenMsgSendType" BO_ 2365479678 0;
BA_ "GenMsgCycleTime" BO_ 2566837758 1000;
BA_ "GenMsgSendType" BO_ 2566837758 0;
BA_ "GenMsgCycleTime" BO_ 2566775038 1000;
BA_ "GenMsgSendType" BO_ 2566775038 0;
BA_ "GenMsgSendType" BO_ 2566836478 8;
BA_ "TpJ1939VarDlc" BO_ 2566836478 1;
BA_ "GenMsgSendType" BO_ 2565078782 8;
BA_ "GenMsgSendType" BO_ 2566836222 8;
BA_ "TpJ1939VarDlc" BO_ 2566836222 1;
BA_ "GenMsgSendType" BO_ 2566835966 8;
BA_ "GenMsgSendType" BO_ 2566835710 8;
BA_ "TpJ1939VarDlc" BO_ 2566835710 1;
BA_ "GenMsgSendType" BO_ 2566835454 8;
BA_ "GenMsgSendType" BO_ 2566764542 8;
BA_ "TpJ1939VarDlc" BO_ 2566764542 1;
BA_ "GenMsgSendType" BO_ 2566764286 8;
BA_ "TpJ1939VarDlc" BO_ 2566764286 1;
BA_ "GenMsgSendType" BO_ 2566764030 8;
BA_ "TpJ1939VarDlc" BO_ 2566764030 1;
BA_ "SPN" SG_ 2566736382 EngExhstGsOxygnSnsrClsdLpOprtnBn 4240;
BA_ "SPN" SG_ 2566736382 ShorttermFuelTrimBank1 4236;
BA_ "SigType" SG_ 2566736382 ShorttermFuelTrimBank1 1;
BA_ "SPN" SG_ 2566736382 LongtermFuelTrimBank1 4237;
BA_ "SigType" SG_ 2566736382 LongtermFuelTrimBank1 1;
BA_ "SPN" SG_ 2565874174 EngSpdSensor1TimingPatternStatus 4203;
BA_ "SigType" SG_ 2565874174 EngSpdSensor1TimingPatternStatus 5;
BA_ "SPN" SG_ 2565874174 EngSpdSensor2TimingPatternStatus 4204;
BA_ "SigType" SG_ 2565874174 EngSpdSensor2TimingPatternStatus 5;
BA_ "SPN" SG_ 2565874174 EngSpdSensor3TimingPatternStatus 4205;
BA_ "SigType" SG_ 2565874174 EngSpdSensor3TimingPatternStatus 5;
BA_ "SPN" SG_ 2565874174 EngSpeed3 4202;
BA_ "SigType" SG_ 2565874174 EngSpeed3 1;
BA_ "SPN" SG_ 2565874174 EngSpeed2 723;
BA_ "SigType" SG_ 2565874174 EngSpeed2 1;
BA_ "SPN" SG_ 2565874174 EngSpeed1 4201;
BA_ "SigType" SG_ 2565874174 EngSpeed1 1;
BA_ "SPN" SG_ 2432520958 EngAxClerSupplyValve2ActuatorCmd 5547;
BA_ "SigType" SG_ 2432520958 EngAxClerSupplyValve2ActuatorCmd 1;
BA_ "SPN" SG_ 2432520958 EngAxClerSupplyValve1ActuatorCmd 5546;
BA_ "SigType" SG_ 2432520958 EngAxClerSupplyValve1ActuatorCmd 1;
BA_ "SPN" SG_ 2432520958 DsredEngCoolantThermostatOpening 4197;
BA_ "SigType" SG_ 2432520958 DsredEngCoolantThermostatOpening 1;
BA_ "SPN" SG_ 2432520958 DesiredEngCoolantPumpOutletTemp 4196;
BA_ "SigType" SG_ 2432520958 DesiredEngCoolantPumpOutletTemp 1;
BA_ "SPN" SG_ 2432520958 EngCoolantThermostatMode 4195;
BA_ "SigType" SG_ 2432520958 EngCoolantThermostatMode 5;
BA_ "SPN" SG_ 2560425726 AuxI_OChannel19_4174 4174;
BA_ "SigType" SG_ 2560425726 AuxI_OChannel19_4174 1;
BA_ "SPN" SG_ 2560425726 AuxI_OChannel20_4173 4173;
BA_ "SigType" SG_ 2560425726 AuxI_OChannel20_4173 1;
BA_ "SPN" SG_ 2560425726 AuxI_OChannel21_4172 4172;
BA_ "SigType" SG_ 2560425726 AuxI_OChannel21_4172 1;
BA_ "SPN" SG_ 2560425726 AuxI_OChannel22_4171 4171;
BA_ "SigType" SG_ 2560425726 AuxI_OChannel22_4171 1;
BA_ "SPN" SG_ 2560425726 AuxI_OChannel15_4170 4170;
BA_ "SigType" SG_ 2560425726 AuxI_OChannel15_4170 1;
BA_ "SPN" SG_ 2560425726 AuxI_OChannel16_4169 4169;
BA_ "SigType" SG_ 2560425726 AuxI_OChannel16_4169 1;
BA_ "SPN" SG_ 2560425726 AuxI_OChannel17_4168 4168;
BA_ "SigType" SG_ 2560425726 AuxI_OChannel17_4168 1;
BA_ "SPN" SG_ 2560425726 AuxI_OChannel18_4167 4167;
BA_ "SigType" SG_ 2560425726 AuxI_OChannel18_4167 1;
BA_ "SPN" SG_ 2560491262 AuxI_OChannel11_4166 4166;
BA_ "SigType" SG_ 2560491262 AuxI_OChannel11_4166 1;
BA_ "SPN" SG_ 2560491262 AuxI_OChannel12_4165 4165;
BA_ "SigType" SG_ 2560491262 AuxI_OChannel12_4165 1;
BA_ "SPN" SG_ 2560491262 AuxI_OChannel13_4164 4164;
BA_ "SigType" SG_ 2560491262 AuxI_OChannel13_4164 1;
BA_ "SPN" SG_ 2560491262 AuxI_OChannel14_4163 4163;
BA_ "SigType" SG_ 2560491262 AuxI_OChannel14_4163 1;
BA_ "SPN" SG_ 2560491262 AuxI_OChannel7_4162 4162;
BA_ "SigType" SG_ 2560491262 AuxI_OChannel7_4162 1;
BA_ "SPN" SG_ 2560491262 AuxI_OChannel8_4161 4161;
BA_ "SigType" SG_ 2560491262 AuxI_OChannel8_4161 1;
BA_ "SPN" SG_ 2560491262 AuxI_OChannel9_4160 4160;
BA_ "SigType" SG_ 2560491262 AuxI_OChannel9_4160 1;
BA_ "SPN" SG_ 2560491262 AuxI_OChannel10_4159 4159;
BA_ "SigType" SG_ 2560491262 AuxI_OChannel10_4159 1;
BA_ "SPN" SG_ 2349399806 AuxI_OChannel3_4158 4158;
BA_ "SigType" SG_ 2349399806 AuxI_OChannel3_4158 1;
BA_ "SPN" SG_ 2349399806 AuxI_OChannel4_4157 4157;
BA_ "SigType" SG_ 2349399806 AuxI_OChannel4_4157 1;
BA_ "SPN" SG_ 2349399806 AuxI_OChannel5_4156 4156;
BA_ "SigType" SG_ 2349399806 AuxI_OChannel5_4156 1;
BA_ "SPN" SG_ 2349399806 AuxI_OChannel6_4155 4155;
BA_ "SigType" SG_ 2349399806 AuxI_OChannel6_4155 1;
BA_ "SPN" SG_ 2566758398 EnableAct 3489;
BA_ "SigType" SG_ 2566758398 EnableAct 5;
BA_ "SPN" SG_ 2566758398 PurgeAirAct 3490;
BA_ "SigType" SG_ 2566758398 PurgeAirAct 5;
BA_ "SPN" SG_ 2566758398 AtomizationAirAct 3491;
BA_ "SigType" SG_ 2566758398 AtomizationAirAct 5;
BA_ "SPN" SG_ 2566758398 SysRelay 3492;
BA_ "SigType" SG_ 2566758398 SysRelay 5;
BA_ "SPN" SG_ 2566758398 PressActPos 3488;
BA_ "SigType" SG_ 2566758398 PressActPos 1;
BA_ "SPN" SG_ 2566758398 PressCtrl 3487;
BA_ "SigType" SG_ 2566758398 PressCtrl 1;
BA_ "SPN" SG_ 2566758398 PurgeAirPress 3486;
BA_ "SigType" SG_ 2566758398 PurgeAirPress 1;
BA_ "SPN" SG_ 2566758398 SupplyAirPress 3485;
BA_ "SigType" SG_ 2566758398 SupplyAirPress 1;
BA_ "SPN" SG_ 2566745598 SecondAirPress 3837;
BA_ "SigType" SG_ 2566745598 SecondAirPress 1;
BA_ "SPN" SG_ 2566745598 SecondAirMFR 3832;
BA_ "SigType" SG_ 2566745598 SecondAirMFR 1;
BA_ "SPN" SG_ 2566745598 SecondAirTemp 3831;
BA_ "SigType" SG_ 2566745598 SecondAirTemp 1;
BA_ "SPN" SG_ 2566745598 SecondAirDiffPress 3830;
BA_ "SigType" SG_ 2566745598 SecondAirDiffPress 1;
BA_ "SPN" SG_ 2566758910 Injector1HtrCtrl 4301;
BA_ "SigType" SG_ 2566758910 Injector1HtrCtrl 1;
BA_ "SPN" SG_ 2566758910 EnableAct 3482;
BA_ "SigType" SG_ 2566758910 EnableAct 5;
BA_ "SPN" SG_ 2566758910 RegenStatus 3483;
BA_ "SigType" SG_ 2566758910 RegenStatus 5;
BA_ "SPN" SG_ 2566758910 Ignt 3484;
BA_ "SigType" SG_ 2566758910 Ignt 5;
BA_ "SPN" SG_ 2566758910 DrainAct 4097;
BA_ "SigType" SG_ 2566758910 DrainAct 5;
BA_ "SPN" SG_ 2566758910 Press1Ctrl 3479;
BA_ "SigType" SG_ 2566758910 Press1Ctrl 1;
BA_ "SPN" SG_ 2566758910 Rate 3481;
BA_ "SigType" SG_ 2566758910 Rate 1;
BA_ "SPN" SG_ 2566758910 Press1 3480;
BA_ "SigType" SG_ 2566758910 Press1 1;
BA_ "SPN" SG_ 2566743550 HydrocarbonDoserInFuelTemp 5456;
BA_ "SigType" SG_ 2566743550 HydrocarbonDoserInFuelTemp 1;
BA_ "SPN" SG_ 2566743550 Press2ActCtrl 5425;
BA_ "SigType" SG_ 2566743550 Press2ActCtrl 1;
BA_ "SPN" SG_ 2566743550 FlowDiverterVlvCtrl 5424;
BA_ "SigType" SG_ 2566743550 FlowDiverterVlvCtrl 5;
BA_ "SPN" SG_ 2566743550 PumpRelayCtrl 5423;
BA_ "SigType" SG_ 2566743550 PumpRelayCtrl 5;
BA_ "SPN" SG_ 2566743550 Press2 4077;
BA_ "SigType" SG_ 2566743550 Press2 1;
BA_ "SPN" SG_ 2566753534 DPFOutPress 3610;
BA_ "SigType" SG_ 2566753534 DPFOutPress 1;
BA_ "SPN" SG_ 2566753534 DPFInPress 3609;
BA_ "SigType" SG_ 2566753534 DPFInPress 1;
BA_ "SPN" SG_ 2566756606 DPFAvgDistBetweenActiveRegens 5827;
BA_ "SigType" SG_ 2566756606 DPFAvgDistBetweenActiveRegens 1;
BA_ "SPN" SG_ 2566756606 DPFAvgTimeBetweenActiveRegens 5454;
BA_ "SigType" SG_ 2566756606 DPFAvgTimeBetweenActiveRegens 1;
BA_ "SPN" SG_ 2566756606 DPFTotalNumOfActiveRegenManReq 3728;
BA_ "SigType" SG_ 2566756606 DPFTotalNumOfActiveRegenManReq 1;
BA_ "SPN" SG_ 2566756606 DPFTotalNumOfActiveRegenInhReq 3727;
BA_ "SigType" SG_ 2566756606 DPFTotalNumOfActiveRegenInhReq 1;
BA_ "SPN" SG_ 2566756606 DPFTotalNumOfPassiveRegens 3726;
BA_ "SigType" SG_ 2566756606 DPFTotalNumOfPassiveRegens 1;
BA_ "SPN" SG_ 2566756606 DPFTotalPassiveRegenTime 3725;
BA_ "SigType" SG_ 2566756606 DPFTotalPassiveRegenTime 1;
BA_ "SPN" SG_ 2566756606 TotalNumOfActiveRegens 3525;
BA_ "SigType" SG_ 2566756606 TotalNumOfActiveRegens 1;
BA_ "SPN" SG_ 2566756606 TotalDisdTime 3524;
BA_ "SigType" SG_ 2566756606 TotalDisdTime 1;
BA_ "SPN" SG_ 2566756606 TotalRegenTime 3523;
BA_ "SigType" SG_ 2566756606 TotalRegenTime 1;
BA_ "SPN" SG_ 2566756606 TotalFuelUsed 3522;
BA_ "SigType" SG_ 2566756606 TotalFuelUsed 1;
BA_ "SPN" SG_ 2565869310 IntkNOxSnsr1SelfDiagStatus_5714 5714;
BA_ "SPN" SG_ 2565869310 IntkO2Snsr1PrelFMI_3225 3225;
BA_ "SPN" SG_ 2565869310 SCRIntkNOxSnsr1PrelFMI_3224 3224;
BA_ "SPN" SG_ 2565869310 IntkGasSnsr1HeatrCtl_3223 3223;
BA_ "SigType" SG_ 2565869310 IntkGasSnsr1HeatrCtl_3223 5;
BA_ "SPN" SG_ 2565869310 IntkGasSnsr1HeatrPrelFMI_3222 3222;
BA_ "SPN" SG_ 2565869310 IWRPO1ReadingStab_3221 3221;
BA_ "SigType" SG_ 2565869310 IWRPO1ReadingStab_3221 5;
BA_ "SPN" SG_ 2565869310 SCRIntkNOx1ReadingStab_3220 3220;
BA_ "SigType" SG_ 2565869310 SCRIntkNOx1ReadingStab_3220 5;
BA_ "SPN" SG_ 2565869310 IntkGasSnsr1AtTemp_3219 3219;
BA_ "SigType" SG_ 2565869310 IntkGasSnsr1AtTemp_3219 5;
BA_ "SPN" SG_ 2565869310 IntkGasSnsr1PwrInRng_3218 3218;
BA_ "SigType" SG_ 2565869310 IntkGasSnsr1PwrInRng_3218 5;
BA_ "SPN" SG_ 2565869310 Aftertreatment1IntkPercO2_3217 3217;
BA_ "SigType" SG_ 2565869310 Aftertreatment1IntkPercO2_3217 1;
BA_ "SPN" SG_ 2565869310 Aftertreatment1SCRIntkNOx1_3216 3216;
BA_ "SigType" SG_ 2565869310 Aftertreatment1SCRIntkNOx1_3216 1;
BA_ "SPN" SG_ 2566763774 DPFInTempPreliminaryFMI 3244;
BA_ "SPN" SG_ 2566763774 ExhTemp1PreliminaryFMI 3243;
BA_ "SPN" SG_ 2566763774 DPFInTemp 3242;
BA_ "SigType" SG_ 2566763774 DPFInTemp 1;
BA_ "SPN" SG_ 2566763774 ExhTemp1 3241;
BA_ "SigType" SG_ 2566763774 ExhTemp1 1;
BA_ "SPN" SG_ 2631728894 AntitheftRandomNumber_1198 1198;
BA_ "SPN" SG_ 2631728894 AntitheftModifyPwdStates_1197 1197;
BA_ "SigType" SG_ 2631728894 AntitheftModifyPwdStates_1197 5;
BA_ "SPN" SG_ 2631728894 AntiThftCptStatusStates_1196 1196;
BA_ "SigType" SG_ 2631728894 AntiThftCptStatusStates_1196 5;
BA_ "SPN" SG_ 2631728894 AntitheftPwdValidIndicator_1195 1195;
BA_ "SigType" SG_ 2631728894 AntitheftPwdValidIndicator_1195 5;
BA_ "SPN" SG_ 2631728894 AntiThftEncrpSeedPrestIndcr_1194 1194;
BA_ "SigType" SG_ 2631728894 AntiThftEncrpSeedPrestIndcr_1194 5;
BA_ "SPN" SG_ 2631794430 AntiThftPwdRepresentation_1202 1202;
BA_ "SPN" SG_ 2631794430 AntiTheftCmdStates_1201 1201;
BA_ "SPN" SG_ 2631794430 AntiThftDesExitModeStates_1200 1200;
BA_ "SigType" SG_ 2631794430 AntiThftDesExitModeStates_1200 5;
BA_ "SPN" SG_ 2631794430 AntiThftEncrpnIndcrStates_1199 1199;
BA_ "SigType" SG_ 2631794430 AntiThftEncrpnIndcrStates_1199 5;
BA_ "SPN" SG_ 2633934846 EngAltWinding3Temp 1126;
BA_ "SigType" SG_ 2633934846 EngAltWinding3Temp 1;
BA_ "SPN" SG_ 2633934846 EngAltWinding2Temp 1125;
BA_ "SigType" SG_ 2633934846 EngAltWinding2Temp 1;
BA_ "SPN" SG_ 2633934846 EngAltWinding1Temp 1124;
BA_ "SigType" SG_ 2633934846 EngAltWinding1Temp 1;
BA_ "SPN" SG_ 2633934846 EngAltBearing2Temp 1123;
BA_ "SigType" SG_ 2633934846 EngAltBearing2Temp 1;
BA_ "SPN" SG_ 2633934846 EngAltBearing1Temp 1122;
BA_ "SigType" SG_ 2633934846 EngAltBearing1Temp 1;
BA_ "SPN" SG_ 2362572542 LevelPresetRearAxleRight_1735 1735;
BA_ "SigType" SG_ 2362572542 LevelPresetRearAxleRight_1735 1;
BA_ "SPN" SG_ 2362572542 LevelPresetRearAxleLeft_1758 1758;
BA_ "SigType" SG_ 2362572542 LevelPresetRearAxleLeft_1758 1;
BA_ "SPN" SG_ 2362572542 LevelPresetFrontAxleRight_1757 1757;
BA_ "SigType" SG_ 2362572542 LevelPresetFrontAxleRight_1757 1;
BA_ "SPN" SG_ 2362572542 LevelPresetFrontAxleLeft_1732 1732;
BA_ "SigType" SG_ 2362572542 LevelPresetFrontAxleLeft_1732 1;
BA_ "SPN" SG_ 2365478910 ElctrncShckAbsrbrCtrlMdLft_TgAxl 1831;
BA_ "SigType" SG_ 2365478910 ElctrncShckAbsrbrCtrlMdLft_TgAxl 4;
BA_ "SPN" SG_ 2365478910 ElctrncShckAbsrbrCtrlMdeRearAxle 1832;
BA_ "SigType" SG_ 2365478910 ElctrncShckAbsrbrCtrlMdeRearAxle 4;
BA_ "SPN" SG_ 2365478910 ElctrncShckAbsrbrCtrlMdFrontAxle 1833;
BA_ "SigType" SG_ 2365478910 ElctrncShckAbsrbrCtrlMdFrontAxle 4;
BA_ "SPN" SG_ 2365478910 DamperStiffnessLift_TagAxle 1731;
BA_ "SigType" SG_ 2365478910 DamperStiffnessLift_TagAxle 1;
BA_ "SPN" SG_ 2365478910 DamperStiffnessRearAxle 1730;
BA_ "SigType" SG_ 2365478910 DamperStiffnessRearAxle 1;
BA_ "SPN" SG_ 2365478910 DamperStiffnessFrontAxle 1729;
BA_ "SigType" SG_ 2365478910 DamperStiffnessFrontAxle 1;
BA_ "SPN" SG_ 2560950014 SPN1_1214 1214;
BA_ "SPN" SG_ 2560950014 TestLimitMinimum_4112 4112;
BA_ "SigType" SG_ 2560950014 TestLimitMinimum_4112 1;
BA_ "SPN" SG_ 2560950014 FailureModeIdentifier1_1215 1215;
BA_ "SPN" SG_ 2560950014 TestLimitMaximum_4111 4111;
BA_ "SigType" SG_ 2560950014 TestLimitMaximum_4111 1;
BA_ "SPN" SG_ 2560950014 TestValue_4110 4110;
BA_ "SigType" SG_ 2560950014 TestValue_4110 1;
BA_ "SPN" SG_ 2560950014 SlotId_4109 4109;
BA_ "SigType" SG_ 2560950014 SlotId_4109 1;
BA_ "SPN" SG_ 2566763262 DPFIntmdTempPreliminaryFMI 3254;
BA_ "SPN" SG_ 2566763262 DPFDiffPressPreliminaryFMI 3253;
BA_ "SPN" SG_ 2566763262 ExhTemp2PreliminaryFMI 3252;
BA_ "SPN" SG_ 2566763262 DPFDiffPress 3251;
BA_ "SigType" SG_ 2566763262 DPFDiffPress 1;
BA_ "SPN" SG_ 2566763262 DPFIntmdTemp 3250;
BA_ "SigType" SG_ 2566763262 DPFIntmdTemp 1;
BA_ "SPN" SG_ 2566763262 ExhTemp2 3249;
BA_ "SigType" SG_ 2566763262 ExhTemp2 1;
BA_ "SPN" SG_ 2565869566 OutletOxyzenSnsr1PrelFMI_3235 3235;
BA_ "SPN" SG_ 2565869566 OutletNOxSnsr1SelfDiagSts_5713 5713;
BA_ "SPN" SG_ 2565869566 OutletNOxSnsr1PrelFMI_3234 3234;
BA_ "SPN" SG_ 2565869566 OutletGasSnsr1HeatrCtrl_3233 3233;
BA_ "SigType" SG_ 2565869566 OutletGasSnsr1HeatrCtrl_3233 5;
BA_ "SPN" SG_ 2565869566 OutletGasSnsr1HeatrPrelFMI_3232 3232;
BA_ "SPN" SG_ 2565869566 OutletWideRngPercOxyzen1_3231 3231;
BA_ "SigType" SG_ 2565869566 OutletWideRngPercOxyzen1_3231 5;
BA_ "SPN" SG_ 2565869566 OutletNOx1ReadingStable_3230 3230;
BA_ "SigType" SG_ 2565869566 OutletNOx1ReadingStable_3230 5;
BA_ "SPN" SG_ 2565869566 OutletGasSnsr1AtTemp_3229 3229;
BA_ "SigType" SG_ 2565869566 OutletGasSnsr1AtTemp_3229 5;
BA_ "SPN" SG_ 2565869566 OutletGasSnsr1PwrInRng_3228 3228;
BA_ "SigType" SG_ 2565869566 OutletGasSnsr1PwrInRng_3228 5;
BA_ "SPN" SG_ 2565869566 OutletPercentOxyzen1_3227 3227;
BA_ "SigType" SG_ 2565869566 OutletPercentOxyzen1_3227 1;
BA_ "SPN" SG_ 2565869566 OutletNOx1_3226 3226;
BA_ "SigType" SG_ 2565869566 OutletNOx1_3226 1;
BA_ "SPN" SG_ 2566763518 DPFOutExhTempPreliminaryFMI 3248;
BA_ "SPN" SG_ 2566763518 ExhTemp3PreliminaryFMI 3247;
BA_ "SPN" SG_ 2566763518 DPFOutTemp 3246;
BA_ "SigType" SG_ 2566763518 DPFOutTemp 1;
BA_ "SPN" SG_ 2566763518 ExhTemp3 3245;
BA_ "SigType" SG_ 2566763518 ExhTemp3 1;
BA_ "SPN" SG_ 2566749182 DPFSootLoadRegenThreshold 5466;
BA_ "SigType" SG_ 2566749182 DPFSootLoadRegenThreshold 1;
BA_ "SPN" SG_ 2566749182 DPFTimeSinceLastActiveRegen 3721;
BA_ "SigType" SG_ 2566749182 DPFTimeSinceLastActiveRegen 1;
BA_ "SPN" SG_ 2566749182 DPFAshLoadPercent 3720;
BA_ "SigType" SG_ 2566749182 DPFAshLoadPercent 1;
BA_ "SPN" SG_ 2566749182 DPFSootLoadPercent 3719;
BA_ "SigType" SG_ 2566749182 DPFSootLoadPercent 1;
BA_ "SPN" SG_ 2566748670 DPFTripNumOfActiveRegenManReq 3740;
BA_ "SigType" SG_ 2566748670 DPFTripNumOfActiveRegenManReq 1;
BA_ "SPN" SG_ 2566748670 DPFTripNumOfActiveRegenInhReq 3739;
BA_ "SigType" SG_ 2566748670 DPFTripNumOfActiveRegenInhReq 1;
BA_ "SPN" SG_ 2566748670 DPFTripNumOfPassiveRegens 3738;
BA_ "SigType" SG_ 2566748670 DPFTripNumOfPassiveRegens 1;
BA_ "SPN" SG_ 2566748670 DPFTripPassiveRegenTime 3737;
BA_ "SigType" SG_ 2566748670 DPFTripPassiveRegenTime 1;
BA_ "SPN" SG_ 2566748670 DPFTripNumOfActiveRegens 3736;
BA_ "SigType" SG_ 2566748670 DPFTripNumOfActiveRegens 1;
BA_ "SPN" SG_ 2566748670 DPFTripDisdTime 3735;
BA_ "SigType" SG_ 2566748670 DPFTripDisdTime 1;
BA_ "SPN" SG_ 2566748670 DPFTripActiveRegenTime 3734;
BA_ "SigType" SG_ 2566748670 DPFTripActiveRegenTime 1;
BA_ "SPN" SG_ 2566748670 DPFTripFuelUsed 3733;
BA_ "SigType" SG_ 2566748670 DPFTripFuelUsed 1;
BA_ "SPN" SG_ 2566758142 EnableAct 3503;
BA_ "SigType" SG_ 2566758142 EnableAct 5;
BA_ "SPN" SG_ 2566758142 PurgeAirAct 3504;
BA_ "SigType" SG_ 2566758142 PurgeAirAct 5;
BA_ "SPN" SG_ 2566758142 AtomizationAirAct 3505;
BA_ "SigType" SG_ 2566758142 AtomizationAirAct 5;
BA_ "SPN" SG_ 2566758142 SysRelay 3506;
BA_ "SigType" SG_ 2566758142 SysRelay 5;
BA_ "SPN" SG_ 2566758142 PressActPos 3502;
BA_ "SigType" SG_ 2566758142 PressActPos 1;
BA_ "SPN" SG_ 2566758142 PressCtrl 3501;
BA_ "SigType" SG_ 2566758142 PressCtrl 1;
BA_ "SPN" SG_ 2566758142 PurgeAirPress 3500;
BA_ "SigType" SG_ 2566758142 PurgeAirPress 1;
BA_ "SPN" SG_ 2566758142 SupplyAirPress 3499;
BA_ "SigType" SG_ 2566758142 SupplyAirPress 1;
BA_ "SPN" SG_ 2566745342 SecondAirPress 3838;
BA_ "SigType" SG_ 2566745342 SecondAirPress 1;
BA_ "SPN" SG_ 2566745342 SecondAirMFR 3835;
BA_ "SigType" SG_ 2566745342 SecondAirMFR 1;
BA_ "SPN" SG_ 2566745342 SecondAirTemp 3834;
BA_ "SigType" SG_ 2566745342 SecondAirTemp 1;
BA_ "SPN" SG_ 2566745342 SecondAirDiffPress 3833;
BA_ "SigType" SG_ 2566745342 SecondAirDiffPress 1;
BA_ "SPN" SG_ 2566758654 Injector1HtrCtrl 4302;
BA_ "SigType" SG_ 2566758654 Injector1HtrCtrl 1;
BA_ "SPN" SG_ 2566758654 EnableAct 3496;
BA_ "SigType" SG_ 2566758654 EnableAct 5;
BA_ "SPN" SG_ 2566758654 RegenStatus 3497;
BA_ "SigType" SG_ 2566758654 RegenStatus 5;
BA_ "SPN" SG_ 2566758654 Ignt 3498;
BA_ "SigType" SG_ 2566758654 Ignt 5;
BA_ "SPN" SG_ 2566758654 DrainAct 4098;
BA_ "SigType" SG_ 2566758654 DrainAct 5;
BA_ "SPN" SG_ 2566758654 Press1Ctrl 3493;
BA_ "SigType" SG_ 2566758654 Press1Ctrl 1;
BA_ "SPN" SG_ 2566758654 Rate 3495;
BA_ "SigType" SG_ 2566758654 Rate 1;
BA_ "SPN" SG_ 2566758654 Press1 3494;
BA_ "SigType" SG_ 2566758654 Press1 1;
BA_ "SPN" SG_ 2566753278 DPFOutPress 3612;
BA_ "SigType" SG_ 2566753278 DPFOutPress 1;
BA_ "SPN" SG_ 2566753278 DPFInPress 3611;
BA_ "SigType" SG_ 2566753278 DPFInPress 1;
BA_ "SPN" SG_ 2566756862 DPFAvgDistBetweenActiveRegens 5828;
BA_ "SigType" SG_ 2566756862 DPFAvgDistBetweenActiveRegens 1;
BA_ "SPN" SG_ 2566756862 DPFAvgTimeBetweenActiveRegens 5455;
BA_ "SigType" SG_ 2566756862 DPFAvgTimeBetweenActiveRegens 1;
BA_ "SPN" SG_ 2566756862 DPFTotalNumOfActiveRegenManReq 3732;
BA_ "SigType" SG_ 2566756862 DPFTotalNumOfActiveRegenManReq 1;
BA_ "SPN" SG_ 2566756862 DPFTotalNumOfActiveRegenInhReq 3731;
BA_ "SigType" SG_ 2566756862 DPFTotalNumOfActiveRegenInhReq 1;
BA_ "SPN" SG_ 2566756862 DPFTotalNumOfPassiveRegens 3730;
BA_ "SigType" SG_ 2566756862 DPFTotalNumOfPassiveRegens 1;
BA_ "SPN" SG_ 2566756862 DPFTotalPassiveRegenTime 3729;
BA_ "SigType" SG_ 2566756862 DPFTotalPassiveRegenTime 1;
BA_ "SPN" SG_ 2566756862 TotalNumOfActiveRegens 3529;
BA_ "SigType" SG_ 2566756862 TotalNumOfActiveRegens 1;
BA_ "SPN" SG_ 2566756862 TotalDisdTime 3528;
BA_ "SigType" SG_ 2566756862 TotalDisdTime 1;
BA_ "SPN" SG_ 2566756862 TotalRegenTime 3527;
BA_ "SigType" SG_ 2566756862 TotalRegenTime 1;
BA_ "SPN" SG_ 2566756862 TotalFuelUsed 3526;
BA_ "SigType" SG_ 2566756862 TotalFuelUsed 1;
BA_ "SPN" SG_ 2565869822 IntkNOxSnsr1SelfDiagStatus_5716 5716;
BA_ "SPN" SG_ 2565869822 IntkOxyzenSnsr1PrelFMI_3264 3264;
BA_ "SPN" SG_ 2565869822 SCRIntkNOxSnsr1PrelFMI_3263 3263;
BA_ "SPN" SG_ 2565869822 IntkGasSnsr1HeatrCtl_3262 3262;
BA_ "SigType" SG_ 2565869822 IntkGasSnsr1HeatrCtl_3262 5;
BA_ "SPN" SG_ 2565869822 IntkGasSnsr1HeatrPrelFMI_3261 3261;
BA_ "SPN" SG_ 2565869822 IntkWideRngPercOxyzen1_3260 3260;
BA_ "SigType" SG_ 2565869822 IntkWideRngPercOxyzen1_3260 5;
BA_ "SPN" SG_ 2565869822 SCRIntkNOx1ReadingStable_3259 3259;
BA_ "SigType" SG_ 2565869822 SCRIntkNOx1ReadingStable_3259 5;
BA_ "SPN" SG_ 2565869822 IntkGasSnsr1AtTemp_3258 3258;
BA_ "SigType" SG_ 2565869822 IntkGasSnsr1AtTemp_3258 5;
BA_ "SPN" SG_ 2565869822 IntkGasSnsr1PwrInRange_3257 3257;
BA_ "SigType" SG_ 2565869822 IntkGasSnsr1PwrInRange_3257 5;
BA_ "SPN" SG_ 2565869822 IntkPercOxyzen1_3256 3256;
BA_ "SigType" SG_ 2565869822 IntkPercOxyzen1_3256 1;
BA_ "SPN" SG_ 2565869822 SCRIntkNOx1_3255 3255;
BA_ "SigType" SG_ 2565869822 SCRIntkNOx1_3255 1;
BA_ "SPN" SG_ 2566763006 DPFInTempPreliminaryFMI 3278;
BA_ "SPN" SG_ 2566763006 ExhTemp1PreliminaryFMI 3277;
BA_ "SPN" SG_ 2566763006 DPFInTemp 3276;
BA_ "SigType" SG_ 2566763006 DPFInTemp 1;
BA_ "SPN" SG_ 2566763006 ExhTemp1 3275;
BA_ "SigType" SG_ 2566763006 ExhTemp1 1;
BA_ "SPN" SG_ 2566762494 DPFIntmdTempPreliminaryFMI 3288;
BA_ "SPN" SG_ 2566762494 DPFDiffPressPreliminaryFMI 3287;
BA_ "SPN" SG_ 2566762494 ExhTemp2PreliminaryFMI 3286;
BA_ "SPN" SG_ 2566762494 DPFDiffPress 3285;
BA_ "SigType" SG_ 2566762494 DPFDiffPress 1;
BA_ "SPN" SG_ 2566762494 DPFIntmdTemp 3284;
BA_ "SigType" SG_ 2566762494 DPFIntmdTemp 1;
BA_ "SPN" SG_ 2566762494 ExhTemp2 3283;
BA_ "SigType" SG_ 2566762494 ExhTemp2 1;
BA_ "SPN" SG_ 2565870078 OutletOxyzenSnsr1PrelFMI_3274 3274;
BA_ "SPN" SG_ 2565870078 OutletNOxSnsr1PrelFMI_3273 3273;
BA_ "SPN" SG_ 2565870078 OutletGasSnsr1HtrCtl_3272 3272;
BA_ "SigType" SG_ 2565870078 OutletGasSnsr1HtrCtl_3272 5;
BA_ "SPN" SG_ 2565870078 OutletGasSnsr1HeatrPrelFMI_3271 3271;
BA_ "SPN" SG_ 2565870078 OutletWidRngPercO21RdingStb_3270 3270;
BA_ "SigType" SG_ 2565870078 OutletWidRngPercO21RdingStb_3270 5;
BA_ "SPN" SG_ 2565870078 OutletNOx1ReadingStable_3269 3269;
BA_ "SigType" SG_ 2565870078 OutletNOx1ReadingStable_3269 5;
BA_ "SPN" SG_ 2565870078 OutletNOxSnsr1SelfDiagSts_5715 5715;
BA_ "SPN" SG_ 2565870078 OutletGasSnsr1AtTemp_3268 3268;
BA_ "SigType" SG_ 2565870078 OutletGasSnsr1AtTemp_3268 5;
BA_ "SPN" SG_ 2565870078 OutletGasSnsr1PwrInRange_3267 3267;
BA_ "SigType" SG_ 2565870078 OutletGasSnsr1PwrInRange_3267 5;
BA_ "SPN" SG_ 2565870078 OutletPercentOxyzen1_3266 3266;
BA_ "SigType" SG_ 2565870078 OutletPercentOxyzen1_3266 1;
BA_ "SPN" SG_ 2565870078 OutletNOx1_3265 3265;
BA_ "SigType" SG_ 2565870078 OutletNOx1_3265 1;
BA_ "SPN" SG_ 2566762750 DPFExhTempPreliminaryFMI 3282;
BA_ "SPN" SG_ 2566762750 ExhTemp3PreliminaryFMI 3281;
BA_ "SPN" SG_ 2566762750 DPFOutTemp 3280;
BA_ "SigType" SG_ 2566762750 DPFOutTemp 1;
BA_ "SPN" SG_ 2566762750 ExhTemp3 3279;
BA_ "SigType" SG_ 2566762750 ExhTemp3 1;
BA_ "SPN" SG_ 2566748926 DPFSootLoadRegenThreshold 5467;
BA_ "SigType" SG_ 2566748926 DPFSootLoadRegenThreshold 1;
BA_ "SPN" SG_ 2566748926 DPFTimeSinceLastActiveRegen 3724;
BA_ "SigType" SG_ 2566748926 DPFTimeSinceLastActiveRegen 1;
BA_ "SPN" SG_ 2566748926 DPFAshLoadPercent 3723;
BA_ "SigType" SG_ 2566748926 DPFAshLoadPercent 1;
BA_ "SPN" SG_ 2566748926 DPFSootLoadPercent 3722;
BA_ "SigType" SG_ 2566748926 DPFSootLoadPercent 1;
BA_ "SPN" SG_ 2566748414 DPFTripNumOfActiveRegenManReq 3748;
BA_ "SigType" SG_ 2566748414 DPFTripNumOfActiveRegenManReq 1;
BA_ "SPN" SG_ 2566748414 DPFTripNumOfActiveRegenInhReq 3747;
BA_ "SigType" SG_ 2566748414 DPFTripNumOfActiveRegenInhReq 1;
BA_ "SPN" SG_ 2566748414 DPFTripNumOfPassiveRegens 3746;
BA_ "SigType" SG_ 2566748414 DPFTripNumOfPassiveRegens 1;
BA_ "SPN" SG_ 2566748414 DPFTripPassiveRegenTime 3745;
BA_ "SigType" SG_ 2566748414 DPFTripPassiveRegenTime 1;
BA_ "SPN" SG_ 2566748414 DPFTripNumOfActiveRegens 3744;
BA_ "SigType" SG_ 2566748414 DPFTripNumOfActiveRegens 1;
BA_ "SPN" SG_ 2566748414 DPFTripDisdTime 3743;
BA_ "SigType" SG_ 2566748414 DPFTripDisdTime 1;
BA_ "SPN" SG_ 2566748414 DPFTripActiveRegenTime 3742;
BA_ "SigType" SG_ 2566748414 DPFTripActiveRegenTime 1;
BA_ "SPN" SG_ 2566748414 DPFTripFuelUsed 3741;
BA_ "SigType" SG_ 2566748414 DPFTripFuelUsed 1;
BA_ "GenSigStartValue" SG_ 2365428478 EngDesiredTorqueRq 125;
BA_ "SPN" SG_ 2365428478 EngDesiredTorqueRq 6807;
BA_ "SigType" SG_ 2365428478 EngDesiredTorqueRq 1;
BA_ "SPN" SG_ 2365428478 EngColdAmbientElevatedIdleStatus 6884;
BA_ "SigType" SG_ 2365428478 EngColdAmbientElevatedIdleStatus 5;
BA_ "SPN" SG_ 2365428478 EngStarterMotorRelayCtrl 6385;
BA_ "SigType" SG_ 2365428478 EngStarterMotorRelayCtrl 5;
BA_ "SPN" SG_ 2365428478 EngDerateRq 3644;
BA_ "SigType" SG_ 2365428478 EngDerateRq 1;
BA_ "SPN" SG_ 2365428478 EngEmergencyShutdownIndication 3607;
BA_ "SigType" SG_ 2365428478 EngEmergencyShutdownIndication 5;
BA_ "SPN" SG_ 2365428478 EngControlledShutdownRq 3606;
BA_ "SigType" SG_ 2365428478 EngControlledShutdownRq 5;
BA_ "SPN" SG_ 2365428478 EngCoolantCirculatingPumpCtrl 3605;
BA_ "SigType" SG_ 2365428478 EngCoolantCirculatingPumpCtrl 5;
BA_ "SPN" SG_ 2365428478 EngBlock_CoolantPreheaterCtrl 3604;
BA_ "SigType" SG_ 2365428478 EngBlock_CoolantPreheaterCtrl 5;
BA_ "SPN" SG_ 2365428478 EngElctrclSystmPwrCnsrvationCtrl 3603;
BA_ "SigType" SG_ 2365428478 EngElctrclSystmPwrCnsrvationCtrl 5;
BA_ "SPN" SG_ 2365428478 EngOilPreheaterCtrl 3602;
BA_ "SigType" SG_ 2365428478 EngOilPreheaterCtrl 5;
BA_ "SPN" SG_ 2365428478 EngOilPrimingPumpCtrl 3589;
BA_ "SigType" SG_ 2365428478 EngOilPrimingPumpCtrl 5;
BA_ "SPN" SG_ 2365428478 EngFuelShutoffValveLeakTestCtrl 3601;
BA_ "SigType" SG_ 2365428478 EngFuelShutoffValveLeakTestCtrl 5;
BA_ "SPN" SG_ 2365428478 EngFuelShutoff2Ctrl 2807;
BA_ "SigType" SG_ 2365428478 EngFuelShutoff2Ctrl 5;
BA_ "SPN" SG_ 2365428478 EngFuelShutoff1Ctrl 632;
BA_ "SigType" SG_ 2365428478 EngFuelShutoff1Ctrl 5;
BA_ "SPN" SG_ 2365428478 EngFuelShutoffVentCtrl 3608;
BA_ "SigType" SG_ 2365428478 EngFuelShutoffVentCtrl 5;
BA_ "SPN" SG_ 2365428478 TimeRemainingInEngOperatingState 3544;
BA_ "SigType" SG_ 2365428478 TimeRemainingInEngOperatingState 1;
BA_ "SPN" SG_ 2365428478 FuelPumpPrimerCtrl 4082;
BA_ "SigType" SG_ 2365428478 FuelPumpPrimerCtrl 5;
BA_ "SPN" SG_ 2365428478 EngOperatingState 3543;
BA_ "SPN" SG_ 2566743806 EngCoolantTemp3 6209;
BA_ "SigType" SG_ 2566743806 EngCoolantTemp3 1;
BA_ "SPN" SG_ 2566743806 EngExhstGsRcrcltn1MxerIntakeTemp 5020;
BA_ "SigType" SG_ 2566743806 EngExhstGsRcrcltn1MxerIntakeTemp 1;
BA_ "SPN" SG_ 2566743806 EngExhstVlvActationSystemOilTemp 4288;
BA_ "SigType" SG_ 2566743806 EngExhstVlvActationSystemOilTemp 1;
BA_ "SPN" SG_ 2566743806 EngCoolantThermostatOpening 4194;
BA_ "SigType" SG_ 2566743806 EngCoolantThermostatOpening 1;
BA_ "SPN" SG_ 2566743806 EngCoolantPumpOutletTemp 4193;
BA_ "SigType" SG_ 2566743806 EngCoolantPumpOutletTemp 1;
BA_ "SPN" SG_ 2566743806 EngCoolantTemp2 4076;
BA_ "SigType" SG_ 2566743806 EngCoolantTemp2 1;
BA_ "SPN" SG_ 2499635454 NetVehicleWeightChange 413;
BA_ "SPN" SG_ 2499635454 GrossCombinationWeight 417;
BA_ "SPN" SG_ 2550660862 ValveAssemblySupplyPress_4089 4089;
BA_ "SigType" SG_ 2550660862 ValveAssemblySupplyPress_4089 1;
BA_ "SPN" SG_ 2550660862 ValveAssemblyLoadSensePress_4088 4088;
BA_ "SigType" SG_ 2550660862 ValveAssemblyLoadSensePress_4088 1;
BA_ "SPN" SG_ 2550660862 ValvePilotPress_4087 4087;
BA_ "SigType" SG_ 2550660862 ValvePilotPress_4087 1;
BA_ "SPN" SG_ 2550660862 ValveLoadSensePress_4086 4086;
BA_ "SigType" SG_ 2550660862 ValveLoadSensePress_4086 1;
BA_ "SPN" SG_ 2566805758 BellowPressRearAxleRight 1728;
BA_ "SigType" SG_ 2566805758 BellowPressRearAxleRight 1;
BA_ "SPN" SG_ 2566805758 BellowPressRearAxleLeft 1727;
BA_ "SigType" SG_ 2566805758 BellowPressRearAxleLeft 1;
BA_ "SPN" SG_ 2566805758 BellowPressFrontAxleRight 1726;
BA_ "SigType" SG_ 2566805758 BellowPressFrontAxleRight 1;
BA_ "SPN" SG_ 2566805758 BellowPressFrontAxleLeft 1725;
BA_ "SigType" SG_ 2566805758 BellowPressFrontAxleLeft 1;
BA_ "SPN" SG_ 2566806014 RelativeLevelRearAxleRight 1723;
BA_ "SigType" SG_ 2566806014 RelativeLevelRearAxleRight 1;
BA_ "SPN" SG_ 2566806014 RelativeLevelRearAxleLeft 1724;
BA_ "SigType" SG_ 2566806014 RelativeLevelRearAxleLeft 1;
BA_ "SPN" SG_ 2566806014 RelativeLevelFrontAxleRight 1722;
BA_ "SigType" SG_ 2566806014 RelativeLevelFrontAxleRight 1;
BA_ "SPN" SG_ 2566806014 RelativeLevelFrontAxleLeft 1721;
BA_ "SigType" SG_ 2566806014 RelativeLevelFrontAxleLeft 1;
BA_ "SPN" SG_ 2362638078 MemoryLevelReq_5433 5433;
BA_ "SPN" SG_ 2362638078 ProhibitAASControl_5274 5274;
BA_ "SigType" SG_ 2362638078 ProhibitAASControl_5274 5;
BA_ "SPN" SG_ 2362638078 SpdDependentLevelCtrlRq_5295 5295;
BA_ "SigType" SG_ 2362638078 SpdDependentLevelCtrlRq_5295 5;
BA_ "SPN" SG_ 2362638078 AllwLvlCtrlDuringBrakingCmd_5293 5293;
BA_ "SigType" SG_ 2362638078 AllwLvlCtrlDuringBrakingCmd_5293 5;
BA_ "SPN" SG_ 2362638078 ProhibitAirSuspensionCtrl_3215 3215;
BA_ "SigType" SG_ 2362638078 ProhibitAirSuspensionCtrl_3215 5;
BA_ "SPN" SG_ 2362638078 KneelingCmdRearAxle_1829 1829;
BA_ "SigType" SG_ 2362638078 KneelingCmdRearAxle_1829 5;
BA_ "SPN" SG_ 2362638078 KneelingCmdFrontAxle_1830 1830;
BA_ "SigType" SG_ 2362638078 KneelingCmdFrontAxle_1830 5;
BA_ "SPN" SG_ 2362638078 DamprStfnReqLiftOrTagAxle_1720 1720;
BA_ "SigType" SG_ 2362638078 DamprStfnReqLiftOrTagAxle_1720 1;
BA_ "SPN" SG_ 2362638078 DamperStiffnessRqRearAxle_1719 1719;
BA_ "SigType" SG_ 2362638078 DamperStiffnessRqRearAxle_1719 1;
BA_ "SPN" SG_ 2362638078 DamperStiffnessRqFrontAxle_1718 1718;
BA_ "SigType" SG_ 2362638078 DamperStiffnessRqFrontAxle_1718 1;
BA_ "SPN" SG_ 2362638078 LiftAxle2PosCmd_1828 1828;
BA_ "SigType" SG_ 2362638078 LiftAxle2PosCmd_1828 5;
BA_ "SPN" SG_ 2362638078 LiftAxle1PosCmd_1752 1752;
BA_ "SigType" SG_ 2362638078 LiftAxle1PosCmd_1752 5;
BA_ "SPN" SG_ 2362638078 LevelCtrlModeRq_1753 1753;
BA_ "SPN" SG_ 2362638078 NominalLevelRqRearAxle_1750 1750;
BA_ "SPN" SG_ 2362638078 NominalLevelRqFrontAxle_1751 1751;
BA_ "SPN" SG_ 2362638078 KneelingCtrlModeRq_1747 1747;
BA_ "SigType" SG_ 2362638078 KneelingCtrlModeRq_1747 5;
BA_ "SPN" SG_ 2362638078 KneelingRqRightSide_1748 1748;
BA_ "SigType" SG_ 2362638078 KneelingRqRightSide_1748 5;
BA_ "SPN" SG_ 2362638078 KneelingRqLeftSide_1749 1749;
BA_ "SigType" SG_ 2362638078 KneelingRqLeftSide_1749 5;
BA_ "SPN" SG_ 2362638078 AutomaticTractionHelp_2984 2984;
BA_ "SigType" SG_ 2362638078 AutomaticTractionHelp_2984 5;
BA_ "SPN" SG_ 2365479678 MemoryLevel 5432;
BA_ "SPN" SG_ 2365479678 SuspensionCtrlRefusalInformation 1827;
BA_ "SPN" SG_ 2365479678 SpeedDependantLevelCtrlStatus 5296;
BA_ "SigType" SG_ 2365479678 SpeedDependantLevelCtrlStatus 5;
BA_ "SPN" SG_ 2365479678 AllwLevelCtrlDuringBrakingStatus 5294;
BA_ "SigType" SG_ 2365479678 AllwLevelCtrlDuringBrakingStatus 5;
BA_ "SPN" SG_ 2365479678 SuspensionRemoteCtrl2 1825;
BA_ "SigType" SG_ 2365479678 SuspensionRemoteCtrl2 4;
BA_ "SPN" SG_ 2365479678 SuspensionRemoteCtrl1 1826;
BA_ "SigType" SG_ 2365479678 SuspensionRemoteCtrl1 4;
BA_ "SPN" SG_ 2365479678 LiftAxle2Pos 1822;
BA_ "SigType" SG_ 2365479678 LiftAxle2Pos 4;
BA_ "SPN" SG_ 2365479678 RearAxleInBumperRange 1823;
BA_ "SigType" SG_ 2365479678 RearAxleInBumperRange 4;
BA_ "SPN" SG_ 2365479678 FrontAxleInBumperRange 1824;
BA_ "SigType" SG_ 2365479678 FrontAxleInBumperRange 4;
BA_ "SPN" SG_ 2365479678 LiftAxle1Pos 1743;
BA_ "SigType" SG_ 2365479678 LiftAxle1Pos 4;
BA_ "SPN" SG_ 2365479678 DoorRelease 1744;
BA_ "SigType" SG_ 2365479678 DoorRelease 5;
BA_ "SPN" SG_ 2365479678 VehicleMotionInhibit 1745;
BA_ "SigType" SG_ 2365479678 VehicleMotionInhibit 5;
BA_ "SPN" SG_ 2365479678 SecurityDevice 1746;
BA_ "SigType" SG_ 2365479678 SecurityDevice 5;
BA_ "SPN" SG_ 2365479678 LevelCtrlMode 1741;
BA_ "SPN" SG_ 2365479678 KneelingInformation 1742;
BA_ "SPN" SG_ 2365479678 LiftingCtrlModeRearAxle 1756;
BA_ "SigType" SG_ 2365479678 LiftingCtrlModeRearAxle 5;
BA_ "SPN" SG_ 2365479678 LiftingCtrlModeFrontAxle 1739;
BA_ "SigType" SG_ 2365479678 LiftingCtrlModeFrontAxle 5;
BA_ "SPN" SG_ 2365479678 LoweringCtrlModeRearAxle 1755;
BA_ "SigType" SG_ 2365479678 LoweringCtrlModeRearAxle 5;
BA_ "SPN" SG_ 2365479678 LoweringCtrlModeFrontAxle 1740;
BA_ "SigType" SG_ 2365479678 LoweringCtrlModeFrontAxle 5;
BA_ "SPN" SG_ 2365479678 AboveNominalLevelRearAxle 1736;
BA_ "SigType" SG_ 2365479678 AboveNominalLevelRearAxle 4;
BA_ "SPN" SG_ 2365479678 AboveNominalLevelFrontAxle 1737;
BA_ "SigType" SG_ 2365479678 AboveNominalLevelFrontAxle 4;
BA_ "SPN" SG_ 2365479678 BelowNominalLevelRearAxle 1754;
BA_ "SigType" SG_ 2365479678 BelowNominalLevelRearAxle 5;
BA_ "SPN" SG_ 2365479678 BelowNominalLevelFrontAxle 1738;
BA_ "SigType" SG_ 2365479678 BelowNominalLevelFrontAxle 4;
BA_ "SPN" SG_ 2365479678 NominalLevelRearAxle 1733;
BA_ "SPN" SG_ 2365479678 NominalLevelFrontAxle 1734;
BA_ "SPN" SG_ 2566837758 Alt4Status 3356;
BA_ "SigType" SG_ 2566837758 Alt4Status 4;
BA_ "SPN" SG_ 2566837758 Alt3Status 3355;
BA_ "SigType" SG_ 2566837758 Alt3Status 4;
BA_ "SPN" SG_ 2566837758 Alt2Status 3354;
BA_ "SigType" SG_ 2566837758 Alt2Status 4;
BA_ "SPN" SG_ 2566837758 Alt1Status 3353;
BA_ "SigType" SG_ 2566837758 Alt1Status 4;
BA_ "SPN" SG_ 2566837758 AltSpeed 589;
BA_ "SigType" SG_ 2566837758 AltSpeed 1;
BA_ "SPN" SG_ 2633922558 AuxAbsPressReading 138;
BA_ "SigType" SG_ 2633922558 AuxAbsPressReading 1;
BA_ "SPN" SG_ 2633922558 AuxGagePressReading1 137;
BA_ "SigType" SG_ 2633922558 AuxGagePressReading1 1;
BA_ "SPN" SG_ 2633922558 AuxVacuumPressReading 136;
BA_ "SigType" SG_ 2633922558 AuxVacuumPressReading 1;
BA_ "SPN" SG_ 2566775038 BarometricAbsPressHighResolution 5685;
BA_ "SigType" SG_ 2566775038 BarometricAbsPressHighResolution 1;
BA_ "SPN" SG_ 2566775038 CalculatedAmbientAirTemp 5581;
BA_ "SigType" SG_ 2566775038 CalculatedAmbientAirTemp 1;
BA_ "SPN" SG_ 2566775038 SpecificHumidity 4490;
BA_ "SigType" SG_ 2566775038 SpecificHumidity 1;
BA_ "SPN" SG_ 2566775038 SolarSensorMax 2611;
BA_ "SigType" SG_ 2566775038 SolarSensorMax 1;
BA_ "SPN" SG_ 2566775038 SolarIntensityPercent 2610;
BA_ "SigType" SG_ 2566775038 SolarIntensityPercent 1;
BA_ "SPN" SG_ 2566836478 TestLimitMinimum 1228;
BA_ "SigType" SG_ 2566836478 TestLimitMinimum 1;
BA_ "SPN" SG_ 2566836478 TestLimitMaximum 1227;
BA_ "SigType" SG_ 2566836478 TestLimitMaximum 1;
BA_ "SPN" SG_ 2566836478 TestValue 1226;
BA_ "SigType" SG_ 2566836478 TestValue 1;
BA_ "SPN" SG_ 2566836478 TestType 1225;
BA_ "SigType" SG_ 2566836478 TestType 1;
BA_ "SPN" SG_ 2566836478 TestIdentifier 1224;
BA_ "SPN" SG_ 2565078782 SPN1_4148 4148;
BA_ "SPN" SG_ 2565078782 TestIdentifier_1224 1224;
BA_ "SPN" SG_ 2565078782 FailureModeIdentifier1_4149 4149;
BA_ "SPN" SG_ 2566836222 FlashRedStopLamp 3039;
BA_ "SigType" SG_ 2566836222 FlashRedStopLamp 5;
BA_ "SPN" SG_ 2566836222 FlashProtectLamp 3041;
BA_ "SigType" SG_ 2566836222 FlashProtectLamp 5;
BA_ "SPN" SG_ 2566836222 FlashMalfuncIndicatorLamp 3038;
BA_ "SigType" SG_ 2566836222 FlashMalfuncIndicatorLamp 5;
BA_ "SPN" SG_ 2566836222 FlashAmberWarningLamp 3040;
BA_ "SigType" SG_ 2566836222 FlashAmberWarningLamp 5;
BA_ "SPN" SG_ 2566836222 MalfunctionIndicatorLampStatus 1213;
BA_ "SigType" SG_ 2566836222 MalfunctionIndicatorLampStatus 5;
BA_ "SPN" SG_ 2566836222 RedStopLampState 623;
BA_ "SigType" SG_ 2566836222 RedStopLampState 4;
BA_ "SPN" SG_ 2566836222 AmberWarningLampStatus 624;
BA_ "SigType" SG_ 2566836222 AmberWarningLampStatus 5;
BA_ "SPN" SG_ 2566836222 ProtectLampStatus 987;
BA_ "SigType" SG_ 2566836222 ProtectLampStatus 5;
BA_ "SigType" SG_ 2566836222 DTC5 7;
BA_ "SigType" SG_ 2566836222 DTC4 7;
BA_ "SigType" SG_ 2566836222 DTC3 7;
BA_ "SigType" SG_ 2566836222 DTC2 7;
BA_ "SigType" SG_ 2566836222 DTC1 7;
BA_ "SystemSignalLongSymbol" SG_ 2566835966 NOxConvertingCatalystAdsorberSta "NOxConvertingCatalystAdsorberStatus";
BA_ "SystemSignalLongSymbol" SG_ 2566835966 BoostPressureControlSystemSuppor "BoostPressureControlSystemSupport";
BA_ "SystemSignalLongSymbol" SG_ 2566835966 NOxConvertingCatalystAdsorberSup "NOxConvertingCatalystAdsorberSupport";
BA_ "SPN" SG_ 2566835966 OBDCompliance 1220;
BA_ "SigType" SG_ 2566835966 OBDCompliance 1;
BA_ "SPN" SG_ 2566835966 PreviouslyActiveTroubleCodes 1219;
BA_ "SigType" SG_ 2566835966 PreviouslyActiveTroubleCodes 1;
BA_ "SPN" SG_ 2566835966 ActiveTroubleCodes 1218;
BA_ "SigType" SG_ 2566835966 ActiveTroubleCodes 1;
BA_ "SPN" SG_ 2566835710 EngIntakeManifold1Press 102;
BA_ "SigType" SG_ 2566835710 EngIntakeManifold1Press 1;
BA_ "SPN" SG_ 2566835710 FreezeFrameLength 1217;
BA_ "SPN" SG_ 2566835710 EngSpeed 190;
BA_ "SigType" SG_ 2566835710 EngSpeed 1;
BA_ "SPN" SG_ 2566835710 EngTorqueMode 899;
BA_ "SPN" SG_ 2566835710 WheelBasedVehicleSpeed 84;
BA_ "SigType" SG_ 2566835710 WheelBasedVehicleSpeed 1;
BA_ "SPN" SG_ 2566835710 EngPercentLoadAtCurrentSpeed 92;
BA_ "SigType" SG_ 2566835710 EngPercentLoadAtCurrentSpeed 1;
BA_ "SPN" SG_ 2566835710 EngCoolantTemp 110;
BA_ "SigType" SG_ 2566835710 EngCoolantTemp 1;
BA_ "SigType" SG_ 2566835710 DTC1 7;
BA_ "SPN" SG_ 2566764542 ExpandedFreezeFrameLength 3300;
BA_ "SigType" SG_ 2566764542 ExpandedFreezeFrameLength 1;
BA_ "SigType" SG_ 2566764542 DTC1 7;
BA_ "SigType" SG_ 2566764286 SPNDataLength3 1;
BA_ "SPN" SG_ 2566764286 SPNSupportTypeSTR1 4102;
BA_ "SPN" SG_ 2566764286 SPNSupportTypeDS1 4101;
BA_ "SPN" SG_ 2566764286 SPNSupportTypeEFF1 4100;
BA_ "SigType" SG_ 2566764286 SPNDataLength2 1;
BA_ "SPN" SG_ 2566764286 SPNDataLength1 4103;
BA_ "SigType" SG_ 2566764286 SPNDataLength1 1;
BA_ "SPN" SG_ 2566764286 SPNSupported1 3297;
BA_ "SPN" SG_ 2566764030 FlashRedStopLamp 3039;
BA_ "SigType" SG_ 2566764030 FlashRedStopLamp 5;
BA_ "SPN" SG_ 2566764030 FlashProtectLamp 3041;
BA_ "SigType" SG_ 2566764030 FlashProtectLamp 5;
BA_ "SPN" SG_ 2566764030 FlashMalfuncIndicatorLamp 3038;
BA_ "SigType" SG_ 2566764030 FlashMalfuncIndicatorLamp 5;
BA_ "SPN" SG_ 2566764030 FlashAmberWarningLamp 3040;
BA_ "SigType" SG_ 2566764030 FlashAmberWarningLamp 5;
BA_ "SPN" SG_ 2566764030 MalfunctionIndicatorLampStatus 1213;
BA_ "SigType" SG_ 2566764030 MalfunctionIndicatorLampStatus 5;
BA_ "SPN" SG_ 2566764030 RedStopLampState 623;
BA_ "SigType" SG_ 2566764030 RedStopLampState 4;
BA_ "SPN" SG_ 2566764030 AmberWarningLampStatus 624;
BA_ "SigType" SG_ 2566764030 AmberWarningLampStatus 5;
BA_ "SPN" SG_ 2566764030 ProtectLampStatus 987;
BA_ "SigType" SG_ 2566764030 ProtectLampStatus 5;
BA_ "SigType" SG_ 2566764030 DTC5 7;
BA_ "SigType" SG_ 2566764030 DTC4 7;
BA_ "SigType" SG_ 2566764030 DTC3 7;
BA_ "SigType" SG_ 2566764030 DTC2 7;
BA_ "SigType" SG_ 2566764030 DTC1 7;
VAL_ 2566736382 EngExhstGsOxygnSnsrClsdLpOprtnBn 0 "Open loop, has not yet satisfied conditions to go closed loop" 1 "Closed loop, using oxygen sensor(s) as feedback for fuel control" 2 "Open loop due to driving conditions" 3 "Open loop, due to detected system fault " 4 "Closed loop,  but fault with at least one oxygen sensor" 15 "not supported";
VAL_ 2565874174 EngSpdSensor1TimingPatternStatus 0 "Not OK" 1 "OK" 2 "Error" 3 "Not available";
VAL_ 2565874174 EngSpdSensor2TimingPatternStatus 0 "Not OK" 1 "OK" 2 "Error" 3 "Not available";
VAL_ 2565874174 EngSpdSensor3TimingPatternStatus 0 "Not OK" 1 "OK" 2 "Error" 3 "Not available";
VAL_ 2432520958 EngCoolantThermostatMode 0 "temperature control mode" 1 "position control mode" 2 "reserved" 3 "don't care/reserved";
VAL_ 2566758398 EnableAct 0 "not active" 1 "active" 2 "reserved for SAE assignment" 3 "not available";
VAL_ 2566758398 PurgeAirAct 0 "not active" 1 "active" 2 "reserved for SAE assignment" 3 "not available";
VAL_ 2566758398 AtomizationAirAct 0 "not active" 1 "active" 2 "reserved for SAE assignment" 3 "not available";
VAL_ 2566758398 SysRelay 0 "not active" 1 "active" 2 "reserved for SAE assignment" 3 "not available";
VAL_ 2566758910 EnableAct 0 "not active" 1 "active" 2 "reserved for SAE assignment" 3 "not available";
VAL_ 2566758910 RegenStatus 0 "not active" 1 "active" 2 "reserved for SAE assignment" 3 "not available";
VAL_ 2566758910 Ignt 0 "not active" 1 "active" 2 "reserved for SAE assignment" 3 "not available";
VAL_ 2566758910 DrainAct 0 "not active" 1 "active" 2 "reserved for SAE assignment" 3 "not available";
VAL_ 2566743550 FlowDiverterVlvCtrl 0 "off" 1 "on" 2 "reserved for SAE assignment" 3 "not available";
VAL_ 2566743550 PumpRelayCtrl 0 "off" 1 "on" 2 "reserved for SAE assignment" 3 "not available";
VAL_ 2565869310 IntkNOxSnsr1SelfDiagStatus_5714 0 "Diagnosis not active" 1 "NOx Sensor ATI1 Self Diagnosis active flag" 2 "NOx Sensor ATI1 Self Diagnosis Result Complete" 3 "NOx Sensor ATI1 Self Diagnosis aborted" 4 "NOx Sensor ATI1 Self Diagnosis not possible" 7 "Not Supported";
VAL_ 2565869310 IntkGasSnsr1HeatrCtl_3223 0 "Automatic" 1 "Preheat 2" 2 "Preheat 1" 3 "Heater off";
VAL_ 2565869310 IWRPO1ReadingStab_3221 0 "Not stable" 1 "Stable" 2 "Error" 3 "Not available";
VAL_ 2565869310 SCRIntkNOx1ReadingStab_3220 0 "Not stable" 1 "Stable" 2 "Error" 3 "Not available";
VAL_ 2565869310 IntkGasSnsr1AtTemp_3219 0 "Not in range" 1 "In range" 2 "Error" 3 "Not available";
VAL_ 2565869310 IntkGasSnsr1PwrInRng_3218 0 "Not in range" 1 "In range" 2 "Error" 3 "Not available";
VAL_ 2631728894 AntitheftModifyPwdStates_1197 0 "Ok" 1 "Full_of_Passwords" 2 "Empty_of_Passwords" 3 "Not_valid";
VAL_ 2631728894 AntiThftCptStatusStates_1196 0 "Unlocked" 1 "Locked" 2 "Blocked" 3 "Not defined";
VAL_ 2631728894 AntitheftPwdValidIndicator_1195 0 "Password is not a validated password" 1 "Password is a validated password" 2 "Error" 3 "Not available";
VAL_ 2631728894 AntiThftEncrpSeedPrestIndcr_1194 0 "Random number is not present" 1 "Random number is present" 2 "Error" 3 "Not available";
VAL_ 2631794430 AntiTheftCmdStates_1201 0 "Add_Password" 1 "Delete_Password" 2 "Change_Password" 3 "Lock_or_Unlock" 4 "Check_Status" 5 "Login";
VAL_ 2631794430 AntiThftDesExitModeStates_1200 0 "Lock_Upon_Operator_Request" 1 "Lock_When_Key_Off" 2 "Not defined" 3 "Not_Available";
VAL_ 2631794430 AntiThftEncrpnIndcrStates_1199 0 "Encryption_Seed_Request" 1 "Encrypted_Code_Present" 2 "Not defined" 3 "Not_Available";
VAL_ 2365478910 ElctrncShckAbsrbrCtrlMdLft_TgAxl 0 "Normal operation dampers passive" 1 "Normal operation dampers active" 2 "Error" 3 "Not available";
VAL_ 2365478910 ElctrncShckAbsrbrCtrlMdeRearAxle 0 "Normal operation dampers passive" 1 "Normal operation dampers active" 2 "Error" 3 "Not available";
VAL_ 2365478910 ElctrncShckAbsrbrCtrlMdFrontAxle 0 "Normal operation dampers passive" 1 "Normal operation dampers active" 2 "Error" 3 "Not available";
VAL_ 2560950014 FailureModeIdentifier1_1215 0 "Above normal (most severe)" 1 "Below normal (most severe)" 2 "Data erratic" 3 "Voltage above normal" 4 "Voltage below normal" 5 "Current below normal" 6 "Current above normal" 7 "Mechanical system not responding" 8 "Abnormal frequency" 9 "Abnormal update rate" 10 "Abnormal rate of change" 11 "Root cause not known" 12 "Bad intelligent device" 13 "Out of calibration" 14 "Special intstructions" 15 "Above normal (least severe)" 16 "Above normal (moderately severe)" 17 "Below normal (least severe)" 18 "Below normal (moderately severe)" 19 "Received network data in error" 31 "Not available";
VAL_ 2565869566 OutletNOxSnsr1SelfDiagSts_5713 0 "Diagnosis not active" 1 "NOx Sensor ATO1 Self Diagnosis active flag" 2 "NOx Sensor ATO1 Self Diagnosis Result Complete" 3 "NOx Sensor ATO1 Self Diagnosis aborted" 4 "NOx Sensor ATO1 Self Diagnosis not possible" 7 "Not Supported";
VAL_ 2565869566 OutletGasSnsr1HeatrCtrl_3233 0 "Automatic" 1 "Preheat 2" 2 "Preheat 1" 3 "Heater off";
VAL_ 2565869566 OutletWideRngPercOxyzen1_3231 0 "Not stable" 1 "Stable" 2 "Error" 3 "Not available";
VAL_ 2565869566 OutletNOx1ReadingStable_3230 0 "Not stable" 1 "Stable" 2 "Error" 3 "Not available";
VAL_ 2565869566 OutletGasSnsr1AtTemp_3229 0 "Not in range" 1 "In range" 2 "Error" 3 "Not available";
VAL_ 2565869566 OutletGasSnsr1PwrInRng_3228 0 "Not in range" 1 "In range" 2 "Error" 3 "Not available";
VAL_ 2566758142 EnableAct 0 "not active" 1 "active" 2 "reserved for SAE assignment" 3 "not available";
VAL_ 2566758142 PurgeAirAct 0 "not active" 1 "active" 2 "reserved for SAE assignment" 3 "not available";
VAL_ 2566758142 AtomizationAirAct 0 "not active" 1 "active" 2 "reserved for SAE assignment" 3 "not available";
VAL_ 2566758142 SysRelay 0 "not active" 1 "active" 2 "reserved for SAE assignment" 3 "not available";
VAL_ 2566758654 EnableAct 0 "not active" 1 "active" 2 "reserved for SAE assignment" 3 "not available";
VAL_ 2566758654 RegenStatus 0 "not active" 1 "active" 2 "reserved for SAE assignment" 3 "not available";
VAL_ 2566758654 Ignt 0 "not active" 1 "active" 2 "reserved for SAE assignment" 3 "not available";
VAL_ 2566758654 DrainAct 0 "not active" 1 "active" 2 "reserved for SAE assignment" 3 "not available";
VAL_ 2565869822 IntkNOxSnsr1SelfDiagStatus_5716 0 "Diagnosis not active" 1 "NOx Sensor ATI2 Self Diagnosis active flag" 2 "NOx Sensor ATI2 Self Diagnosis Result Complete" 3 "NOx Sensor ATI2 Self Diagnosis aborted" 4 "NOx Sensor ATI2 Self Diagnosis not possible" 7 "Not Supported";
VAL_ 2565869822 IntkGasSnsr1HeatrCtl_3262 0 "Automatic" 1 "Preheat 2" 2 "Preheat 1" 3 "Heater off";
VAL_ 2565869822 IntkWideRngPercOxyzen1_3260 0 "Not stable" 1 "Stable" 2 "Error" 3 "Not available";
VAL_ 2565869822 SCRIntkNOx1ReadingStable_3259 0 "Not stable" 1 "Stable" 2 "Error" 3 "Not available";
VAL_ 2565869822 IntkGasSnsr1AtTemp_3258 0 "Not in range" 1 "In range" 2 "Error" 3 "Not available";
VAL_ 2565869822 IntkGasSnsr1PwrInRange_3257 0 "Not in range" 1 "In range" 2 "Error" 3 "Not available";
VAL_ 2565870078 OutletGasSnsr1HtrCtl_3272 0 "Automatic" 1 "Preheat 2" 2 "Preheat 1" 3 "Heater off";
VAL_ 2565870078 OutletWidRngPercO21RdingStb_3270 0 "Not stable" 1 "Stable" 2 "Error" 3 "Not available";
VAL_ 2565870078 OutletNOx1ReadingStable_3269 0 "Not stable" 1 "Stable" 2 "Error" 3 "Not available";
VAL_ 2565870078 OutletNOxSnsr1SelfDiagSts_5715 0 "Diagnosis not active" 1 "NOx Sensor ATO2 Self Diagnosis active flag" 2 "NOx Sensor ATO2 Self Diagnosis Result Complete" 3 "NOx Sensor ATO2 Self Diagnosis aborted" 4 "NOx Sensor ATO2 Self Diagnosis not possible" 7 "Not Supported";
VAL_ 2565870078 OutletGasSnsr1AtTemp_3268 0 "Not in range" 1 "In range" 2 "Error" 3 "Not available";
VAL_ 2565870078 OutletGasSnsr1PwrInRange_3267 0 "Not in range" 1 "In range" 2 "Error" 3 "Not available";
VAL_ 2365428478 EngColdAmbientElevatedIdleStatus 0 "No Idle Elevation Active" 1 "Idle Elevation Active" 2 "Reserved for SAE assignment" 3 "Unavailable";
VAL_ 2365428478 EngStarterMotorRelayCtrl 0 "Off" 1 "On" 2 "Reserved for SAE assignment" 3 "Don't care/take no action";
VAL_ 2365428478 EngEmergencyShutdownIndication 0 "Off" 1 "On" 2 "Reserved" 3 "Don't care / take no action";
VAL_ 2365428478 EngControlledShutdownRq 0 "Off" 1 "On" 2 "Reserved" 3 "Don't care / take no action";
VAL_ 2365428478 EngCoolantCirculatingPumpCtrl 0 "Off" 1 "On" 2 "Reserved" 3 "Don't care / take no action";
VAL_ 2365428478 EngBlock_CoolantPreheaterCtrl 0 "Off " 1 "On" 2 "Reserved" 3 "Unavailable";
VAL_ 2365428478 EngElctrclSystmPwrCnsrvationCtrl 0 "Off" 1 "On" 2 "Reserved" 3 "Unavailable";
VAL_ 2365428478 EngOilPreheaterCtrl 0 "Off" 1 "On" 2 "Reserved" 3 "Don't care / take no action";
VAL_ 2365428478 EngOilPrimingPumpCtrl 0 "Off" 1 "On" 2 "Reserved" 3 "unavailable";
VAL_ 2365428478 EngFuelShutoffValveLeakTestCtrl 0 "Off" 1 "On" 2 "Reserved" 3 "Don't care / take no action";
VAL_ 2365428478 EngFuelShutoff2Ctrl 0 "Open" 1 "Closed" 2 "Reserved" 3 "Don't care / take no action";
VAL_ 2365428478 EngFuelShutoff1Ctrl 0 "Open" 1 "Closed" 2 "Reserved" 3 "Don't care / take no action";
VAL_ 2365428478 EngFuelShutoffVentCtrl 0 "Closed" 1 "Open" 2 "Reserved" 3 "Don't care / take no action";
VAL_ 2365428478 FuelPumpPrimerCtrl 0 "Deactivate" 1 "Activate" 2 "Reserved" 3 "Unavailable";
VAL_ 2362638078 MemoryLevelReq_5433 0 "No memory level request" 1 "Memory level 1 request" 2 "Memory level 2 request" 3 "Memory level 3 request" 4 "Memory level 4 request" 5 "Memory level 5 request" 6 "reserved" 7 "reserved" 8 "reserved" 9 "Store Memory level  1" 10 "Store Memory level  2" 11 "Store Memory level  3" 12 "Store Memory level  4" 13 "Store Memory level  5" 14 "Reserved" 15 "Don't care";
VAL_ 2362638078 ProhibitAASControl_5274 0 "No request " 1 "Request prohibit automatic air suspension control " 2 "Error indicator " 3 "Not available";
VAL_ 2362638078 SpdDependentLevelCtrlRq_5295 0 "Deactivate" 1 "Activate" 2 "Reserved" 3 "Don’t care/take no action";
VAL_ 2362638078 AllwLvlCtrlDuringBrakingCmd_5293 0 "Disallow level control during braking" 1 "Allow level control during braking" 2 "Reserved" 3 "Don’t' care/take no action";
VAL_ 2362638078 ProhibitAirSuspensionCtrl_3215 0 "No request " 1 "Request prohibit air suspension control " 2 "Error indicator " 3 "Not available";
VAL_ 2362638078 KneelingCmdRearAxle_1829 0 "Deactivate kneeling" 1 "Activate kneeling" 2 "Reserved" 3 "Don't care/take no action";
VAL_ 2362638078 KneelingCmdFrontAxle_1830 0 "Deactivate kneeling" 1 "Activate kneeling" 2 "Reserved" 3 "Don't care/take no action";
VAL_ 2362638078 LiftAxle2PosCmd_1828 0 "Lift axle position down / tag axle laden" 1 "Lift axle position up / tag axle unladen" 2 "Reserved" 3 "Don't care/take no action";
VAL_ 2362638078 LiftAxle1PosCmd_1752 0 "Lift axle position down / tag axle laden" 1 "Lift axle position up / tag axle unladen" 2 "Reserved" 3 "Don't care/take no action";
VAL_ 2362638078 LevelCtrlModeRq_1753 0 "Normal operation" 1 "Traction help, load transfer)" 2 "Load fixing" 3 "Pressure ratio 1" 4 "Pressure ratio 2" 5 "Optimum traction 1" 6 "Optimum traction 2" 7 "Traction help, load reduce" 8 "Exhaust bellows" 9 "Force to bumper level" 14 "Reserved" 15 "Don't care/take no action";
VAL_ 2362638078 NominalLevelRqRearAxle_1750 0 "No level request" 1 "Normal Level 1" 2 "Normal Level 2" 3 "Normal Level 3" 4 "Preset Level" 5 "Customer Level" 6 "Upper Level" 7 "Lower Level" 8 "Stop level change" 9 "Raise Request" 10 "Lower Request" 14 "Reserved" 15 "Don't care/take no action";
VAL_ 2362638078 NominalLevelRqFrontAxle_1751 0 "No level request" 1 "Normal Level 1" 2 "Normal Level 2" 3 "Normal Level 3" 4 "Preset Level" 5 "Customer Level" 6 "Upper Level" 7 "Lower Level" 8 "Stop level change" 9 "Raise Request" 10 "Lower Request" 14 "Reserved" 15 "Don't care/take no action";
VAL_ 2362638078 KneelingCtrlModeRq_1747 0 "Automatically actuated" 1 "Manually actuated" 2 "Reserved" 3 "Don't care/take no action";
VAL_ 2362638078 KneelingRqRightSide_1748 0 "No kneeling request" 1 "Kneeling request" 2 "Reserved" 3 "Don't care/take no action";
VAL_ 2362638078 KneelingRqLeftSide_1749 0 "No kneeling request" 1 "Kneeling request" 2 "Reserved" 3 "Don't care/take no action";
VAL_ 2362638078 AutomaticTractionHelp_2984 0 "Disable automatic traction help " 1 "Enable automatic traction help " 2 "Reserved" 3 "Don't care";
VAL_ 2365479678 MemoryLevel 0 "No memory level " 1 "Memory level 1 selected " 2 "Memory level 2 selected" 3 "Memory level 3 selected" 4 "Memory level 4 selected" 5 "Memory level 5 selected" 6 "reserved" 7 "reserved" 8 "reserved" 9 "Memory level  1 stored" 10 "Memory level  2 stored" 11 "Memory level  3 stored" 12 "Memory level  4 stored" 13 "Memory level  5 stored" 14 "Error indicator" 15 "not available";
VAL_ 2365479678 SuspensionCtrlRefusalInformation 0 "Actual request not refused" 1 "Axle load limit reached " 2 "Would exceed axle load limit" 3 "Bogie differential not locked" 4 "Above speed limit" 5 "Below speed limit" 6 "General reject" 7 "Requested level not available" 14 "Error" 15 "Not available";
VAL_ 2365479678 SpeedDependantLevelCtrlStatus 0 "Inactive" 1 "Active" 2 "Reserved" 3 "Don’t' care/take no action";
VAL_ 2365479678 AllwLevelCtrlDuringBrakingStatus 0 "Deactivated" 1 "Activated" 2 "Reserved" 3 "Don’t care/take no action";
VAL_ 2365479678 SuspensionRemoteCtrl2 0 "Not active" 1 "Active" 2 "Error" 3 "Not available";
VAL_ 2365479678 SuspensionRemoteCtrl1 0 "Not active" 1 "Active" 2 "Error" 3 "Not available";
VAL_ 2365479678 LiftAxle2Pos 0 "Lift axle position down / tag axle laden" 1 "Lift axle position up / tag axle unladen" 2 "Error" 3 "Not available";
VAL_ 2365479678 RearAxleInBumperRange 0 "Actual level out of bumper range" 1 "Actual level within bumper range" 2 "Error" 3 "Not available";
VAL_ 2365479678 FrontAxleInBumperRange 0 "Actual level out of bumper range" 1 "Actual level within bumper range" 2 "Error" 3 "Not available";
VAL_ 2365479678 LiftAxle1Pos 0 "Lift axle position down / tag axle laden" 1 "Lift axle position up / tag axle unladen" 2 "Error" 3 "Not available";
VAL_ 2365479678 DoorRelease 0 "Doors may not be opened" 1 "Doors may be opened" 2 "Error" 3 "Not available";
VAL_ 2365479678 VehicleMotionInhibit 0 "Vehicle may be moved" 1 "Vehicle motion is inhibited" 2 "Error" 3 "Not available";
VAL_ 2365479678 SecurityDevice 0 "Not active" 1 "Active" 2 "Error" 3 "Not available";
VAL_ 2365479678 LevelCtrlMode 0 "Normal operation" 1 "Traction help, load transfer)" 2 "Load fixing" 3 "Pressure ratio 1" 4 "Pressure ratio 2" 5 "Optimum traction 1" 6 "Optimum traction 2" 7 "Traction help, load reduce" 8 "Exhausting bellow function" 9 "Air suspension control prohibited" 10 "Automatic air suspension control prohibited" 11 "Force to bumper level request is in effect" 14 "Error" 15 "Not available";
VAL_ 2365479678 KneelingInformation 0 "Not active" 1 "Lowering active" 2 "Kneeling level reached" 3 "Lifting active" 4 "Kneeling aborted" 14 "Error" 15 "Not available";
VAL_ 2365479678 LiftingCtrlModeRearAxle 0 "Lifting not active" 1 "Lifting active" 2 "Error" 3 "Not available";
VAL_ 2365479678 LiftingCtrlModeFrontAxle 0 "Lifting not active" 1 "Lifting active" 2 "Error" 3 "Not available";
VAL_ 2365479678 LoweringCtrlModeRearAxle 0 "Lowering not active" 1 "Lowering active" 2 "Error" 3 "Not available";
VAL_ 2365479678 LoweringCtrlModeFrontAxle 0 "Lowering not active" 1 "Lowering active" 2 "Error" 3 "Not available";
VAL_ 2365479678 AboveNominalLevelRearAxle 0 "Not above" 1 "Above" 2 "Error" 3 "Not available";
VAL_ 2365479678 AboveNominalLevelFrontAxle 0 "Not above" 1 "Above" 2 "Error" 3 "Not available";
VAL_ 2365479678 BelowNominalLevelRearAxle 0 "Not below" 1 "Below" 2 "Error" 3 "Not available";
VAL_ 2365479678 BelowNominalLevelFrontAxle 0 "Not below" 1 "Below" 2 "Error" 3 "Not available";
VAL_ 2365479678 NominalLevelRearAxle 0 "Level not specified" 1 "Normal Level 1" 2 "Normal Level 2" 3 "Normal Level 3" 4 "Preset Level" 5 "Customer Level" 6 "Upper Level" 7 "Lower Level" 8 "Level change stopped" 9 "Raising" 10 "Lowering" 14 "Error" 15 "Not available";
VAL_ 2365479678 NominalLevelFrontAxle 0 "Level not specified" 1 "Normal Level 1" 2 "Normal Level 2" 3 "Normal Level 3" 4 "Preset Level" 5 "Customer Level" 6 "Upper Level" 7 "Lower Level" 8 "Level change stopped" 9 "Raising" 10 "Lowering" 14 "Error" 15 "Not available";
VAL_ 2566837758 Alt4Status 0 "Alternator 4 not charging" 1 "Alternator 4 charging" 2 "error" 3 "not available";
VAL_ 2566837758 Alt3Status 0 "Alternator 3 not charging" 1 "Alternator 3 charging" 2 "error" 3 "not available";
VAL_ 2566837758 Alt2Status 0 "Alternator 2 not charging" 1 "Alternator 2 charging" 2 "error" 3 "not available";
VAL_ 2566837758 Alt1Status 0 "Alternator 1 not charging" 1 "Alternator 1 charging" 2 "error" 3 "not available";
VAL_ 2566836478 TestIdentifier 247 "All scaled test results" 249 "Command Standard Test" 250 "Last Measured Scaled Results";
VAL_ 2565078782 TestIdentifier_1224 247 "All scaled test results" 249 "Command Standard Test" 250 "Last Measured Scaled Results";
VAL_ 2565078782 FailureModeIdentifier1_4149 0 "Above normal (most severe)" 1 "Below normal (most severe)" 2 "Data erratic" 3 "Voltage above normal" 4 "Voltage below normal" 5 "Current below normal" 6 "Current above normal" 7 "Mechanical system not responding" 8 "Abnormal frequency" 9 "Abnormal update rate" 10 "Abnormal rate of change" 11 "Root cause not known" 12 "Bad intelligent device" 13 "Out of calibration" 14 "Special intstructions" 15 "Above normal (least severe)" 16 "Above normal (moderately severe)" 17 "Below normal (least severe)" 18 "Below normal (moderately severe)" 19 "Received network data in error" 31 "Not available";
VAL_ 2566836222 FlashRedStopLamp 0 "Slow Flash" 1 "Fast Flash" 2 "Reserved" 3 "Unavailable / Do Not Flash";
VAL_ 2566836222 FlashProtectLamp 0 "Slow Flash" 1 "Fast Flash" 2 "Reserved" 3 "Unavailable / Do Not Flash";
VAL_ 2566836222 FlashMalfuncIndicatorLamp 0 "Slow Flash" 1 "Fast Flash" 2 "Class C DTC  " 3 "Unavailable / Do Not Flash";
VAL_ 2566836222 FlashAmberWarningLamp 0 "Slow Flash" 1 "Fast Flash" 2 "Reserved" 3 "Unavailable / Do Not Flash";
VAL_ 2566836222 MalfunctionIndicatorLampStatus 0 "Lamp Off" 1 "Lamp On" 2 "Short MIL for WWH OBD" 3 "Not available";
VAL_ 2566836222 RedStopLampState 0 "Lamp Off" 1 "Lamp On" 2 "Reserved" 3 "Not available";
VAL_ 2566836222 AmberWarningLampStatus 0 "Lamp Off" 1 "Lamp On" 2 "Reserved" 3 "Not available";
VAL_ 2566836222 ProtectLampStatus 0 "Lamp Off" 1 "Lamp On" 2 "Reserved" 3 "Not available";
VAL_ 2566835966 MisfireMonitoringSupport 0 "test not supported" 1 "test supported" 2 "Reserved" 3 "Not available";
VAL_ 2566835966 OBDCompliance 0 "Reserver for assignment by SAE" 1 "OBD II (California, ARB)" 2 "OBD (Federal, EPA)" 3 "OBD and OBD II" 4 "OBD I" 5 "Not intended to meet OBD II req." 6 "EOBD" 7 "EOBD and OBD II" 8 "EOBD and OBD" 9 "EOBD, OBD and OBD II" 10 "JOBD" 11 "JOBD and OBD II" 12 "JOBD and EOBD" 13 "JOBD, EOBD and OBD II" 14 "Heavy Duty Vehicles (EURO IV) B1" 15 "Heavy Duty Vehicles (EURO V) B2" 16 "Heavy Duty Vehicles (EURO EEC) C" 17 "EMD" 18 "EMD+" 19 "HD OBD P" 20 "HD OBD" 21 "WWH OBD" 22 "OBD II (California, ARB 07/08)" 23 "HD EOBD" 25 "OBD-M (SI-SD/I)";
VAL_ 2566835966 SecondAirSystemMonStatus 0 "TestComplete" 1 "TestNotComplete";
VAL_ 2566835966 EvaporativeSystemMonStatus 0 "TestComplete" 1 "TestNotComplete";
VAL_ 2566835966 ACSystemRefrigerantMonStatus 0 "TestComplete" 1 "TestNotComplete";
VAL_ 2566835966 OxygenSensorHeaterMonStatus 0 "TestComplete" 1 "TestNotComplete";
VAL_ 2566835966 OxygenSensorMonStatus 0 "test complete" 1 "test not complete";
VAL_ 2566835966 EGRSystemMonitoringStatus 0 "TestComplete" 1 "TestNotComplete";
VAL_ 2566835966 CatalystMonStatus 0 "TestComplete" 1 "TestNotComplete";
VAL_ 2566835966 ColdStartAidSystemMonStatus 0 "TestComplete" 1 "TestNotComplete";
VAL_ 2566835966 HeatedCatalystMonStatus 0 "TestComplete" 1 "TestNotComplete";
VAL_ 2566835966 CatalystMonSupp 0 "TestNotSupported" 1 "TestSupported";
VAL_ 2566835966 ColdStartAidSystemMonSupp 0 "TestNotSupported" 1 "TestSupported";
VAL_ 2566835966 HeatedCatalystMonSupp 0 "TestNotSupported" 1 "TestSupported";
VAL_ 2566835966 EvaporativeSystemMonSupp 0 "TestNotSupported" 1 "TestSupported";
VAL_ 2566835966 SecondAirSystemMonSupp 0 "TestNotSupported" 1 "TestSupported";
VAL_ 2566835966 ACSystemRefrigerantMonSupp 0 "TestNotSupported" 1 "TestSupported";
VAL_ 2566835966 OxygenSensorMonSupp 0 "TestNotSupported" 1 "TestSupported";
VAL_ 2566835966 OxygenSensorHeaterMonSupp 0 "TestNotSupported" 1 "TestSupported";
VAL_ 2566835966 EGRSystemMonitoringSupp 0 "TestNotSupported" 1 "TestSupported";
VAL_ 2566835966 MisfireMonitoringStatus 0 "test complete" 1 "test not complete";
VAL_ 2566835966 ComprehensiveCompMonStatus 0 "test complete" 1 "test not complete";
VAL_ 2566835966 FuelSystemMonitoringStatus 0 "test complete" 1 "test not complete";
VAL_ 2566835966 ComprehensiveComponentMonSupp 0 "test not supported" 1 "test supported" 2 "Reserved" 3 "Not available";
VAL_ 2566835966 FuelSystemMonitoringSupport 0 "test not supported" 1 "test supported";
VAL_ 2566764286 SPNSupportTypeSTR3 0 "Supported In Scaled Test Results" 1 "Not Supported In Scaled Test Results";
VAL_ 2566764286 SPNSupportTypeSTR2 0 "Supported In Scaled Test Results" 1 "Not Supported In Scaled Test Results";
VAL_ 2566764286 SPNSupportTypeEFF3 0 "Supported In Ex Freeze Frame" 1 "Not Supported In Ex Freeze Frame";
VAL_ 2566764286 SPNSupportTypeEFF2 0 "Supported In Ex Freeze Frame" 1 "Not Supported In Ex Freeze Frame";
VAL_ 2566764286 SPNSupportTypeDS3 0 "Supported In Data Stream" 1 "Not Supported In Data Stream";
VAL_ 2566764286 SPNSupportTypeDS2 0 "Supported In Data Stream" 1 "Not Supported In Data Stream";
VAL_ 2566764286 SPNSupportTypeSTR1 0 "Supported In Scaled Test Results" 1 "Not Supported In Scaled Test Results";
VAL_ 2566764286 SPNSupportTypeDS1 0 "Supported In Data Stream" 1 "Not Supported In Data Stream";
VAL_ 2566764286 SPNSupportTypeEFF1 0 "Supported In Ex Freeze Frame" 1 "Not Supported In Ex Freeze Frame";
VAL_ 2566764030 FlashRedStopLamp 0 "Slow Flash" 1 "Fast Flash" 2 "Reserved" 3 "Unavailable / Do Not Flash";
VAL_ 2566764030 FlashProtectLamp 0 "Slow Flash" 1 "Fast Flash" 2 "Reserved" 3 "Unavailable / Do Not Flash";
VAL_ 2566764030 FlashMalfuncIndicatorLamp 0 "Slow Flash" 1 "Fast Flash" 2 "Class C DTC  " 3 "Unavailable / Do Not Flash";
VAL_ 2566764030 FlashAmberWarningLamp 0 "Slow Flash" 1 "Fast Flash" 2 "Reserved" 3 "Unavailable / Do Not Flash";
VAL_ 2566764030 MalfunctionIndicatorLampStatus 0 "Lamp Off" 1 "Lamp On" 2 "Short MIL for WWH OBD" 3 "Not available";
VAL_ 2566764030 RedStopLampState 0 "Lamp Off" 1 "Lamp On" 2 "Reserved" 3 "Not available";
VAL_ 2566764030 AmberWarningLampStatus 0 "Lamp Off" 1 "Lamp On" 2 "Reserved" 3 "Not available";
VAL_ 2566764030 ProtectLampStatus 0 "Lamp Off" 1 "Lamp On" 2 "Reserved" 3 "Not available";
